VERSION ""

NS_ :

BS_:

BU_: VCM SCIM IC CCM

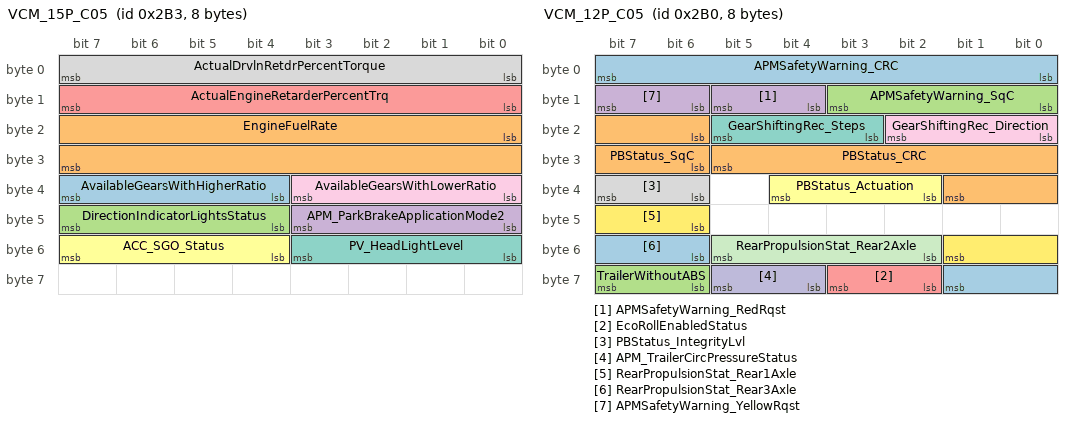
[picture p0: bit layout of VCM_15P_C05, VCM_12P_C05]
BO_ 691 VCM_15P_C05: 8 VCM
 SG_ AvailableGearsWithHigherRatio : 36|4@1+ (1,0) [0|15] "Count"  IC
 SG_ EngineFuelRate : 16|16@1+ (0.05,0) [0|3276.75] "l_per_h"  IC
 SG_ DirectionIndicatorLightsStatus : 44|4@1+ (1,0) [0|0] ""  IC
 SG_ APM_ParkBrakeApplicationMode2 : 40|4@1+ (1,0) [0|0] ""  IC
 SG_ ActualEngineRetarderPercentTrq : 8|8@1+ (1,-125) [-125|130] "Percent"  IC
 SG_ ACC_SGO_Status : 52|4@1+ (1,0) [0|0] ""  IC
 SG_ PV_HeadLightLevel : 48|4@1+ (1,-7) [-7|8] "NotApplicable"  IC
 SG_ ActualDrvlnRetdrPercentTorque : 0|8@1+ (1,-125) [-125|130] "Percent"  IC
 SG_ AvailableGearsWithLowerRatio : 32|4@1+ (1,0) [0|15] "Count"  IC

BO_ 690 VCM_14P_C05: 8 VCM
 SG_ SetHSAOperation : 49|3@1+ (1,0) [0|0] ""  IC
 SG_ PS_FogLightFront : 12|2@1+ (1,0) [0|0] ""  IC
 SG_ CACCStatus : 43|3@1+ (1,0) [0|0] ""  IC
 SG_ Cab12VSupplyStatus : 6|2@1+ (1,0) [0|0] ""  IC
 SG_ TransmissionDrivingMode : 22|3@1+ (1,0) [0|0] ""  IC
 SG_ LowAirPressureAlert : 10|2@1+ (1,0) [0|0] ""  IC
 SG_ TemporaryRSLSwitchStatus : 4|2@1+ (1,0) [0|0] ""  IC
 SG_ BatterySOCAlertRawData_rqst : 37|3@1+ (1,0) [0|0] ""  IC,CCM
 SG_ BatteryTempAlertRawData_rqst : 25|3@1+ (1,0) [0|0] ""  IC
 SG_ BrakeTemperatureWarning : 14|2@1+ (1,0) [0|0] ""  IC
 SG_ WheelSlipControllerMode : 16|3@1+ (1,0) [0|0] ""  IC
 SG_ Rainsensor_Indication : 0|2@1+ (1,0) [0|0] ""  IC
 SG_ ESCHealthStatus : 2|2@1+ (1,0) [0|0] ""  IC
 SG_ TLInflationAcceptance_stat : 31|3@1+ (1,0) [0|0] ""  IC
 SG_ AutoLoadCutOffState : 34|3@1+ (1,0) [0|0] ""  IC
 SG_ TransmissionOilTempHigh : 55|3@1+ (1,0) [0|0] ""  IC
 SG_ ECSLimpHomeNotification : 28|3@1+ (1,0) [0|0] ""  IC
 SG_ EqualizerUnbalance : 19|3@1+ (1,0) [0|0] ""  IC
 SG_ AutGearSplitPosition : 52|3@1+ (1,0) [0|0] ""  IC
 SG_ BatterySOCAlert_rqst : 46|3@1+ (1,0) [0|0] ""  IC
 SG_ DriveModeSwitchUserOverride : 58|3@1+ (1,0) [0|0] ""  IC
 SG_ BatteryTempAlert_rqst : 40|3@1+ (1,0) [0|0] ""  IC
 SG_ TrailerEBSFault : 8|2@1+ (1,0) [0|0] ""  IC

BO_ 689 VCM_13P_C05: 8 VCM
 SG_ ParkHeaterTimerReleased_stat : 54|2@1+ (1,0) [0|0] ""  CCM
 SG_ Trail2TPMLostCom : 2|2@1+ (1,0) [0|0] ""  IC
 SG_ BrakeInterlockStatus : 42|2@1+ (1,0) [0|0] ""  IC
 SG_ AutoWheelBrakesDownshiftSugges : 36|2@1+ (1,0) [0|0] ""  IC
 SG_ RearAxle2DiffLock_stat : 34|2@1+ (1,0) [0|0] ""  IC
 SG_ CentralRearDiffLock_stat : 16|2@1+ (1,0) [0|0] ""  IC
 SG_ TransmissionBrakeMode : 56|2@1+ (1,0) [0|0] ""  IC
 SG_ PS_HeadLightAdjustment : 14|2@1+ (1,0) [0|0] ""  IC
 SG_ ReducedLoadMode_stat : 62|2@1+ (1,0) [0|0] ""  IC,CCM
 SG_ FrontWheelDifflockRequest : 6|2@1+ (1,0) [0|0] ""  IC
 SG_ ABSEBSAmberWarningSignal : 44|2@1+ (1,0) [0|0] ""  IC
 SG_ DifferentialLockStateFrAxle1 : 32|2@1+ (1,0) [0|0] ""  IC
 SG_ Trail1TPMLostCom : 12|2@1+ (1,0) [0|0] ""  IC
 SG_ TrailerInflationPossible_stat : 50|2@1+ (1,0) [0|0] ""  IC
 SG_ DrivelineRetarderStat : 24|2@1+ (1,0) [0|0] ""  IC
 SG_ PS_FogLightRear : 4|2@1+ (1,0) [0|0] ""  IC
 SG_ PS_MainBeam : 22|2@1+ (1,0) [0|0] ""  IC
 SG_ DeCompActive : 26|2@1+ (1,0) [0|0] ""  IC
 SG_ ECSManStandbyStatus : 30|2@1+ (1,0) [0|0] ""  IC
 SG_ AutoPBRelease_stat : 46|2@1+ (1,0) [0|0] ""  IC
 SG_ Trail4TPMLostCom : 28|2@1+ (1,0) [0|0] ""  IC
 SG_ EBSRedWarningSignal : 40|2@1+ (1,0) [0|0] ""  IC
 SG_ DifferentialLockStateCentral : 52|2@1+ (1,0) [0|0] ""  IC
 SG_ RearAxle3DiffLock_stat : 20|2@1+ (1,0) [0|0] ""  IC
 SG_ AntiLockBrakingActive : 10|2@1+ (1,0) [0|0] ""  IC
 SG_ RearAxle1DiffLock_stat : 0|2@1+ (1,0) [0|0] ""  IC
 SG_ Trail5TPMLostCom : 48|2@1+ (1,0) [0|0] ""  IC
 SG_ PS_PositionLight : 58|2@1+ (1,0) [0|0] ""  IC
 SG_ BatteryCapacity_Ack : 8|2@1+ (1,0) [0|0] ""  IC
 SG_ Trail3TPMLostCom : 60|2@1+ (1,0) [0|0] ""  IC
 SG_ ParkBrakeWorkshopMode : 18|2@1+ (1,0) [0|0] ""  IC
 SG_ LowTempClutchInfo : 38|2@1+ (1,0) [0|0] ""  IC

BO_ 688 VCM_12P_C05: 8 VCM
 SG_ APMSafetyWarning_CRC : 0|8@1+ (1,0) [0|255] ""  IC
 SG_ PBStatus_CRC : 22|8@1+ (1,0) [0|255] ""  IC
 SG_ TrailerWithoutABS : 62|2@1+ (1,0) [0|0] ""  IC
 SG_ APMSafetyWarning_RedRqst : 12|2@1+ (1,0) [0|0] ""  IC
 SG_ EcoRollEnabledStatus : 58|2@1+ (1,0) [0|0] ""  IC
 SG_ PBStatus_Actuation : 34|3@1+ (1,0) [0|0] ""  IC
 SG_ GearShiftingRec_Steps : 19|3@1+ (1,0) [0|0] ""  IC
 SG_ PBStatus_IntegrityLvl : 38|2@1+ (1,0) [0|0] ""  IC
 SG_ GearShiftingRec_Direction : 16|3@1+ (1,0) [0|0] ""  IC
 SG_ APM_TrailerCircPressureStatus : 60|2@1+ (1,0) [0|0] ""  IC
 SG_ RearPropulsionStat_Rear2Axle : 50|4@1+ (1,0) [0|0] ""  IC
 SG_ RearPropulsionStat_Rear1Axle : 46|4@1+ (1,0) [0|0] ""  IC
 SG_ RearPropulsionStat_Rear3Axle : 54|4@1+ (1,0) [0|0] ""  IC
 SG_ PBStatus_SqC : 30|4@1+ (1,0) [0|14] "NotApplicable"  IC
 SG_ APMSafetyWarning_SqC : 8|4@1+ (1,0) [0|14] "NotApplicable"  IC
 SG_ APMSafetyWarning_YellowRqst : 14|2@1+ (1,0) [0|0] ""  IC

BO_ 394 VCM_11P_C05: 8 VCM
 SG_ LongitudinalAcceleration : 0|16@1+ (0.00048828125,-15.687) [-15.687|16.31251171875] "m_per_s_squared"  IC
 SG_ CCSetSpeed : 16|16@1+ (0.00390625,0) [0|255.99609375] "Km_per_h"  IC

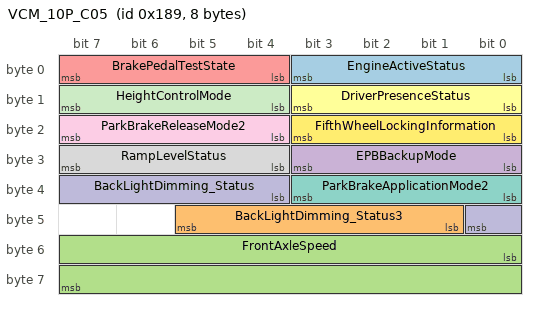
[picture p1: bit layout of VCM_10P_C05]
BO_ 393 VCM_10P_C05: 8 VCM
 SG_ EngineActiveStatus : 0|4@1+ (1,0) [0|0] ""  IC
 SG_ BackLightDimming_Status3 : 41|5@1+ (1,0) [0|0] ""  IC
 SG_ FrontAxleSpeed : 48|16@1+ (0.00390625,0) [0|255.99609375] "Km_per_h"  IC
 SG_ EPBBackupMode : 24|4@1+ (1,0) [0|0] ""  IC
 SG_ BrakePedalTestState : 4|4@1+ (1,0) [0|0] ""  IC
 SG_ DriverPresenceStatus : 8|4@1+ (1,0) [0|0] ""  IC
 SG_ ParkBrakeApplicationMode2 : 32|4@1+ (1,0) [0|0] ""  IC
 SG_ RampLevelStatus : 28|4@1+ (1,0) [0|0] ""  IC
 SG_ ParkBrakeReleaseMode2 : 20|4@1+ (1,0) [0|0] ""  IC
 SG_ BackLightDimming_Status : 36|5@1+ (1,0) [0|0] ""  IC
 SG_ HeightControlMode : 12|4@1+ (1,0) [0|0] ""  IC
 SG_ FifthWheelLockingInformation : 16|4@1+ (1,0) [0|0] ""  IC

BO_ 392 VCM_09P_C05: 8 VCM
 SG_ FirstAxleLowerPrioSelected : 48|3@1+ (1,0) [0|0] ""  IC
 SG_ ESCState : 24|3@1+ (1,0) [0|0] ""  IC
 SG_ KneelingInformation : 60|4@1+ (1,0) [0|0] ""  IC
 SG_ TrailerTest_stat : 42|3@1+ (1,0) [0|0] ""  IC
 SG_ ThreePosDifflockSwitch_stat : 3|3@1+ (1,0) [0|0] ""  IC
 SG_ HillHolderMode : 36|3@1+ (1,0) [0|0] ""  IC
 SG_ RampHeightOutsideTargetRange : 21|3@1+ (1,0) [0|0] ""  IC
 SG_ ShortStopHeater_status : 39|3@1+ (1,0) [0|0] ""  CCM
 SG_ LuggageAjar_stat : 15|3@1+ (1,0) [0|0] ""  IC
 SG_ LoadDistributionRequestedACK : 12|3@1+ (1,0) [0|0] ""  IC
 SG_ StretchBrake_Stat : 54|3@1+ (1,0) [0|0] ""  IC
 SG_ MirrorHeatingMode : 9|3@1+ (1,0) [0|0] ""  IC,CCM
 SG_ ESCStatus : 6|3@1+ (1,0) [0|0] ""  IC
 SG_ DriverRetarderRequest : 30|3@1+ (1,0) [0|0] ""  IC
 SG_ PBReleaseAcceptance_stat : 18|3@1+ (1,0) [0|0] ""  IC
 SG_ PSWindowPosition : 0|3@1+ (1,0) [0|0] ""  CCM
 SG_ RemoteParkingClimateRqst : 57|3@1+ (1,0) [0|0] ""  CCM
 SG_ AutoDefogmode_Status : 33|3@1+ (1,0) [0|0] ""  IC
 SG_ RideHeightOutsideTargetRange : 27|3@1+ (1,0) [0|0] ""  IC
 SG_ DriveLevelPosUserInteraction : 45|3@1+ (1,0) [0|0] ""  IC
 SG_ HillStartAidStatus : 51|3@1+ (1,0) [0|0] ""  IC

BO_ 391 VCM_08P_C05: 8 VCM
 SG_ AcceleratorPedalTestStatus : 38|3@1+ (1,0) [0|0] ""  IC
 SG_ AutoDefogmode_Selection : 14|3@1+ (1,0) [0|0] ""  CCM
 SG_ ESCDriverReq : 41|3@1+ (1,0) [0|0] ""  IC
 SG_ UnevenLoadWarning : 12|2@1+ (1,0) [0|0] ""  IC
 SG_ RrInterAxlDiffLockActvnFuncReq : 4|2@1+ (1,0) [0|0] ""  IC
 SG_ DoorsAjar_stat : 44|3@1+ (1,0) [0|0] ""  IC
 SG_ ABSManAutoInhibitionStat : 50|3@1+ (1,0) [0|0] ""  IC
 SG_ RrInterAxlDiffLockActvnDrvrReq : 2|2@1+ (1,0) [0|0] ""  IC
 SG_ ACMode_Selection : 17|3@1+ (1,0) [0|0] ""  CCM
 SG_ EngineOilTempHigh : 59|3@1+ (1,0) [0|0] ""  IC
 SG_ StartupProhibitStatus : 0|2@1+ (1,0) [0|0] ""  IC
 SG_ AuxBrakesDwngrdModeInd_rqst : 26|3@1+ (1,0) [0|0] ""  IC
 SG_ ElectricalLoadReduction_rqst : 32|3@1+ (1,0) [0|0] ""  CCM
 SG_ ACmode_Status : 56|3@1+ (1,0) [0|0] ""  IC
 SG_ LoadDistributionChangeACK : 20|3@1+ (1,0) [0|0] ""  IC
 SG_ FerryFunctionStatus : 29|3@1+ (1,0) [0|0] ""  IC
 SG_ ClutchOverloadStatus : 10|2@1+ (1,0) [0|0] ""  IC
 SG_ AutoBlowerLevel_Selection : 23|3@1+ (1,0) [0|0] ""  CCM
 SG_ RollerBenchModeStatus : 6|2@1+ (1,0) [0|0] ""  IC
 SG_ LoadDistributionALDChangeACK : 35|3@1+ (1,0) [0|0] ""  IC
 SG_ EngineSpeedControlStatus : 47|3@1+ (1,0) [0|0] ""  IC
 SG_ AutoBlowerLevel_Status : 53|3@1+ (1,0) [0|0] ""  IC
 SG_ DTCActive : 8|2@1+ (1,0) [0|0] ""  IC

BO_ 390 VCM_07P_C05: 8 VCM
 SG_ PS_SevereEngAndBrkOverspdWarn : 6|2@1+ (1,0) [0|0] ""  IC
 SG_ RearFog_Indication : 14|2@1+ (1,0) [0|0] ""  SCIM
 SG_ SasAdaptationInProgress : 46|2@1+ (1,0) [0|0] ""  IC
 SG_ SplitBoxDifflockActvnDrvrRqst : 50|2@1+ (1,0) [0|0] ""  IC
 SG_ EcoRollActiveStatus : 36|2@1+ (1,0) [0|0] ""  IC
 SG_ PloughLampModeStatus : 40|2@1+ (1,0) [0|0] ""  IC
 SG_ RrRrItrWhlDiffLckActvnDrvrReq : 26|2@1+ (1,0) [0|0] ""  IC
 SG_ AQSMode_Selection : 0|2@1+ (1,0) [0|0] ""  CCM
 SG_ DrvrRetarderBrakeProgram_rqst : 62|2@1+ (1,0) [0|0] ""  IC
 SG_ PS_EngOverSpeedSevereWarning : 38|2@1+ (1,0) [0|0] ""  IC
 SG_ ParkBrakeReleasePossible_stat : 32|2@1+ (1,0) [0|0] ""  IC
 SG_ StoreIdleValue : 34|2@1+ (1,0) [0|0] ""  IC
 SG_ AutRrAxleDiffLockActvnDrvrReq : 42|2@1+ (1,0) [0|0] ""  IC
 SG_ TransmLowRangeSenseSwitch : 28|2@1+ (1,0) [0|0] ""  IC
 SG_ PBStatusDisplay_cmd : 44|2@1+ (1,0) [0|0] ""  IC
 SG_ AutoRearAxleDiffLockFnc_stat : 56|2@1+ (1,0) [0|0] ""  IC
 SG_ PoorBrakePerformanceWarning : 8|2@1+ (1,0) [0|0] ""  IC
 SG_ AQSmode_Status : 22|2@1+ (1,0) [0|0] ""  IC
 SG_ CCIOM_ParkBrakeAlert : 4|2@1+ (1,0) [0|0] ""  IC
 SG_ FrontParkBrakeOverrideInd : 52|2@1+ (1,0) [0|0] ""  IC
 SG_ ProhibitControlStatus : 10|2@1+ (1,0) [0|0] ""  IC
 SG_ PositionLightRequest_status : 2|2@1+ (1,0) [0|0] ""  IC
 SG_ DoubleFrontAxleSteeringWarning : 54|2@1+ (1,0) [0|0] ""  IC
 SG_ TrailerABSStatus : 20|2@1+ (1,0) [0|0] ""  IC
 SG_ LoadCutOffIndication_cmd : 60|2@1+ (1,0) [0|0] ""  IC
 SG_ PtosStatus : 12|2@1+ (1,0) [0|0] ""  CCM
 SG_ REM_PhoneButtonInd_cmd : 58|2@1+ (1,0) [0|0] ""  IC
 SG_ TrailerBrake_Stat : 48|2@1+ (1,0) [0|0] ""  IC
 SG_ SEM2_PhoneButtonInd_cmd : 30|2@1+ (1,0) [0|0] ""  IC
 SG_ GearRangeUnengaged : 16|2@1+ (1,0) [0|0] ""  IC
 SG_ ABSOffRoadStatus : 24|2@1+ (1,0) [0|0] ""  IC
 SG_ DrvrRetarderBrakeBlending_rqst : 18|2@1+ (1,0) [0|0] ""  IC

BO_ 389 VCM_06P_C05: 8 VCM
 SG_ XPRGSystemCap_Priority : 12|3@1+ (1,0) [0|0] ""  IC
 SG_ XPRGSystemCap_AllowedRelInhibit : 15|1@1+ (1,0) [0|0] ""  IC
 SG_ PHTimerRqstAck_Minutes : 24|8@1+ (1,0) [0|255] "min"  CCM
 SG_ RearAxleDiffLockActvnDrvrReq : 56|2@1+ (1,0) [0|0] ""  IC
 SG_ FrRrItrWhlDiffLckActvnDrvrReq : 46|2@1+ (1,0) [0|0] ""  IC
 SG_ XPRGSystemCap_AllowedGradCtrlTc : 19|1@1+ (1,0) [0|0] ""  IC
 SG_ XPRGSystemCap_AllowedGradCtrlTl : 17|1@1+ (1,0) [0|0] ""  IC
 SG_ RegenInhibDueHeight : 48|2@1+ (1,0) [0|0] ""  IC
 SG_ PHTimerRqstAck_Hours : 32|8@1+ (1,0) [0|255] "h"  CCM
 SG_ PoorAirPressureInfo : 60|2@1+ (1,0) [0|0] ""  IC
 SG_ XPRGSystemCap_AllowedPBApp : 21|1@1+ (1,0) [0|0] ""  IC
 SG_ XRSLControllerMode : 52|2@1+ (1,0) [0|0] ""  IC
 SG_ XPRGSystemCap_CRC : 0|8@1+ (1,0) [0|255] ""  IC
 SG_ XPRGSystemCap_AllowedInflation : 20|1@1+ (1,0) [0|0] ""  IC
 SG_ XPRGSystemCap_SqC : 8|4@1+ (1,0) [0|14] "NotApplicable"  IC
 SG_ PHTimerRqstAck_DayOfWeekRq : 40|4@1+ (1,0) [0|0] ""  CCM
 SG_ VIN_rqst : 62|1@1+ (1,0) [0|0] ""  IC
 SG_ PHTimerRqstAck_CurrentOp : 44|2@1+ (1,0) [0|0] ""  CCM
 SG_ PS_EngineBrakeOverSpeedWarning : 58|2@1+ (1,0) [0|0] ""  IC
 SG_ XPRGSystemCap_AllowedDeflation : 22|1@1+ (1,0) [0|0] ""  IC
 SG_ XPRGSystemCap_AllowedInfInhibit : 16|1@1+ (1,0) [0|0] ""  IC
 SG_ TrcnCtrlSlipperyRoadWarning : 50|2@1+ (1,0) [0|0] ""  IC
 SG_ XPRGSystemCap_AllowedPBRel : 18|1@1+ (1,0) [0|0] ""  IC
 SG_ TransmissionAirPressureLow : 54|2@1+ (1,0) [0|0] ""  IC

BO_ 158 VCM_05P_C05: 8 VCM
 SG_ SecuredNeutralPosition : 38|2@1+ (1,0) [0|0] ""  IC
 SG_ MirrorSelectLeftWideBtn_stat : 28|2@1+ (1,0) [0|0] ""  IC
 SG_ Recirc_ButtonStatus : 6|2@1+ (1,0) [0|0] ""  IC
 SG_ AirFlowSelectionUpBtn_stat : 18|2@1+ (1,0) [0|0] ""  IC
 SG_ BunkH1AudioOnOff_ButtonStatus : 30|2@1+ (1,0) [0|0] ""  IC
 SG_ AC_ButtonStatus : 42|2@1+ (1,0) [0|0] ""  IC
 SG_ OverSteerGuidanceStatus : 10|2@1+ (1,0) [0|0] ""  IC
 SG_ MirrorSelectLeftMainBtn_stat : 44|2@1+ (1,0) [0|0] ""  IC
 SG_ LECM_CabClim_Auto_BtnStat : 36|2@1+ (1,0) [0|0] ""  IC
 SG_ ParkBrakeAlert : 56|2@1+ (1,0) [0|0] ""  IC
 SG_ LECM_Display_Navi_OK_BtnStat : 20|2@1+ (1,0) [0|0] ""  IC
 SG_ LECM_CabClim_AC_BtnStat : 46|2@1+ (1,0) [0|0] ""  IC
 SG_ LECMCabClimSetTempSelectGuiReq : 22|2@1+ (1,0) [0|0] ""  IC
 SG_ MirrorSelectRightMainBtn_stat : 50|2@1+ (1,0) [0|0] ""  IC
 SG_ DaytimeRunningLight_Indication : 24|2@1+ (1,0) [0|0] ""  SCIM
 SG_ DrivingLight_Indication : 58|2@1+ (1,0) [0|0] ""  SCIM
 SG_ FrontFog_Indication : 32|2@1+ (1,0) [0|0] ""  SCIM
 SG_ Auto_ButtonStatus : 48|2@1+ (1,0) [0|0] ""  IC
 SG_ KeyfobPreTripButtonStatus : 4|2@1+ (1,0) [0|0] ""  IC
 SG_ MirrorSelectRightWideBtn_stat : 26|2@1+ (1,0) [0|0] ""  IC
 SG_ ParkingLight_Indication : 2|2@1+ (1,0) [0|0] ""  SCIM
 SG_ DrivingLightPlus_Indication : 60|2@1+ (1,0) [0|0] ""  SCIM
 SG_ BlackPanelMode_ButtonStatus : 14|2@1+ (1,0) [0|0] ""  IC
 SG_ ParkHeaterCooler_ButtonStatus : 16|2@1+ (1,0) [0|0] ""  IC
 SG_ LECM_CabClim_FrPwr_BtnStat : 34|2@1+ (1,0) [0|0] ""  IC
 SG_ LECM_CabClim_Pwr_BtnStat : 0|2@1+ (1,0) [0|0] ""  IC
 SG_ AirFlowSelectionFrontBtn_stat : 12|2@1+ (1,0) [0|0] ""  IC
 SG_ BlackPanelMode_ButtonStatus3 : 8|2@1+ (1,0) [0|0] ""  IC
 SG_ LECM_CabClim_Sync_GuiReq : 40|2@1+ (1,0) [0|0] ""  IC
 SG_ LiftAxle1AutoLiftSelected : 54|2@1+ (1,0) [0|0] ""  IC
 SG_ LECM_Ent_OnOff_BtnStat : 52|2@1+ (1,0) [0|0] ""  IC

BA_DEF_ BO_  "GenMsgStartDelayTime" INT 0 0;
BA_DEF_ BO_  "GenMsgDelayTime" INT 0 0;
BA_DEF_ BO_  "GenMsgCycleTime" INT 0 0;
BA_DEF_ BO_  "GenMsgSendType" ENUM  "Cyclic","NotUsed","NotUsed","NotUsed","NotUsed","NotUsed","NotUsed","IfActive","NoMsgSendType","NotUsed";
BA_DEF_ SG_  "GenSigStartValue" INT 0 0;
BA_DEF_ SG_  "GenSigCycleTimeActive" INT 0 0;
BA_DEF_ SG_  "GenSigCycleTime" INT 0 0;
BA_DEF_ SG_  "GenSigSendType" ENUM  "Cyclic","OnWrite","OnWriteWithRepetition","OnChange","OnChangeWithRepetition","IfActive","IfActiveWithRepetition","NoSigSendType","NotUsed","NotUsed","NotUsed","NotUsed","NotUsed";
BA_DEF_ BO_  "VFrameFormat" ENUM  "StandardCAN","ExtendedCAN","reserved","J1939PG","reserved","reserved","reserved","reserved","reserved","reserved","reserved","reserved","reserved","reserved","StandardCAN_FD","ExtendedCAN_FD";
BA_DEF_ SG_  "SigType" ENUM  "Default","Range","RangeSigned","ASCII","Discrete","Control","ReferencePGN","DTC","StringDelimiter","StringLength","StringLengthControl";
BA_DEF_ BO_  "NmAsrMessage" ENUM  "No","Yes";
BA_DEF_ SG_  "NeedsUpdateBit" ENUM  "No","Yes";
BA_DEF_ SG_  "MmAnSignal" ENUM  "No","Yes";
BA_DEF_ SG_  "GenSigMaxLatency" INT 0 65535;
BA_DEF_ SG_  "GenSigILSupport" ENUM  "Yes","No";
BA_DEF_ BO_  "GenMsgILSupport" ENUM  "No","Yes";
BA_DEF_ SG_  "E2EProfile" STRING ;
BA_DEF_ SG_  "E2EDataLength" INT 0 65535;
BA_DEF_ SG_  "E2EDataId" INT 0 65535;
BA_DEF_ BO_  "DiagUUDTResponse" ENUM  "No","Yes";
BA_DEF_ BO_  "DiagState" ENUM  "No","Yes";
BA_DEF_ BO_  "DiagResponse" ENUM  "No","Yes";
BA_DEF_ BO_  "DiagRequest" ENUM  "No","Yes";
BA_DEF_ BO_  "DiagConnection" HEX 0 65535;
BA_DEF_ BO_  "CanTpFcFrameId" HEX 0 2147483647;
BA_DEF_ BO_  "CanTpBs" INT 0 255;
BA_DEF_REL_ BU_SG_REL_  "GenSigTimeoutTime" INT 0 65535;
BA_DEF_REL_ BU_SG_REL_  "GenSigFirstTimeoutTime" INT 0 65535;
BA_DEF_DEF_  "GenMsgStartDelayTime" 0;
BA_DEF_DEF_  "GenMsgDelayTime" 0;
BA_DEF_DEF_  "GenMsgCycleTime" 0;
BA_DEF_DEF_  "GenMsgSendType" "Cyclic";
BA_DEF_DEF_  "GenSigStartValue" 0;
BA_DEF_DEF_  "GenSigCycleTimeActive" 0;
BA_DEF_DEF_  "GenSigCycleTime" 0;
BA_DEF_DEF_  "GenSigSendType" "Cyclic";
BA_DEF_DEF_  "VFrameFormat" "ExtendedCAN";
BA_DEF_DEF_  "SigType" "Default";
BA_DEF_DEF_  "NmAsrMessage" "No";
BA_DEF_DEF_  "NeedsUpdateBit" "No";
BA_DEF_DEF_  "MmAnSignal" "No";
BA_DEF_DEF_  "GenSigMaxLatency" 0;
BA_DEF_DEF_  "GenSigILSupport" "Yes";
BA_DEF_DEF_  "GenMsgILSupport" "Yes";
BA_DEF_DEF_  "E2EProfile" "none";
BA_DEF_DEF_  "E2EDataLength" 0;
BA_DEF_DEF_  "E2EDataId" 0;
BA_DEF_DEF_  "DiagUUDTResponse" "No";
BA_DEF_DEF_  "DiagState" "No";
BA_DEF_DEF_  "DiagResponse" "No";
BA_DEF_DEF_  "DiagRequest" "No";
BA_DEF_DEF_  "DiagConnection" 0;
BA_DEF_DEF_  "CanTpFcFrameId" 2147483647;
BA_DEF_DEF_  "CanTpBs" 255;
BA_DEF_DEF_REL_ "GenSigTimeoutTime" 0;
BA_DEF_DEF_REL_ "GenSigFirstTimeoutTime" 0;
BA_ "VFrameFormat" BO_ 691 0;
BA_ "GenMsgCycleTime" BO_ 691 100;
BA_ "VFrameFormat" BO_ 690 0;
BA_ "GenMsgCycleTime" BO_ 690 100;
BA_ "VFrameFormat" BO_ 689 0;
BA_ "GenMsgCycleTime" BO_ 689 100;
BA_ "VFrameFormat" BO_ 688 0;
BA_ "GenMsgCycleTime" BO_ 688 100;
BA_ "VFrameFormat" BO_ 394 0;
BA_ "GenMsgCycleTime" BO_ 394 50;
BA_ "VFrameFormat" BO_ 393 0;
BA_ "GenMsgCycleTime" BO_ 393 50;
BA_ "VFrameFormat" BO_ 392 0;
BA_ "GenMsgCycleTime" BO_ 392 50;
BA_ "VFrameFormat" BO_ 391 0;
BA_ "GenMsgCycleTime" BO_ 391 50;
BA_ "VFrameFormat" BO_ 390 0;
BA_ "GenMsgCycleTime" BO_ 390 50;
BA_ "VFrameFormat" BO_ 389 0;
BA_ "GenMsgCycleTime" BO_ 389 50;
BA_ "VFrameFormat" BO_ 158 0;
BA_ "GenMsgCycleTime" BO_ 158 20;
BA_ "GenSigCycleTime" SG_ 691 AvailableGearsWithHigherRatio 100;
BA_ "GenSigCycleTimeActive" SG_ 691 AvailableGearsWithHigherRatio 100;
BA_ "GenSigStartValue" SG_ 691 AvailableGearsWithHigherRatio 15;
BA_ "GenSigMaxLatency" SG_ 691 AvailableGearsWithHigherRatio 100;
BA_ "GenSigCycleTime" SG_ 691 EngineFuelRate 100;
BA_ "GenSigCycleTimeActive" SG_ 691 EngineFuelRate 100;
BA_ "GenSigStartValue" SG_ 691 EngineFuelRate 65535;
BA_ "GenSigMaxLatency" SG_ 691 EngineFuelRate 100;
BA_ "GenSigCycleTime" SG_ 691 DirectionIndicatorLightsStatus 100;
BA_ "GenSigCycleTimeActive" SG_ 691 DirectionIndicatorLightsStatus 100;
BA_ "GenSigStartValue" SG_ 691 DirectionIndicatorLightsStatus 15;
BA_ "GenSigMaxLatency" SG_ 691 DirectionIndicatorLightsStatus 100;
BA_ "GenSigCycleTime" SG_ 691 APM_ParkBrakeApplicationMode2 100;
BA_ "GenSigCycleTimeActive" SG_ 691 APM_ParkBrakeApplicationMode2 100;
BA_ "GenSigStartValue" SG_ 691 APM_ParkBrakeApplicationMode2 15;
BA_ "GenSigMaxLatency" SG_ 691 APM_ParkBrakeApplicationMode2 100;
BA_ "GenSigCycleTime" SG_ 691 ActualEngineRetarderPercentTrq 100;
BA_ "GenSigCycleTimeActive" SG_ 691 ActualEngineRetarderPercentTrq 100;
BA_ "GenSigStartValue" SG_ 691 ActualEngineRetarderPercentTrq 255;
BA_ "GenSigMaxLatency" SG_ 691 ActualEngineRetarderPercentTrq 100;
BA_ "GenSigCycleTime" SG_ 691 ACC_SGO_Status 100;
BA_ "GenSigCycleTimeActive" SG_ 691 ACC_SGO_Status 100;
BA_ "GenSigStartValue" SG_ 691 ACC_SGO_Status 15;
BA_ "GenSigMaxLatency" SG_ 691 ACC_SGO_Status 100;
BA_ "GenSigCycleTime" SG_ 691 PV_HeadLightLevel 100;
BA_ "GenSigCycleTimeActive" SG_ 691 PV_HeadLightLevel 100;
BA_ "GenSigStartValue" SG_ 691 PV_HeadLightLevel 15;
BA_ "GenSigMaxLatency" SG_ 691 PV_HeadLightLevel 100;
BA_ "GenSigCycleTime" SG_ 691 ActualDrvlnRetdrPercentTorque 100;
BA_ "GenSigCycleTimeActive" SG_ 691 ActualDrvlnRetdrPercentTorque 100;
BA_ "GenSigStartValue" SG_ 691 ActualDrvlnRetdrPercentTorque 255;
BA_ "GenSigMaxLatency" SG_ 691 ActualDrvlnRetdrPercentTorque 100;
BA_ "GenSigCycleTime" SG_ 691 AvailableGearsWithLowerRatio 100;
BA_ "GenSigCycleTimeActive" SG_ 691 AvailableGearsWithLowerRatio 100;
BA_ "GenSigStartValue" SG_ 691 AvailableGearsWithLowerRatio 15;
BA_ "GenSigMaxLatency" SG_ 691 AvailableGearsWithLowerRatio 100;
BA_ "GenSigCycleTime" SG_ 690 SetHSAOperation 100;
BA_ "GenSigCycleTimeActive" SG_ 690 SetHSAOperation 100;
BA_ "GenSigStartValue" SG_ 690 SetHSAOperation 7;
BA_ "GenSigMaxLatency" SG_ 690 SetHSAOperation 100;
BA_ "GenSigCycleTime" SG_ 690 PS_FogLightFront 100;
BA_ "GenSigCycleTimeActive" SG_ 690 PS_FogLightFront 100;
BA_ "GenSigStartValue" SG_ 690 PS_FogLightFront 3;
BA_ "GenSigMaxLatency" SG_ 690 PS_FogLightFront 100;
BA_ "GenSigCycleTime" SG_ 690 CACCStatus 100;
BA_ "GenSigCycleTimeActive" SG_ 690 CACCStatus 100;
BA_ "GenSigStartValue" SG_ 690 CACCStatus 7;
BA_ "GenSigMaxLatency" SG_ 690 CACCStatus 100;
BA_ "GenSigCycleTime" SG_ 690 Cab12VSupplyStatus 100;
BA_ "GenSigCycleTimeActive" SG_ 690 Cab12VSupplyStatus 100;
BA_ "GenSigStartValue" SG_ 690 Cab12VSupplyStatus 3;
BA_ "GenSigMaxLatency" SG_ 690 Cab12VSupplyStatus 100;
BA_ "GenSigCycleTime" SG_ 690 TransmissionDrivingMode 100;
BA_ "GenSigCycleTimeActive" SG_ 690 TransmissionDrivingMode 100;
BA_ "GenSigStartValue" SG_ 690 TransmissionDrivingMode 7;
BA_ "GenSigMaxLatency" SG_ 690 TransmissionDrivingMode 100;
BA_ "GenSigCycleTime" SG_ 690 LowAirPressureAlert 100;
BA_ "GenSigCycleTimeActive" SG_ 690 LowAirPressureAlert 100;
BA_ "GenSigStartValue" SG_ 690 LowAirPressureAlert 3;
BA_ "GenSigMaxLatency" SG_ 690 LowAirPressureAlert 100;
BA_ "GenSigCycleTime" SG_ 690 TemporaryRSLSwitchStatus 100;
BA_ "GenSigCycleTimeActive" SG_ 690 TemporaryRSLSwitchStatus 100;
BA_ "GenSigStartValue" SG_ 690 TemporaryRSLSwitchStatus 3;
BA_ "GenSigMaxLatency" SG_ 690 TemporaryRSLSwitchStatus 100;
BA_ "GenSigCycleTime" SG_ 690 BatterySOCAlertRawData_rqst 100;
BA_ "GenSigCycleTimeActive" SG_ 690 BatterySOCAlertRawData_rqst 100;
BA_ "GenSigStartValue" SG_ 690 BatterySOCAlertRawData_rqst 7;
BA_ "GenSigMaxLatency" SG_ 690 BatterySOCAlertRawData_rqst 100;
BA_ "GenSigCycleTime" SG_ 690 BatteryTempAlertRawData_rqst 100;
BA_ "GenSigCycleTimeActive" SG_ 690 BatteryTempAlertRawData_rqst 100;
BA_ "GenSigStartValue" SG_ 690 BatteryTempAlertRawData_rqst 7;
BA_ "GenSigMaxLatency" SG_ 690 BatteryTempAlertRawData_rqst 100;
BA_ "GenSigCycleTime" SG_ 690 BrakeTemperatureWarning 100;
BA_ "GenSigCycleTimeActive" SG_ 690 BrakeTemperatureWarning 100;
BA_ "GenSigStartValue" SG_ 690 BrakeTemperatureWarning 3;
BA_ "GenSigMaxLatency" SG_ 690 BrakeTemperatureWarning 100;
BA_ "GenSigCycleTime" SG_ 690 WheelSlipControllerMode 100;
BA_ "GenSigCycleTimeActive" SG_ 690 WheelSlipControllerMode 100;
BA_ "GenSigStartValue" SG_ 690 WheelSlipControllerMode 7;
BA_ "GenSigMaxLatency" SG_ 690 WheelSlipControllerMode 100;
BA_ "GenSigCycleTime" SG_ 690 Rainsensor_Indication 100;
BA_ "GenSigCycleTimeActive" SG_ 690 Rainsensor_Indication 100;
BA_ "GenSigStartValue" SG_ 690 Rainsensor_Indication 3;
BA_ "GenSigMaxLatency" SG_ 690 Rainsensor_Indication 100;
BA_ "GenSigCycleTime" SG_ 690 ESCHealthStatus 100;
BA_ "GenSigCycleTimeActive" SG_ 690 ESCHealthStatus 100;
BA_ "GenSigStartValue" SG_ 690 ESCHealthStatus 3;
BA_ "GenSigMaxLatency" SG_ 690 ESCHealthStatus 100;
BA_ "GenSigCycleTime" SG_ 690 TLInflationAcceptance_stat 100;
BA_ "GenSigCycleTimeActive" SG_ 690 TLInflationAcceptance_stat 100;
BA_ "GenSigStartValue" SG_ 690 TLInflationAcceptance_stat 7;
BA_ "GenSigMaxLatency" SG_ 690 TLInflationAcceptance_stat 100;
BA_ "GenSigCycleTime" SG_ 690 AutoLoadCutOffState 100;
BA_ "GenSigCycleTimeActive" SG_ 690 AutoLoadCutOffState 100;
BA_ "GenSigStartValue" SG_ 690 AutoLoadCutOffState 7;
BA_ "GenSigMaxLatency" SG_ 690 AutoLoadCutOffState 100;
BA_ "GenSigCycleTime" SG_ 690 TransmissionOilTempHigh 100;
BA_ "GenSigCycleTimeActive" SG_ 690 TransmissionOilTempHigh 100;
BA_ "GenSigStartValue" SG_ 690 TransmissionOilTempHigh 7;
BA_ "GenSigMaxLatency" SG_ 690 TransmissionOilTempHigh 100;
BA_ "GenSigCycleTime" SG_ 690 ECSLimpHomeNotification 100;
BA_ "GenSigCycleTimeActive" SG_ 690 ECSLimpHomeNotification 100;
BA_ "GenSigStartValue" SG_ 690 ECSLimpHomeNotification 7;
BA_ "GenSigMaxLatency" SG_ 690 ECSLimpHomeNotification 100;
BA_ "GenSigCycleTime" SG_ 690 EqualizerUnbalance 100;
BA_ "GenSigCycleTimeActive" SG_ 690 EqualizerUnbalance 100;
BA_ "GenSigStartValue" SG_ 690 EqualizerUnbalance 7;
BA_ "GenSigMaxLatency" SG_ 690 EqualizerUnbalance 100;
BA_ "GenSigCycleTime" SG_ 690 AutGearSplitPosition 100;
BA_ "GenSigCycleTimeActive" SG_ 690 AutGearSplitPosition 100;
BA_ "GenSigStartValue" SG_ 690 AutGearSplitPosition 7;
BA_ "GenSigMaxLatency" SG_ 690 AutGearSplitPosition 100;
BA_ "GenSigCycleTime" SG_ 690 BatterySOCAlert_rqst 100;
BA_ "GenSigCycleTimeActive" SG_ 690 BatterySOCAlert_rqst 100;
BA_ "GenSigStartValue" SG_ 690 BatterySOCAlert_rqst 7;
BA_ "GenSigMaxLatency" SG_ 690 BatterySOCAlert_rqst 100;
BA_ "GenSigCycleTime" SG_ 690 DriveModeSwitchUserOverride 100;
BA_ "GenSigCycleTimeActive" SG_ 690 DriveModeSwitchUserOverride 100;
BA_ "GenSigStartValue" SG_ 690 DriveModeSwitchUserOverride 7;
BA_ "GenSigMaxLatency" SG_ 690 DriveModeSwitchUserOverride 100;
BA_ "GenSigCycleTime" SG_ 690 BatteryTempAlert_rqst 100;
BA_ "GenSigCycleTimeActive" SG_ 690 BatteryTempAlert_rqst 100;
BA_ "GenSigStartValue" SG_ 690 BatteryTempAlert_rqst 7;
BA_ "GenSigMaxLatency" SG_ 690 BatteryTempAlert_rqst 100;
BA_ "GenSigCycleTime" SG_ 690 TrailerEBSFault 100;
BA_ "GenSigCycleTimeActive" SG_ 690 TrailerEBSFault 100;
BA_ "GenSigStartValue" SG_ 690 TrailerEBSFault 3;
BA_ "GenSigMaxLatency" SG_ 690 TrailerEBSFault 100;
BA_ "GenSigCycleTime" SG_ 689 ParkHeaterTimerReleased_stat 100;
BA_ "GenSigCycleTimeActive" SG_ 689 ParkHeaterTimerReleased_stat 100;
BA_ "GenSigStartValue" SG_ 689 ParkHeaterTimerReleased_stat 3;
BA_ "GenSigMaxLatency" SG_ 689 ParkHeaterTimerReleased_stat 100;
BA_ "GenSigCycleTime" SG_ 689 Trail2TPMLostCom 100;
BA_ "GenSigCycleTimeActive" SG_ 689 Trail2TPMLostCom 100;
BA_ "GenSigStartValue" SG_ 689 Trail2TPMLostCom 3;
BA_ "GenSigMaxLatency" SG_ 689 Trail2TPMLostCom 100;
BA_ "GenSigCycleTime" SG_ 689 BrakeInterlockStatus 100;
BA_ "GenSigCycleTimeActive" SG_ 689 BrakeInterlockStatus 100;
BA_ "GenSigStartValue" SG_ 689 BrakeInterlockStatus 3;
BA_ "GenSigMaxLatency" SG_ 689 BrakeInterlockStatus 100;
BA_ "GenSigCycleTime" SG_ 689 AutoWheelBrakesDownshiftSugges 100;
BA_ "GenSigCycleTimeActive" SG_ 689 AutoWheelBrakesDownshiftSugges 100;
BA_ "GenSigStartValue" SG_ 689 AutoWheelBrakesDownshiftSugges 3;
BA_ "GenSigMaxLatency" SG_ 689 AutoWheelBrakesDownshiftSugges 100;
BA_ "GenSigCycleTime" SG_ 689 RearAxle2DiffLock_stat 100;
BA_ "GenSigCycleTimeActive" SG_ 689 RearAxle2DiffLock_stat 100;
BA_ "GenSigStartValue" SG_ 689 RearAxle2DiffLock_stat 3;
BA_ "GenSigMaxLatency" SG_ 689 RearAxle2DiffLock_stat 100;
BA_ "GenSigCycleTime" SG_ 689 CentralRearDiffLock_stat 100;
BA_ "GenSigCycleTimeActive" SG_ 689 CentralRearDiffLock_stat 100;
BA_ "GenSigStartValue" SG_ 689 CentralRearDiffLock_stat 3;
BA_ "GenSigMaxLatency" SG_ 689 CentralRearDiffLock_stat 100;
BA_ "GenSigCycleTime" SG_ 689 TransmissionBrakeMode 100;
BA_ "GenSigCycleTimeActive" SG_ 689 TransmissionBrakeMode 100;
BA_ "GenSigStartValue" SG_ 689 TransmissionBrakeMode 3;
BA_ "GenSigMaxLatency" SG_ 689 TransmissionBrakeMode 100;
BA_ "GenSigCycleTime" SG_ 689 PS_HeadLightAdjustment 100;
BA_ "GenSigCycleTimeActive" SG_ 689 PS_HeadLightAdjustment 100;
BA_ "GenSigStartValue" SG_ 689 PS_HeadLightAdjustment 3;
BA_ "GenSigMaxLatency" SG_ 689 PS_HeadLightAdjustment 100;
BA_ "GenSigCycleTime" SG_ 689 ReducedLoadMode_stat 100;
BA_ "GenSigCycleTimeActive" SG_ 689 ReducedLoadMode_stat 100;
BA_ "GenSigStartValue" SG_ 689 ReducedLoadMode_stat 3;
BA_ "GenSigMaxLatency" SG_ 689 ReducedLoadMode_stat 100;
BA_ "GenSigCycleTime" SG_ 689 FrontWheelDifflockRequest 100;
BA_ "GenSigCycleTimeActive" SG_ 689 FrontWheelDifflockRequest 100;
BA_ "GenSigStartValue" SG_ 689 FrontWheelDifflockRequest 3;
BA_ "GenSigMaxLatency" SG_ 689 FrontWheelDifflockRequest 100;
BA_ "GenSigCycleTime" SG_ 689 ABSEBSAmberWarningSignal 100;
BA_ "GenSigCycleTimeActive" SG_ 689 ABSEBSAmberWarningSignal 100;
BA_ "GenSigStartValue" SG_ 689 ABSEBSAmberWarningSignal 3;
BA_ "GenSigMaxLatency" SG_ 689 ABSEBSAmberWarningSignal 100;
BA_ "GenSigCycleTime" SG_ 689 DifferentialLockStateFrAxle1 100;
BA_ "GenSigCycleTimeActive" SG_ 689 DifferentialLockStateFrAxle1 100;
BA_ "GenSigStartValue" SG_ 689 DifferentialLockStateFrAxle1 3;
BA_ "GenSigMaxLatency" SG_ 689 DifferentialLockStateFrAxle1 100;
BA_ "GenSigCycleTime" SG_ 689 Trail1TPMLostCom 100;
BA_ "GenSigCycleTimeActive" SG_ 689 Trail1TPMLostCom 100;
BA_ "GenSigStartValue" SG_ 689 Trail1TPMLostCom 3;
BA_ "GenSigMaxLatency" SG_ 689 Trail1TPMLostCom 100;
BA_ "GenSigCycleTime" SG_ 689 TrailerInflationPossible_stat 100;
BA_ "GenSigCycleTimeActive" SG_ 689 TrailerInflationPossible_stat 100;
BA_ "GenSigStartValue" SG_ 689 TrailerInflationPossible_stat 3;
BA_ "GenSigMaxLatency" SG_ 689 TrailerInflationPossible_stat 100;
BA_ "GenSigCycleTime" SG_ 689 DrivelineRetarderStat 100;
BA_ "GenSigCycleTimeActive" SG_ 689 DrivelineRetarderStat 100;
BA_ "GenSigStartValue" SG_ 689 DrivelineRetarderStat 3;
BA_ "GenSigMaxLatency" SG_ 689 DrivelineRetarderStat 100;
BA_ "GenSigCycleTime" SG_ 689 PS_FogLightRear 100;
BA_ "GenSigCycleTimeActive" SG_ 689 PS_FogLightRear 100;
BA_ "GenSigStartValue" SG_ 689 PS_FogLightRear 3;
BA_ "GenSigMaxLatency" SG_ 689 PS_FogLightRear 100;
BA_ "GenSigCycleTime" SG_ 689 PS_MainBeam 100;
BA_ "GenSigCycleTimeActive" SG_ 689 PS_MainBeam 100;
BA_ "GenSigStartValue" SG_ 689 PS_MainBeam 3;
BA_ "GenSigMaxLatency" SG_ 689 PS_MainBeam 100;
BA_ "GenSigCycleTime" SG_ 689 DeCompActive 100;
BA_ "GenSigCycleTimeActive" SG_ 689 DeCompActive 100;
BA_ "GenSigStartValue" SG_ 689 DeCompActive 3;
BA_ "GenSigMaxLatency" SG_ 689 DeCompActive 100;
BA_ "GenSigCycleTime" SG_ 689 ECSManStandbyStatus 100;
BA_ "GenSigCycleTimeActive" SG_ 689 ECSManStandbyStatus 100;
BA_ "GenSigStartValue" SG_ 689 ECSManStandbyStatus 3;
BA_ "GenSigMaxLatency" SG_ 689 ECSManStandbyStatus 100;
BA_ "GenSigCycleTime" SG_ 689 AutoPBRelease_stat 100;
BA_ "GenSigCycleTimeActive" SG_ 689 AutoPBRelease_stat 100;
BA_ "GenSigStartValue" SG_ 689 AutoPBRelease_stat 3;
BA_ "GenSigMaxLatency" SG_ 689 AutoPBRelease_stat 100;
BA_ "GenSigCycleTime" SG_ 689 Trail4TPMLostCom 100;
BA_ "GenSigCycleTimeActive" SG_ 689 Trail4TPMLostCom 100;
BA_ "GenSigStartValue" SG_ 689 Trail4TPMLostCom 3;
BA_ "GenSigMaxLatency" SG_ 689 Trail4TPMLostCom 100;
BA_ "GenSigCycleTime" SG_ 689 EBSRedWarningSignal 100;
BA_ "GenSigCycleTimeActive" SG_ 689 EBSRedWarningSignal 100;
BA_ "GenSigStartValue" SG_ 689 EBSRedWarningSignal 3;
BA_ "GenSigMaxLatency" SG_ 689 EBSRedWarningSignal 100;
BA_ "GenSigCycleTime" SG_ 689 DifferentialLockStateCentral 100;
BA_ "GenSigCycleTimeActive" SG_ 689 DifferentialLockStateCentral 100;
BA_ "GenSigStartValue" SG_ 689 DifferentialLockStateCentral 3;
BA_ "GenSigMaxLatency" SG_ 689 DifferentialLockStateCentral 100;
BA_ "GenSigCycleTime" SG_ 689 RearAxle3DiffLock_stat 100;
BA_ "GenSigCycleTimeActive" SG_ 689 RearAxle3DiffLock_stat 100;
BA_ "GenSigStartValue" SG_ 689 RearAxle3DiffLock_stat 3;
BA_ "GenSigMaxLatency" SG_ 689 RearAxle3DiffLock_stat 100;
BA_ "GenSigCycleTime" SG_ 689 AntiLockBrakingActive 100;
BA_ "GenSigCycleTimeActive" SG_ 689 AntiLockBrakingActive 100;
BA_ "GenSigStartValue" SG_ 689 AntiLockBrakingActive 3;
BA_ "GenSigMaxLatency" SG_ 689 AntiLockBrakingActive 100;
BA_ "GenSigCycleTime" SG_ 689 RearAxle1DiffLock_stat 100;
BA_ "GenSigCycleTimeActive" SG_ 689 RearAxle1DiffLock_stat 100;
BA_ "GenSigStartValue" SG_ 689 RearAxle1DiffLock_stat 3;
BA_ "GenSigMaxLatency" SG_ 689 RearAxle1DiffLock_stat 100;
BA_ "GenSigCycleTime" SG_ 689 Trail5TPMLostCom 100;
BA_ "GenSigCycleTimeActive" SG_ 689 Trail5TPMLostCom 100;
BA_ "GenSigStartValue" SG_ 689 Trail5TPMLostCom 3;
BA_ "GenSigMaxLatency" SG_ 689 Trail5TPMLostCom 100;
BA_ "GenSigCycleTime" SG_ 689 PS_PositionLight 100;
BA_ "GenSigCycleTimeActive" SG_ 689 PS_PositionLight 100;
BA_ "GenSigStartValue" SG_ 689 PS_PositionLight 3;
BA_ "GenSigMaxLatency" SG_ 689 PS_PositionLight 100;
BA_ "GenSigCycleTime" SG_ 689 BatteryCapacity_Ack 100;
BA_ "GenSigCycleTimeActive" SG_ 689 BatteryCapacity_Ack 100;
BA_ "GenSigStartValue" SG_ 689 BatteryCapacity_Ack 3;
BA_ "GenSigMaxLatency" SG_ 689 BatteryCapacity_Ack 100;
BA_ "GenSigCycleTime" SG_ 689 Trail3TPMLostCom 100;
BA_ "GenSigCycleTimeActive" SG_ 689 Trail3TPMLostCom 100;
BA_ "GenSigStartValue" SG_ 689 Trail3TPMLostCom 3;
BA_ "GenSigMaxLatency" SG_ 689 Trail3TPMLostCom 100;
BA_ "GenSigCycleTime" SG_ 689 ParkBrakeWorkshopMode 100;
BA_ "GenSigCycleTimeActive" SG_ 689 ParkBrakeWorkshopMode 100;
BA_ "GenSigStartValue" SG_ 689 ParkBrakeWorkshopMode 3;
BA_ "GenSigMaxLatency" SG_ 689 ParkBrakeWorkshopMode 100;
BA_ "GenSigCycleTime" SG_ 689 LowTempClutchInfo 100;
BA_ "GenSigCycleTimeActive" SG_ 689 LowTempClutchInfo 100;
BA_ "GenSigStartValue" SG_ 689 LowTempClutchInfo 3;
BA_ "GenSigMaxLatency" SG_ 689 LowTempClutchInfo 100;
BA_ "GenSigCycleTime" SG_ 688 APMSafetyWarning_CRC 100;
BA_ "GenSigCycleTimeActive" SG_ 688 APMSafetyWarning_CRC 100;
BA_ "GenSigStartValue" SG_ 688 APMSafetyWarning_CRC 255;
BA_ "GenSigMaxLatency" SG_ 688 APMSafetyWarning_CRC 100;
BA_ "E2EDataId" SG_ 688 APMSafetyWarning_CRC 181;
BA_ "E2EDataLength" SG_ 688 APMSafetyWarning_CRC 16;
BA_ "E2EProfile" SG_ 688 APMSafetyWarning_CRC "P01";
BA_ "GenSigCycleTime" SG_ 688 PBStatus_CRC 100;
BA_ "GenSigCycleTimeActive" SG_ 688 PBStatus_CRC 100;
BA_ "GenSigStartValue" SG_ 688 PBStatus_CRC 255;
BA_ "GenSigMaxLatency" SG_ 688 PBStatus_CRC 100;
BA_ "E2EDataId" SG_ 688 PBStatus_CRC 107;
BA_ "E2EDataLength" SG_ 688 PBStatus_CRC 24;
BA_ "E2EProfile" SG_ 688 PBStatus_CRC "P01";
BA_ "GenSigCycleTime" SG_ 688 TrailerWithoutABS 100;
BA_ "GenSigCycleTimeActive" SG_ 688 TrailerWithoutABS 100;
BA_ "GenSigStartValue" SG_ 688 TrailerWithoutABS 3;
BA_ "GenSigMaxLatency" SG_ 688 TrailerWithoutABS 100;
BA_ "GenSigCycleTime" SG_ 688 APMSafetyWarning_RedRqst 100;
BA_ "GenSigCycleTimeActive" SG_ 688 APMSafetyWarning_RedRqst 100;
BA_ "GenSigStartValue" SG_ 688 APMSafetyWarning_RedRqst 3;
BA_ "GenSigMaxLatency" SG_ 688 APMSafetyWarning_RedRqst 100;
BA_ "GenSigCycleTime" SG_ 688 EcoRollEnabledStatus 100;
BA_ "GenSigCycleTimeActive" SG_ 688 EcoRollEnabledStatus 100;
BA_ "GenSigStartValue" SG_ 688 EcoRollEnabledStatus 3;
BA_ "GenSigMaxLatency" SG_ 688 EcoRollEnabledStatus 100;
BA_ "GenSigCycleTime" SG_ 688 PBStatus_Actuation 100;
BA_ "GenSigCycleTimeActive" SG_ 688 PBStatus_Actuation 100;
BA_ "GenSigStartValue" SG_ 688 PBStatus_Actuation 7;
BA_ "GenSigMaxLatency" SG_ 688 PBStatus_Actuation 100;
BA_ "GenSigCycleTime" SG_ 688 GearShiftingRec_Steps 100;
BA_ "GenSigCycleTimeActive" SG_ 688 GearShiftingRec_Steps 100;
BA_ "GenSigStartValue" SG_ 688 GearShiftingRec_Steps 7;
BA_ "GenSigMaxLatency" SG_ 688 GearShiftingRec_Steps 100;
BA_ "GenSigCycleTime" SG_ 688 PBStatus_IntegrityLvl 100;
BA_ "GenSigCycleTimeActive" SG_ 688 PBStatus_IntegrityLvl 100;
BA_ "GenSigStartValue" SG_ 688 PBStatus_IntegrityLvl 3;
BA_ "GenSigMaxLatency" SG_ 688 PBStatus_IntegrityLvl 100;
BA_ "GenSigCycleTime" SG_ 688 GearShiftingRec_Direction 100;
BA_ "GenSigCycleTimeActive" SG_ 688 GearShiftingRec_Direction 100;
BA_ "GenSigStartValue" SG_ 688 GearShiftingRec_Direction 7;
BA_ "GenSigMaxLatency" SG_ 688 GearShiftingRec_Direction 100;
BA_ "GenSigCycleTime" SG_ 688 APM_TrailerCircPressureStatus 100;
BA_ "GenSigCycleTimeActive" SG_ 688 APM_TrailerCircPressureStatus 100;
BA_ "GenSigStartValue" SG_ 688 APM_TrailerCircPressureStatus 3;
BA_ "GenSigMaxLatency" SG_ 688 APM_TrailerCircPressureStatus 100;
BA_ "GenSigCycleTime" SG_ 688 RearPropulsionStat_Rear2Axle 100;
BA_ "GenSigCycleTimeActive" SG_ 688 RearPropulsionStat_Rear2Axle 100;
BA_ "GenSigStartValue" SG_ 688 RearPropulsionStat_Rear2Axle 15;
BA_ "GenSigMaxLatency" SG_ 688 RearPropulsionStat_Rear2Axle 100;
BA_ "GenSigCycleTime" SG_ 688 RearPropulsionStat_Rear1Axle 100;
BA_ "GenSigCycleTimeActive" SG_ 688 RearPropulsionStat_Rear1Axle 100;
BA_ "GenSigStartValue" SG_ 688 RearPropulsionStat_Rear1Axle 15;
BA_ "GenSigMaxLatency" SG_ 688 RearPropulsionStat_Rear1Axle 100;
BA_ "GenSigCycleTime" SG_ 688 RearPropulsionStat_Rear3Axle 100;
BA_ "GenSigCycleTimeActive" SG_ 688 RearPropulsionStat_Rear3Axle 100;
BA_ "GenSigStartValue" SG_ 688 RearPropulsionStat_Rear3Axle 15;
BA_ "GenSigMaxLatency" SG_ 688 RearPropulsionStat_Rear3Axle 100;
BA_ "GenSigCycleTime" SG_ 688 PBStatus_SqC 100;
BA_ "GenSigCycleTimeActive" SG_ 688 PBStatus_SqC 100;
BA_ "GenSigStartValue" SG_ 688 PBStatus_SqC 14;
BA_ "GenSigMaxLatency" SG_ 688 PBStatus_SqC 100;
BA_ "GenSigCycleTime" SG_ 688 APMSafetyWarning_SqC 100;
BA_ "GenSigCycleTimeActive" SG_ 688 APMSafetyWarning_SqC 100;
BA_ "GenSigStartValue" SG_ 688 APMSafetyWarning_SqC 14;
BA_ "GenSigMaxLatency" SG_ 688 APMSafetyWarning_SqC 100;
BA_ "GenSigCycleTime" SG_ 688 APMSafetyWarning_YellowRqst 100;
BA_ "GenSigCycleTimeActive" SG_ 688 APMSafetyWarning_YellowRqst 100;
BA_ "GenSigStartValue" SG_ 688 APMSafetyWarning_YellowRqst 3;
BA_ "GenSigMaxLatency" SG_ 688 APMSafetyWarning_YellowRqst 100;
BA_ "GenSigCycleTime" SG_ 394 LongitudinalAcceleration 100;
BA_ "GenSigCycleTimeActive" SG_ 394 LongitudinalAcceleration 100;
BA_ "GenSigStartValue" SG_ 394 LongitudinalAcceleration 65535;
BA_ "GenSigMaxLatency" SG_ 394 LongitudinalAcceleration 50;
BA_ "GenSigCycleTime" SG_ 394 CCSetSpeed 100;
BA_ "GenSigCycleTimeActive" SG_ 394 CCSetSpeed 100;
BA_ "GenSigStartValue" SG_ 394 CCSetSpeed 65535;
BA_ "GenSigMaxLatency" SG_ 394 CCSetSpeed 50;
BA_ "GenSigCycleTime" SG_ 393 EngineActiveStatus 100;
BA_ "GenSigCycleTimeActive" SG_ 393 EngineActiveStatus 100;
BA_ "GenSigStartValue" SG_ 393 EngineActiveStatus 15;
BA_ "GenSigMaxLatency" SG_ 393 EngineActiveStatus 50;
BA_ "GenSigCycleTime" SG_ 393 BackLightDimming_Status3 100;
BA_ "GenSigCycleTimeActive" SG_ 393 BackLightDimming_Status3 100;
BA_ "GenSigStartValue" SG_ 393 BackLightDimming_Status3 31;
BA_ "GenSigMaxLatency" SG_ 393 BackLightDimming_Status3 50;
BA_ "GenSigCycleTime" SG_ 393 FrontAxleSpeed 100;
BA_ "GenSigCycleTimeActive" SG_ 393 FrontAxleSpeed 100;
BA_ "GenSigStartValue" SG_ 393 FrontAxleSpeed 65535;
BA_ "GenSigMaxLatency" SG_ 393 FrontAxleSpeed 50;
BA_ "GenSigCycleTime" SG_ 393 EPBBackupMode 100;
BA_ "GenSigCycleTimeActive" SG_ 393 EPBBackupMode 100;
BA_ "GenSigStartValue" SG_ 393 EPBBackupMode 15;
BA_ "GenSigMaxLatency" SG_ 393 EPBBackupMode 50;
BA_ "GenSigCycleTime" SG_ 393 BrakePedalTestState 100;
BA_ "GenSigCycleTimeActive" SG_ 393 BrakePedalTestState 100;
BA_ "GenSigStartValue" SG_ 393 BrakePedalTestState 15;
BA_ "GenSigMaxLatency" SG_ 393 BrakePedalTestState 50;
BA_ "GenSigCycleTime" SG_ 393 DriverPresenceStatus 100;
BA_ "GenSigCycleTimeActive" SG_ 393 DriverPresenceStatus 100;
BA_ "GenSigStartValue" SG_ 393 DriverPresenceStatus 15;
BA_ "GenSigMaxLatency" SG_ 393 DriverPresenceStatus 50;
BA_ "GenSigCycleTime" SG_ 393 ParkBrakeApplicationMode2 100;
BA_ "GenSigCycleTimeActive" SG_ 393 ParkBrakeApplicationMode2 100;
BA_ "GenSigStartValue" SG_ 393 ParkBrakeApplicationMode2 15;
BA_ "GenSigMaxLatency" SG_ 393 ParkBrakeApplicationMode2 50;
BA_ "GenSigCycleTime" SG_ 393 RampLevelStatus 100;
BA_ "GenSigCycleTimeActive" SG_ 393 RampLevelStatus 100;
BA_ "GenSigStartValue" SG_ 393 RampLevelStatus 15;
BA_ "GenSigMaxLatency" SG_ 393 RampLevelStatus 50;
BA_ "GenSigCycleTime" SG_ 393 ParkBrakeReleaseMode2 100;
BA_ "GenSigCycleTimeActive" SG_ 393 ParkBrakeReleaseMode2 100;
BA_ "GenSigStartValue" SG_ 393 ParkBrakeReleaseMode2 15;
BA_ "GenSigMaxLatency" SG_ 393 ParkBrakeReleaseMode2 50;
BA_ "GenSigCycleTime" SG_ 393 BackLightDimming_Status 100;
BA_ "GenSigCycleTimeActive" SG_ 393 BackLightDimming_Status 100;
BA_ "GenSigStartValue" SG_ 393 BackLightDimming_Status 31;
BA_ "GenSigMaxLatency" SG_ 393 BackLightDimming_Status 50;
BA_ "GenSigCycleTime" SG_ 393 HeightControlMode 100;
BA_ "GenSigCycleTimeActive" SG_ 393 HeightControlMode 100;
BA_ "GenSigStartValue" SG_ 393 HeightControlMode 15;
BA_ "GenSigMaxLatency" SG_ 393 HeightControlMode 50;
BA_ "GenSigCycleTime" SG_ 393 FifthWheelLockingInformation 100;
BA_ "GenSigCycleTimeActive" SG_ 393 FifthWheelLockingInformation 100;
BA_ "GenSigStartValue" SG_ 393 FifthWheelLockingInformation 15;
BA_ "GenSigMaxLatency" SG_ 393 FifthWheelLockingInformation 50;
BA_ "GenSigCycleTime" SG_ 392 FirstAxleLowerPrioSelected 100;
BA_ "GenSigCycleTimeActive" SG_ 392 FirstAxleLowerPrioSelected 100;
BA_ "GenSigStartValue" SG_ 392 FirstAxleLowerPrioSelected 7;
BA_ "GenSigMaxLatency" SG_ 392 FirstAxleLowerPrioSelected 50;
BA_ "GenSigCycleTime" SG_ 392 ESCState 100;
BA_ "GenSigCycleTimeActive" SG_ 392 ESCState 100;
BA_ "GenSigStartValue" SG_ 392 ESCState 7;
BA_ "GenSigMaxLatency" SG_ 392 ESCState 50;
BA_ "GenSigCycleTime" SG_ 392 KneelingInformation 100;
BA_ "GenSigCycleTimeActive" SG_ 392 KneelingInformation 100;
BA_ "GenSigStartValue" SG_ 392 KneelingInformation 15;
BA_ "GenSigMaxLatency" SG_ 392 KneelingInformation 50;
BA_ "GenSigCycleTime" SG_ 392 TrailerTest_stat 100;
BA_ "GenSigCycleTimeActive" SG_ 392 TrailerTest_stat 100;
BA_ "GenSigStartValue" SG_ 392 TrailerTest_stat 7;
BA_ "GenSigMaxLatency" SG_ 392 TrailerTest_stat 50;
BA_ "GenSigCycleTime" SG_ 392 ThreePosDifflockSwitch_stat 100;
BA_ "GenSigCycleTimeActive" SG_ 392 ThreePosDifflockSwitch_stat 100;
BA_ "GenSigStartValue" SG_ 392 ThreePosDifflockSwitch_stat 7;
BA_ "GenSigMaxLatency" SG_ 392 ThreePosDifflockSwitch_stat 50;
BA_ "GenSigCycleTime" SG_ 392 HillHolderMode 100;
BA_ "GenSigCycleTimeActive" SG_ 392 HillHolderMode 100;
BA_ "GenSigStartValue" SG_ 392 HillHolderMode 7;
BA_ "GenSigMaxLatency" SG_ 392 HillHolderMode 50;
BA_ "GenSigCycleTime" SG_ 392 RampHeightOutsideTargetRange 100;
BA_ "GenSigCycleTimeActive" SG_ 392 RampHeightOutsideTargetRange 100;
BA_ "GenSigStartValue" SG_ 392 RampHeightOutsideTargetRange 7;
BA_ "GenSigMaxLatency" SG_ 392 RampHeightOutsideTargetRange 50;
BA_ "GenSigCycleTime" SG_ 392 ShortStopHeater_status 100;
BA_ "GenSigCycleTimeActive" SG_ 392 ShortStopHeater_status 100;
BA_ "GenSigStartValue" SG_ 392 ShortStopHeater_status 7;
BA_ "GenSigMaxLatency" SG_ 392 ShortStopHeater_status 50;
BA_ "GenSigCycleTime" SG_ 392 LuggageAjar_stat 100;
BA_ "GenSigCycleTimeActive" SG_ 392 LuggageAjar_stat 100;
BA_ "GenSigStartValue" SG_ 392 LuggageAjar_stat 7;
BA_ "GenSigMaxLatency" SG_ 392 LuggageAjar_stat 50;
BA_ "GenSigCycleTime" SG_ 392 LoadDistributionRequestedACK 100;
BA_ "GenSigCycleTimeActive" SG_ 392 LoadDistributionRequestedACK 100;
BA_ "GenSigStartValue" SG_ 392 LoadDistributionRequestedACK 7;
BA_ "GenSigMaxLatency" SG_ 392 LoadDistributionRequestedACK 50;
BA_ "GenSigCycleTime" SG_ 392 StretchBrake_Stat 100;
BA_ "GenSigCycleTimeActive" SG_ 392 StretchBrake_Stat 100;
BA_ "GenSigStartValue" SG_ 392 StretchBrake_Stat 7;
BA_ "GenSigMaxLatency" SG_ 392 StretchBrake_Stat 50;
BA_ "GenSigCycleTime" SG_ 392 MirrorHeatingMode 100;
BA_ "GenSigCycleTimeActive" SG_ 392 MirrorHeatingMode 100;
BA_ "GenSigStartValue" SG_ 392 MirrorHeatingMode 7;
BA_ "GenSigMaxLatency" SG_ 392 MirrorHeatingMode 50;
BA_ "GenSigCycleTime" SG_ 392 ESCStatus 100;
BA_ "GenSigCycleTimeActive" SG_ 392 ESCStatus 100;
BA_ "GenSigStartValue" SG_ 392 ESCStatus 7;
BA_ "GenSigMaxLatency" SG_ 392 ESCStatus 50;
BA_ "GenSigCycleTime" SG_ 392 DriverRetarderRequest 100;
BA_ "GenSigCycleTimeActive" SG_ 392 DriverRetarderRequest 100;
BA_ "GenSigStartValue" SG_ 392 DriverRetarderRequest 7;
BA_ "GenSigMaxLatency" SG_ 392 DriverRetarderRequest 50;
BA_ "GenSigCycleTime" SG_ 392 PBReleaseAcceptance_stat 100;
BA_ "GenSigCycleTimeActive" SG_ 392 PBReleaseAcceptance_stat 100;
BA_ "GenSigStartValue" SG_ 392 PBReleaseAcceptance_stat 7;
BA_ "GenSigMaxLatency" SG_ 392 PBReleaseAcceptance_stat 50;
BA_ "GenSigCycleTime" SG_ 392 PSWindowPosition 100;
BA_ "GenSigCycleTimeActive" SG_ 392 PSWindowPosition 100;
BA_ "GenSigStartValue" SG_ 392 PSWindowPosition 7;
BA_ "GenSigMaxLatency" SG_ 392 PSWindowPosition 50;
BA_ "GenSigCycleTime" SG_ 392 RemoteParkingClimateRqst 100;
BA_ "GenSigCycleTimeActive" SG_ 392 RemoteParkingClimateRqst 100;
BA_ "GenSigStartValue" SG_ 392 RemoteParkingClimateRqst 7;
BA_ "GenSigMaxLatency" SG_ 392 RemoteParkingClimateRqst 50;
BA_ "GenSigCycleTime" SG_ 392 AutoDefogmode_Status 100;
BA_ "GenSigCycleTimeActive" SG_ 392 AutoDefogmode_Status 100;
BA_ "GenSigStartValue" SG_ 392 AutoDefogmode_Status 7;
BA_ "GenSigMaxLatency" SG_ 392 AutoDefogmode_Status 50;
BA_ "GenSigCycleTime" SG_ 392 RideHeightOutsideTargetRange 100;
BA_ "GenSigCycleTimeActive" SG_ 392 RideHeightOutsideTargetRange 100;
BA_ "GenSigStartValue" SG_ 392 RideHeightOutsideTargetRange 7;
BA_ "GenSigMaxLatency" SG_ 392 RideHeightOutsideTargetRange 50;
BA_ "GenSigCycleTime" SG_ 392 DriveLevelPosUserInteraction 100;
BA_ "GenSigCycleTimeActive" SG_ 392 DriveLevelPosUserInteraction 100;
BA_ "GenSigStartValue" SG_ 392 DriveLevelPosUserInteraction 7;
BA_ "GenSigMaxLatency" SG_ 392 DriveLevelPosUserInteraction 50;
BA_ "GenSigCycleTime" SG_ 392 HillStartAidStatus 100;
BA_ "GenSigCycleTimeActive" SG_ 392 HillStartAidStatus 100;
BA_ "GenSigStartValue" SG_ 392 HillStartAidStatus 7;
BA_ "GenSigMaxLatency" SG_ 392 HillStartAidStatus 50;
BA_ "GenSigCycleTime" SG_ 391 AcceleratorPedalTestStatus 100;
BA_ "GenSigCycleTimeActive" SG_ 391 AcceleratorPedalTestStatus 100;
BA_ "GenSigStartValue" SG_ 391 AcceleratorPedalTestStatus 7;
BA_ "GenSigMaxLatency" SG_ 391 AcceleratorPedalTestStatus 50;
BA_ "GenSigCycleTime" SG_ 391 AutoDefogmode_Selection 100;
BA_ "GenSigCycleTimeActive" SG_ 391 AutoDefogmode_Selection 100;
BA_ "GenSigStartValue" SG_ 391 AutoDefogmode_Selection 7;
BA_ "GenSigMaxLatency" SG_ 391 AutoDefogmode_Selection 50;
BA_ "GenSigCycleTime" SG_ 391 ESCDriverReq 100;
BA_ "GenSigCycleTimeActive" SG_ 391 ESCDriverReq 100;
BA_ "GenSigStartValue" SG_ 391 ESCDriverReq 7;
BA_ "GenSigMaxLatency" SG_ 391 ESCDriverReq 50;
BA_ "GenSigCycleTime" SG_ 391 UnevenLoadWarning 100;
BA_ "GenSigCycleTimeActive" SG_ 391 UnevenLoadWarning 100;
BA_ "GenSigStartValue" SG_ 391 UnevenLoadWarning 3;
BA_ "GenSigMaxLatency" SG_ 391 UnevenLoadWarning 50;
BA_ "GenSigCycleTime" SG_ 391 RrInterAxlDiffLockActvnFuncReq 100;
BA_ "GenSigCycleTimeActive" SG_ 391 RrInterAxlDiffLockActvnFuncReq 100;
BA_ "GenSigStartValue" SG_ 391 RrInterAxlDiffLockActvnFuncReq 3;
BA_ "GenSigMaxLatency" SG_ 391 RrInterAxlDiffLockActvnFuncReq 50;
BA_ "GenSigCycleTime" SG_ 391 DoorsAjar_stat 100;
BA_ "GenSigCycleTimeActive" SG_ 391 DoorsAjar_stat 100;
BA_ "GenSigStartValue" SG_ 391 DoorsAjar_stat 7;
BA_ "GenSigMaxLatency" SG_ 391 DoorsAjar_stat 50;
BA_ "GenSigCycleTime" SG_ 391 ABSManAutoInhibitionStat 100;
BA_ "GenSigCycleTimeActive" SG_ 391 ABSManAutoInhibitionStat 100;
BA_ "GenSigStartValue" SG_ 391 ABSManAutoInhibitionStat 7;
BA_ "GenSigMaxLatency" SG_ 391 ABSManAutoInhibitionStat 50;
BA_ "GenSigCycleTime" SG_ 391 RrInterAxlDiffLockActvnDrvrReq 100;
BA_ "GenSigCycleTimeActive" SG_ 391 RrInterAxlDiffLockActvnDrvrReq 100;
BA_ "GenSigStartValue" SG_ 391 RrInterAxlDiffLockActvnDrvrReq 3;
BA_ "GenSigMaxLatency" SG_ 391 RrInterAxlDiffLockActvnDrvrReq 50;
BA_ "GenSigCycleTime" SG_ 391 ACMode_Selection 100;
BA_ "GenSigCycleTimeActive" SG_ 391 ACMode_Selection 100;
BA_ "GenSigStartValue" SG_ 391 ACMode_Selection 7;
BA_ "GenSigMaxLatency" SG_ 391 ACMode_Selection 50;
BA_ "GenSigCycleTime" SG_ 391 EngineOilTempHigh 100;
BA_ "GenSigCycleTimeActive" SG_ 391 EngineOilTempHigh 100;
BA_ "GenSigStartValue" SG_ 391 EngineOilTempHigh 7;
BA_ "GenSigMaxLatency" SG_ 391 EngineOilTempHigh 50;
BA_ "GenSigCycleTime" SG_ 391 StartupProhibitStatus 100;
BA_ "GenSigCycleTimeActive" SG_ 391 StartupProhibitStatus 100;
BA_ "GenSigStartValue" SG_ 391 StartupProhibitStatus 3;
BA_ "GenSigMaxLatency" SG_ 391 StartupProhibitStatus 50;
BA_ "GenSigCycleTime" SG_ 391 AuxBrakesDwngrdModeInd_rqst 100;
BA_ "GenSigCycleTimeActive" SG_ 391 AuxBrakesDwngrdModeInd_rqst 100;
BA_ "GenSigStartValue" SG_ 391 AuxBrakesDwngrdModeInd_rqst 7;
BA_ "GenSigMaxLatency" SG_ 391 AuxBrakesDwngrdModeInd_rqst 50;
BA_ "GenSigCycleTime" SG_ 391 ElectricalLoadReduction_rqst 100;
BA_ "GenSigCycleTimeActive" SG_ 391 ElectricalLoadReduction_rqst 100;
BA_ "GenSigStartValue" SG_ 391 ElectricalLoadReduction_rqst 7;
BA_ "GenSigMaxLatency" SG_ 391 ElectricalLoadReduction_rqst 50;
BA_ "GenSigCycleTime" SG_ 391 ACmode_Status 100;
BA_ "GenSigCycleTimeActive" SG_ 391 ACmode_Status 100;
BA_ "GenSigStartValue" SG_ 391 ACmode_Status 7;
BA_ "GenSigMaxLatency" SG_ 391 ACmode_Status 50;
BA_ "GenSigCycleTime" SG_ 391 LoadDistributionChangeACK 100;
BA_ "GenSigCycleTimeActive" SG_ 391 LoadDistributionChangeACK 100;
BA_ "GenSigStartValue" SG_ 391 LoadDistributionChangeACK 7;
BA_ "GenSigMaxLatency" SG_ 391 LoadDistributionChangeACK 50;
BA_ "GenSigCycleTime" SG_ 391 FerryFunctionStatus 100;
BA_ "GenSigCycleTimeActive" SG_ 391 FerryFunctionStatus 100;
BA_ "GenSigStartValue" SG_ 391 FerryFunctionStatus 7;
BA_ "GenSigMaxLatency" SG_ 391 FerryFunctionStatus 50;
BA_ "GenSigCycleTime" SG_ 391 ClutchOverloadStatus 100;
BA_ "GenSigCycleTimeActive" SG_ 391 ClutchOverloadStatus 100;
BA_ "GenSigStartValue" SG_ 391 ClutchOverloadStatus 3;
BA_ "GenSigMaxLatency" SG_ 391 ClutchOverloadStatus 50;
BA_ "GenSigCycleTime" SG_ 391 AutoBlowerLevel_Selection 100;
BA_ "GenSigCycleTimeActive" SG_ 391 AutoBlowerLevel_Selection 100;
BA_ "GenSigStartValue" SG_ 391 AutoBlowerLevel_Selection 7;
BA_ "GenSigMaxLatency" SG_ 391 AutoBlowerLevel_Selection 50;
BA_ "GenSigCycleTime" SG_ 391 RollerBenchModeStatus 100;
BA_ "GenSigCycleTimeActive" SG_ 391 RollerBenchModeStatus 100;
BA_ "GenSigStartValue" SG_ 391 RollerBenchModeStatus 3;
BA_ "GenSigMaxLatency" SG_ 391 RollerBenchModeStatus 50;
BA_ "GenSigCycleTime" SG_ 391 LoadDistributionALDChangeACK 100;
BA_ "GenSigCycleTimeActive" SG_ 391 LoadDistributionALDChangeACK 100;
BA_ "GenSigStartValue" SG_ 391 LoadDistributionALDChangeACK 7;
BA_ "GenSigMaxLatency" SG_ 391 LoadDistributionALDChangeACK 50;
BA_ "GenSigCycleTime" SG_ 391 EngineSpeedControlStatus 100;
BA_ "GenSigCycleTimeActive" SG_ 391 EngineSpeedControlStatus 100;
BA_ "GenSigStartValue" SG_ 391 EngineSpeedControlStatus 7;
BA_ "GenSigMaxLatency" SG_ 391 EngineSpeedControlStatus 50;
BA_ "GenSigCycleTime" SG_ 391 AutoBlowerLevel_Status 100;
BA_ "GenSigCycleTimeActive" SG_ 391 AutoBlowerLevel_Status 100;
BA_ "GenSigStartValue" SG_ 391 AutoBlowerLevel_Status 7;
BA_ "GenSigMaxLatency" SG_ 391 AutoBlowerLevel_Status 50;
BA_ "GenSigCycleTime" SG_ 391 DTCActive 100;
BA_ "GenSigCycleTimeActive" SG_ 391 DTCActive 100;
BA_ "GenSigStartValue" SG_ 391 DTCActive 3;
BA_ "GenSigMaxLatency" SG_ 391 DTCActive 50;
BA_ "GenSigCycleTime" SG_ 390 PS_SevereEngAndBrkOverspdWarn 100;
BA_ "GenSigCycleTimeActive" SG_ 390 PS_SevereEngAndBrkOverspdWarn 100;
BA_ "GenSigStartValue" SG_ 390 PS_SevereEngAndBrkOverspdWarn 3;
BA_ "GenSigMaxLatency" SG_ 390 PS_SevereEngAndBrkOverspdWarn 50;
BA_ "GenSigCycleTime" SG_ 390 RearFog_Indication 100;
BA_ "GenSigCycleTimeActive" SG_ 390 RearFog_Indication 100;
BA_ "GenSigStartValue" SG_ 390 RearFog_Indication 3;
BA_ "GenSigMaxLatency" SG_ 390 RearFog_Indication 50;
BA_ "GenSigCycleTime" SG_ 390 SasAdaptationInProgress 100;
BA_ "GenSigCycleTimeActive" SG_ 390 SasAdaptationInProgress 100;
BA_ "GenSigStartValue" SG_ 390 SasAdaptationInProgress 3;
BA_ "GenSigMaxLatency" SG_ 390 SasAdaptationInProgress 50;
BA_ "GenSigCycleTime" SG_ 390 SplitBoxDifflockActvnDrvrRqst 100;
BA_ "GenSigCycleTimeActive" SG_ 390 SplitBoxDifflockActvnDrvrRqst 100;
BA_ "GenSigStartValue" SG_ 390 SplitBoxDifflockActvnDrvrRqst 3;
BA_ "GenSigMaxLatency" SG_ 390 SplitBoxDifflockActvnDrvrRqst 50;
BA_ "GenSigCycleTime" SG_ 390 EcoRollActiveStatus 100;
BA_ "GenSigCycleTimeActive" SG_ 390 EcoRollActiveStatus 100;
BA_ "GenSigStartValue" SG_ 390 EcoRollActiveStatus 3;
BA_ "GenSigMaxLatency" SG_ 390 EcoRollActiveStatus 50;
BA_ "GenSigCycleTime" SG_ 390 PloughLampModeStatus 100;
BA_ "GenSigCycleTimeActive" SG_ 390 PloughLampModeStatus 100;
BA_ "GenSigStartValue" SG_ 390 PloughLampModeStatus 3;
BA_ "GenSigMaxLatency" SG_ 390 PloughLampModeStatus 50;
BA_ "GenSigCycleTime" SG_ 390 RrRrItrWhlDiffLckActvnDrvrReq 100;
BA_ "GenSigCycleTimeActive" SG_ 390 RrRrItrWhlDiffLckActvnDrvrReq 100;
BA_ "GenSigStartValue" SG_ 390 RrRrItrWhlDiffLckActvnDrvrReq 3;
BA_ "GenSigMaxLatency" SG_ 390 RrRrItrWhlDiffLckActvnDrvrReq 50;
BA_ "GenSigCycleTime" SG_ 390 AQSMode_Selection 100;
BA_ "GenSigCycleTimeActive" SG_ 390 AQSMode_Selection 100;
BA_ "GenSigStartValue" SG_ 390 AQSMode_Selection 3;
BA_ "GenSigMaxLatency" SG_ 390 AQSMode_Selection 50;
BA_ "GenSigCycleTime" SG_ 390 DrvrRetarderBrakeProgram_rqst 100;
BA_ "GenSigCycleTimeActive" SG_ 390 DrvrRetarderBrakeProgram_rqst 100;
BA_ "GenSigStartValue" SG_ 390 DrvrRetarderBrakeProgram_rqst 3;
BA_ "GenSigMaxLatency" SG_ 390 DrvrRetarderBrakeProgram_rqst 50;
BA_ "GenSigCycleTime" SG_ 390 PS_EngOverSpeedSevereWarning 100;
BA_ "GenSigCycleTimeActive" SG_ 390 PS_EngOverSpeedSevereWarning 100;
BA_ "GenSigStartValue" SG_ 390 PS_EngOverSpeedSevereWarning 3;
BA_ "GenSigMaxLatency" SG_ 390 PS_EngOverSpeedSevereWarning 50;
BA_ "GenSigCycleTime" SG_ 390 ParkBrakeReleasePossible_stat 100;
BA_ "GenSigCycleTimeActive" SG_ 390 ParkBrakeReleasePossible_stat 100;
BA_ "GenSigStartValue" SG_ 390 ParkBrakeReleasePossible_stat 3;
BA_ "GenSigMaxLatency" SG_ 390 ParkBrakeReleasePossible_stat 50;
BA_ "GenSigCycleTime" SG_ 390 StoreIdleValue 100;
BA_ "GenSigCycleTimeActive" SG_ 390 StoreIdleValue 100;
BA_ "GenSigStartValue" SG_ 390 StoreIdleValue 3;
BA_ "GenSigMaxLatency" SG_ 390 StoreIdleValue 50;
BA_ "GenSigCycleTime" SG_ 390 AutRrAxleDiffLockActvnDrvrReq 100;
BA_ "GenSigCycleTimeActive" SG_ 390 AutRrAxleDiffLockActvnDrvrReq 100;
BA_ "GenSigStartValue" SG_ 390 AutRrAxleDiffLockActvnDrvrReq 3;
BA_ "GenSigMaxLatency" SG_ 390 AutRrAxleDiffLockActvnDrvrReq 50;
BA_ "GenSigCycleTime" SG_ 390 TransmLowRangeSenseSwitch 100;
BA_ "GenSigCycleTimeActive" SG_ 390 TransmLowRangeSenseSwitch 100;
BA_ "GenSigStartValue" SG_ 390 TransmLowRangeSenseSwitch 3;
BA_ "GenSigMaxLatency" SG_ 390 TransmLowRangeSenseSwitch 50;
BA_ "GenSigCycleTime" SG_ 390 PBStatusDisplay_cmd 100;
BA_ "GenSigCycleTimeActive" SG_ 390 PBStatusDisplay_cmd 100;
BA_ "GenSigStartValue" SG_ 390 PBStatusDisplay_cmd 3;
BA_ "GenSigMaxLatency" SG_ 390 PBStatusDisplay_cmd 50;
BA_ "GenSigCycleTime" SG_ 390 AutoRearAxleDiffLockFnc_stat 100;
BA_ "GenSigCycleTimeActive" SG_ 390 AutoRearAxleDiffLockFnc_stat 100;
BA_ "GenSigStartValue" SG_ 390 AutoRearAxleDiffLockFnc_stat 3;
BA_ "GenSigMaxLatency" SG_ 390 AutoRearAxleDiffLockFnc_stat 50;
BA_ "GenSigCycleTime" SG_ 390 PoorBrakePerformanceWarning 100;
BA_ "GenSigCycleTimeActive" SG_ 390 PoorBrakePerformanceWarning 100;
BA_ "GenSigStartValue" SG_ 390 PoorBrakePerformanceWarning 3;
BA_ "GenSigMaxLatency" SG_ 390 PoorBrakePerformanceWarning 50;
BA_ "GenSigCycleTime" SG_ 390 AQSmode_Status 100;
BA_ "GenSigCycleTimeActive" SG_ 390 AQSmode_Status 100;
BA_ "GenSigStartValue" SG_ 390 AQSmode_Status 3;
BA_ "GenSigMaxLatency" SG_ 390 AQSmode_Status 50;
BA_ "GenSigCycleTime" SG_ 390 CCIOM_ParkBrakeAlert 100;
BA_ "GenSigCycleTimeActive" SG_ 390 CCIOM_ParkBrakeAlert 100;
BA_ "GenSigStartValue" SG_ 390 CCIOM_ParkBrakeAlert 3;
BA_ "GenSigMaxLatency" SG_ 390 CCIOM_ParkBrakeAlert 50;
BA_ "GenSigCycleTime" SG_ 390 FrontParkBrakeOverrideInd 100;
BA_ "GenSigCycleTimeActive" SG_ 390 FrontParkBrakeOverrideInd 100;
BA_ "GenSigStartValue" SG_ 390 FrontParkBrakeOverrideInd 3;
BA_ "GenSigMaxLatency" SG_ 390 FrontParkBrakeOverrideInd 50;
BA_ "GenSigCycleTime" SG_ 390 ProhibitControlStatus 100;
BA_ "GenSigCycleTimeActive" SG_ 390 ProhibitControlStatus 100;
BA_ "GenSigStartValue" SG_ 390 ProhibitControlStatus 3;
BA_ "GenSigMaxLatency" SG_ 390 ProhibitControlStatus 50;
BA_ "GenSigCycleTime" SG_ 390 PositionLightRequest_status 100;
BA_ "GenSigCycleTimeActive" SG_ 390 PositionLightRequest_status 100;
BA_ "GenSigStartValue" SG_ 390 PositionLightRequest_status 3;
BA_ "GenSigMaxLatency" SG_ 390 PositionLightRequest_status 50;
BA_ "GenSigCycleTime" SG_ 390 DoubleFrontAxleSteeringWarning 100;
BA_ "GenSigCycleTimeActive" SG_ 390 DoubleFrontAxleSteeringWarning 100;
BA_ "GenSigStartValue" SG_ 390 DoubleFrontAxleSteeringWarning 3;
BA_ "GenSigMaxLatency" SG_ 390 DoubleFrontAxleSteeringWarning 50;
BA_ "GenSigCycleTime" SG_ 390 TrailerABSStatus 100;
BA_ "GenSigCycleTimeActive" SG_ 390 TrailerABSStatus 100;
BA_ "GenSigStartValue" SG_ 390 TrailerABSStatus 3;
BA_ "GenSigMaxLatency" SG_ 390 TrailerABSStatus 50;
BA_ "GenSigCycleTime" SG_ 390 LoadCutOffIndication_cmd 100;
BA_ "GenSigCycleTimeActive" SG_ 390 LoadCutOffIndication_cmd 100;
BA_ "GenSigStartValue" SG_ 390 LoadCutOffIndication_cmd 3;
BA_ "GenSigMaxLatency" SG_ 390 LoadCutOffIndication_cmd 50;
BA_ "GenSigCycleTime" SG_ 390 PtosStatus 100;
BA_ "GenSigCycleTimeActive" SG_ 390 PtosStatus 100;
BA_ "GenSigStartValue" SG_ 390 PtosStatus 3;
BA_ "GenSigMaxLatency" SG_ 390 PtosStatus 50;
BA_ "GenSigCycleTime" SG_ 390 REM_PhoneButtonInd_cmd 100;
BA_ "GenSigCycleTimeActive" SG_ 390 REM_PhoneButtonInd_cmd 100;
BA_ "GenSigStartValue" SG_ 390 REM_PhoneButtonInd_cmd 3;
BA_ "GenSigMaxLatency" SG_ 390 REM_PhoneButtonInd_cmd 50;
BA_ "GenSigCycleTime" SG_ 390 TrailerBrake_Stat 100;
BA_ "GenSigCycleTimeActive" SG_ 390 TrailerBrake_Stat 100;
BA_ "GenSigStartValue" SG_ 390 TrailerBrake_Stat 3;
BA_ "GenSigMaxLatency" SG_ 390 TrailerBrake_Stat 50;
BA_ "GenSigCycleTime" SG_ 390 SEM2_PhoneButtonInd_cmd 100;
BA_ "GenSigCycleTimeActive" SG_ 390 SEM2_PhoneButtonInd_cmd 100;
BA_ "GenSigStartValue" SG_ 390 SEM2_PhoneButtonInd_cmd 3;
BA_ "GenSigMaxLatency" SG_ 390 SEM2_PhoneButtonInd_cmd 50;
BA_ "GenSigCycleTime" SG_ 390 GearRangeUnengaged 100;
BA_ "GenSigCycleTimeActive" SG_ 390 GearRangeUnengaged 100;
BA_ "GenSigStartValue" SG_ 390 GearRangeUnengaged 3;
BA_ "GenSigMaxLatency" SG_ 390 GearRangeUnengaged 50;
BA_ "GenSigCycleTime" SG_ 390 ABSOffRoadStatus 100;
BA_ "GenSigCycleTimeActive" SG_ 390 ABSOffRoadStatus 100;
BA_ "GenSigStartValue" SG_ 390 ABSOffRoadStatus 3;
BA_ "GenSigMaxLatency" SG_ 390 ABSOffRoadStatus 50;
BA_ "GenSigCycleTime" SG_ 390 DrvrRetarderBrakeBlending_rqst 100;
BA_ "GenSigCycleTimeActive" SG_ 390 DrvrRetarderBrakeBlending_rqst 100;
BA_ "GenSigStartValue" SG_ 390 DrvrRetarderBrakeBlending_rqst 3;
BA_ "GenSigMaxLatency" SG_ 390 DrvrRetarderBrakeBlending_rqst 50;
BA_ "GenSigCycleTime" SG_ 389 XPRGSystemCap_Priority 100;
BA_ "GenSigCycleTimeActive" SG_ 389 XPRGSystemCap_Priority 100;
BA_ "GenSigStartValue" SG_ 389 XPRGSystemCap_Priority 7;
BA_ "GenSigMaxLatency" SG_ 389 XPRGSystemCap_Priority 50;
BA_ "GenSigCycleTime" SG_ 389 XPRGSystemCap_AllowedRelInhibit 100;
BA_ "GenSigCycleTimeActive" SG_ 389 XPRGSystemCap_AllowedRelInhibit 100;
BA_ "GenSigMaxLatency" SG_ 389 XPRGSystemCap_AllowedRelInhibit 50;
BA_ "GenSigCycleTime" SG_ 389 PHTimerRqstAck_Minutes 100;
BA_ "GenSigCycleTimeActive" SG_ 389 PHTimerRqstAck_Minutes 100;
BA_ "GenSigStartValue" SG_ 389 PHTimerRqstAck_Minutes 255;
BA_ "GenSigMaxLatency" SG_ 389 PHTimerRqstAck_Minutes 50;
BA_ "GenSigCycleTime" SG_ 389 RearAxleDiffLockActvnDrvrReq 100;
BA_ "GenSigCycleTimeActive" SG_ 389 RearAxleDiffLockActvnDrvrReq 100;
BA_ "GenSigStartValue" SG_ 389 RearAxleDiffLockActvnDrvrReq 3;
BA_ "GenSigMaxLatency" SG_ 389 RearAxleDiffLockActvnDrvrReq 50;
BA_ "GenSigCycleTime" SG_ 389 FrRrItrWhlDiffLckActvnDrvrReq 100;
BA_ "GenSigCycleTimeActive" SG_ 389 FrRrItrWhlDiffLckActvnDrvrReq 100;
BA_ "GenSigStartValue" SG_ 389 FrRrItrWhlDiffLckActvnDrvrReq 3;
BA_ "GenSigMaxLatency" SG_ 389 FrRrItrWhlDiffLckActvnDrvrReq 50;
BA_ "GenSigCycleTime" SG_ 389 XPRGSystemCap_AllowedGradCtrlTc 100;
BA_ "GenSigCycleTimeActive" SG_ 389 XPRGSystemCap_AllowedGradCtrlTc 100;
BA_ "GenSigMaxLatency" SG_ 389 XPRGSystemCap_AllowedGradCtrlTc 50;
BA_ "GenSigCycleTime" SG_ 389 XPRGSystemCap_AllowedGradCtrlTl 100;
BA_ "GenSigCycleTimeActive" SG_ 389 XPRGSystemCap_AllowedGradCtrlTl 100;
BA_ "GenSigMaxLatency" SG_ 389 XPRGSystemCap_AllowedGradCtrlTl 50;
BA_ "GenSigCycleTime" SG_ 389 RegenInhibDueHeight 100;
BA_ "GenSigCycleTimeActive" SG_ 389 RegenInhibDueHeight 100;
BA_ "GenSigStartValue" SG_ 389 RegenInhibDueHeight 3;
BA_ "GenSigMaxLatency" SG_ 389 RegenInhibDueHeight 50;
BA_ "GenSigCycleTime" SG_ 389 PHTimerRqstAck_Hours 100;
BA_ "GenSigCycleTimeActive" SG_ 389 PHTimerRqstAck_Hours 100;
BA_ "GenSigStartValue" SG_ 389 PHTimerRqstAck_Hours 255;
BA_ "GenSigMaxLatency" SG_ 389 PHTimerRqstAck_Hours 50;
BA_ "GenSigCycleTime" SG_ 389 PoorAirPressureInfo 100;
BA_ "GenSigCycleTimeActive" SG_ 389 PoorAirPressureInfo 100;
BA_ "GenSigStartValue" SG_ 389 PoorAirPressureInfo 3;
BA_ "GenSigMaxLatency" SG_ 389 PoorAirPressureInfo 50;
BA_ "GenSigCycleTime" SG_ 389 XPRGSystemCap_AllowedPBApp 100;
BA_ "GenSigCycleTimeActive" SG_ 389 XPRGSystemCap_AllowedPBApp 100;
BA_ "GenSigMaxLatency" SG_ 389 XPRGSystemCap_AllowedPBApp 50;
BA_ "GenSigCycleTime" SG_ 389 XRSLControllerMode 100;
BA_ "GenSigCycleTimeActive" SG_ 389 XRSLControllerMode 100;
BA_ "GenSigStartValue" SG_ 389 XRSLControllerMode 3;
BA_ "GenSigMaxLatency" SG_ 389 XRSLControllerMode 50;
BA_ "GenSigCycleTime" SG_ 389 XPRGSystemCap_CRC 100;
BA_ "GenSigCycleTimeActive" SG_ 389 XPRGSystemCap_CRC 100;
BA_ "GenSigStartValue" SG_ 389 XPRGSystemCap_CRC 255;
BA_ "GenSigMaxLatency" SG_ 389 XPRGSystemCap_CRC 50;
BA_ "E2EDataId" SG_ 389 XPRGSystemCap_CRC 144;
BA_ "E2EDataLength" SG_ 389 XPRGSystemCap_CRC 24;
BA_ "E2EProfile" SG_ 389 XPRGSystemCap_CRC "P01";
BA_ "GenSigCycleTime" SG_ 389 XPRGSystemCap_AllowedInflation 100;
BA_ "GenSigCycleTimeActive" SG_ 389 XPRGSystemCap_AllowedInflation 100;
BA_ "GenSigMaxLatency" SG_ 389 XPRGSystemCap_AllowedInflation 50;
BA_ "GenSigCycleTime" SG_ 389 XPRGSystemCap_SqC 100;
BA_ "GenSigCycleTimeActive" SG_ 389 XPRGSystemCap_SqC 100;
BA_ "GenSigStartValue" SG_ 389 XPRGSystemCap_SqC 14;
BA_ "GenSigMaxLatency" SG_ 389 XPRGSystemCap_SqC 50;
BA_ "GenSigCycleTime" SG_ 389 PHTimerRqstAck_DayOfWeekRq 100;
BA_ "GenSigCycleTimeActive" SG_ 389 PHTimerRqstAck_DayOfWeekRq 100;
BA_ "GenSigStartValue" SG_ 389 PHTimerRqstAck_DayOfWeekRq 15;
BA_ "GenSigMaxLatency" SG_ 389 PHTimerRqstAck_DayOfWeekRq 50;
BA_ "GenSigCycleTime" SG_ 389 VIN_rqst 100;
BA_ "GenSigCycleTimeActive" SG_ 389 VIN_rqst 100;
BA_ "GenSigMaxLatency" SG_ 389 VIN_rqst 50;
BA_ "GenSigCycleTime" SG_ 389 PHTimerRqstAck_CurrentOp 100;
BA_ "GenSigCycleTimeActive" SG_ 389 PHTimerRqstAck_CurrentOp 100;
BA_ "GenSigStartValue" SG_ 389 PHTimerRqstAck_CurrentOp 3;
BA_ "GenSigMaxLatency" SG_ 389 PHTimerRqstAck_CurrentOp 50;
BA_ "GenSigCycleTime" SG_ 389 PS_EngineBrakeOverSpeedWarning 100;
BA_ "GenSigCycleTimeActive" SG_ 389 PS_EngineBrakeOverSpeedWarning 100;
BA_ "GenSigStartValue" SG_ 389 PS_EngineBrakeOverSpeedWarning 3;
BA_ "GenSigMaxLatency" SG_ 389 PS_EngineBrakeOverSpeedWarning 50;
BA_ "GenSigCycleTime" SG_ 389 XPRGSystemCap_AllowedDeflation 100;
BA_ "GenSigCycleTimeActive" SG_ 389 XPRGSystemCap_AllowedDeflation 100;
BA_ "GenSigMaxLatency" SG_ 389 XPRGSystemCap_AllowedDeflation 50;
BA_ "GenSigCycleTime" SG_ 389 XPRGSystemCap_AllowedInfInhibit 100;
BA_ "GenSigCycleTimeActive" SG_ 389 XPRGSystemCap_AllowedInfInhibit 100;
BA_ "GenSigMaxLatency" SG_ 389 XPRGSystemCap_AllowedInfInhibit 50;
BA_ "GenSigCycleTime" SG_ 389 TrcnCtrlSlipperyRoadWarning 100;
BA_ "GenSigCycleTimeActive" SG_ 389 TrcnCtrlSlipperyRoadWarning 100;
BA_ "GenSigStartValue" SG_ 389 TrcnCtrlSlipperyRoadWarning 3;
BA_ "GenSigMaxLatency" SG_ 389 TrcnCtrlSlipperyRoadWarning 50;
BA_ "GenSigCycleTime" SG_ 389 XPRGSystemCap_AllowedPBRel 100;
BA_ "GenSigCycleTimeActive" SG_ 389 XPRGSystemCap_AllowedPBRel 100;
BA_ "GenSigMaxLatency" SG_ 389 XPRGSystemCap_AllowedPBRel 50;
BA_ "GenSigCycleTime" SG_ 389 TransmissionAirPressureLow 100;
BA_ "GenSigCycleTimeActive" SG_ 389 TransmissionAirPressureLow 100;
BA_ "GenSigStartValue" SG_ 389 TransmissionAirPressureLow 3;
BA_ "GenSigMaxLatency" SG_ 389 TransmissionAirPressureLow 50;
BA_ "GenSigCycleTime" SG_ 158 SecuredNeutralPosition 100;
BA_ "GenSigCycleTimeActive" SG_ 158 SecuredNeutralPosition 100;
BA_ "GenSigStartValue" SG_ 158 SecuredNeutralPosition 3;
BA_ "GenSigMaxLatency" SG_ 158 SecuredNeutralPosition 20;
BA_ "GenSigCycleTime" SG_ 158 MirrorSelectLeftWideBtn_stat 100;
BA_ "GenSigCycleTimeActive" SG_ 158 MirrorSelectLeftWideBtn_stat 100;
BA_ "GenSigStartValue" SG_ 158 MirrorSelectLeftWideBtn_stat 3;
BA_ "GenSigMaxLatency" SG_ 158 MirrorSelectLeftWideBtn_stat 20;
BA_ "GenSigCycleTime" SG_ 158 Recirc_ButtonStatus 100;
BA_ "GenSigCycleTimeActive" SG_ 158 Recirc_ButtonStatus 100;
BA_ "GenSigStartValue" SG_ 158 Recirc_ButtonStatus 3;
BA_ "GenSigMaxLatency" SG_ 158 Recirc_ButtonStatus 20;
BA_ "GenSigCycleTime" SG_ 158 AirFlowSelectionUpBtn_stat 100;
BA_ "GenSigCycleTimeActive" SG_ 158 AirFlowSelectionUpBtn_stat 100;
BA_ "GenSigStartValue" SG_ 158 AirFlowSelectionUpBtn_stat 3;
BA_ "GenSigMaxLatency" SG_ 158 AirFlowSelectionUpBtn_stat 20;
BA_ "GenSigCycleTime" SG_ 158 BunkH1AudioOnOff_ButtonStatus 100;
BA_ "GenSigCycleTimeActive" SG_ 158 BunkH1AudioOnOff_ButtonStatus 100;
BA_ "GenSigStartValue" SG_ 158 BunkH1AudioOnOff_ButtonStatus 3;
BA_ "GenSigMaxLatency" SG_ 158 BunkH1AudioOnOff_ButtonStatus 20;
BA_ "GenSigCycleTime" SG_ 158 AC_ButtonStatus 100;
BA_ "GenSigCycleTimeActive" SG_ 158 AC_ButtonStatus 100;
BA_ "GenSigStartValue" SG_ 158 AC_ButtonStatus 3;
BA_ "GenSigMaxLatency" SG_ 158 AC_ButtonStatus 20;
BA_ "GenSigCycleTime" SG_ 158 OverSteerGuidanceStatus 100;
BA_ "GenSigCycleTimeActive" SG_ 158 OverSteerGuidanceStatus 100;
BA_ "GenSigStartValue" SG_ 158 OverSteerGuidanceStatus 3;
BA_ "GenSigMaxLatency" SG_ 158 OverSteerGuidanceStatus 20;
BA_ "GenSigCycleTime" SG_ 158 MirrorSelectLeftMainBtn_stat 100;
BA_ "GenSigCycleTimeActive" SG_ 158 MirrorSelectLeftMainBtn_stat 100;
BA_ "GenSigStartValue" SG_ 158 MirrorSelectLeftMainBtn_stat 3;
BA_ "GenSigMaxLatency" SG_ 158 MirrorSelectLeftMainBtn_stat 20;
BA_ "GenSigCycleTime" SG_ 158 LECM_CabClim_Auto_BtnStat 100;
BA_ "GenSigCycleTimeActive" SG_ 158 LECM_CabClim_Auto_BtnStat 100;
BA_ "GenSigStartValue" SG_ 158 LECM_CabClim_Auto_BtnStat 3;
BA_ "GenSigMaxLatency" SG_ 158 LECM_CabClim_Auto_BtnStat 20;
BA_ "GenSigCycleTime" SG_ 158 ParkBrakeAlert 100;
BA_ "GenSigCycleTimeActive" SG_ 158 ParkBrakeAlert 100;
BA_ "GenSigStartValue" SG_ 158 ParkBrakeAlert 3;
BA_ "GenSigMaxLatency" SG_ 158 ParkBrakeAlert 20;
BA_ "GenSigCycleTime" SG_ 158 LECM_Display_Navi_OK_BtnStat 100;
BA_ "GenSigCycleTimeActive" SG_ 158 LECM_Display_Navi_OK_BtnStat 100;
BA_ "GenSigStartValue" SG_ 158 LECM_Display_Navi_OK_BtnStat 3;
BA_ "GenSigMaxLatency" SG_ 158 LECM_Display_Navi_OK_BtnStat 20;
BA_ "GenSigCycleTime" SG_ 158 LECM_CabClim_AC_BtnStat 100;
BA_ "GenSigCycleTimeActive" SG_ 158 LECM_CabClim_AC_BtnStat 100;
BA_ "GenSigStartValue" SG_ 158 LECM_CabClim_AC_BtnStat 3;
BA_ "GenSigMaxLatency" SG_ 158 LECM_CabClim_AC_BtnStat 20;
BA_ "GenSigCycleTime" SG_ 158 LECMCabClimSetTempSelectGuiReq 100;
BA_ "GenSigCycleTimeActive" SG_ 158 LECMCabClimSetTempSelectGuiReq 100;
BA_ "GenSigStartValue" SG_ 158 LECMCabClimSetTempSelectGuiReq 3;
BA_ "GenSigMaxLatency" SG_ 158 LECMCabClimSetTempSelectGuiReq 20;
BA_ "GenSigCycleTime" SG_ 158 MirrorSelectRightMainBtn_stat 100;
BA_ "GenSigCycleTimeActive" SG_ 158 MirrorSelectRightMainBtn_stat 100;
BA_ "GenSigStartValue" SG_ 158 MirrorSelectRightMainBtn_stat 3;
BA_ "GenSigMaxLatency" SG_ 158 MirrorSelectRightMainBtn_stat 20;
BA_ "GenSigCycleTime" SG_ 158 DaytimeRunningLight_Indication 100;
BA_ "GenSigCycleTimeActive" SG_ 158 DaytimeRunningLight_Indication 100;
BA_ "GenSigStartValue" SG_ 158 DaytimeRunningLight_Indication 3;
BA_ "GenSigMaxLatency" SG_ 158 DaytimeRunningLight_Indication 20;
BA_ "GenSigCycleTime" SG_ 158 DrivingLight_Indication 100;
BA_ "GenSigCycleTimeActive" SG_ 158 DrivingLight_Indication 100;
BA_ "GenSigStartValue" SG_ 158 DrivingLight_Indication 3;
BA_ "GenSigMaxLatency" SG_ 158 DrivingLight_Indication 20;
BA_ "GenSigCycleTime" SG_ 158 FrontFog_Indication 100;
BA_ "GenSigCycleTimeActive" SG_ 158 FrontFog_Indication 100;
BA_ "GenSigStartValue" SG_ 158 FrontFog_Indication 3;
BA_ "GenSigMaxLatency" SG_ 158 FrontFog_Indication 20;
BA_ "GenSigCycleTime" SG_ 158 Auto_ButtonStatus 100;
BA_ "GenSigCycleTimeActive" SG_ 158 Auto_ButtonStatus 100;
BA_ "GenSigStartValue" SG_ 158 Auto_ButtonStatus 3;
BA_ "GenSigMaxLatency" SG_ 158 Auto_ButtonStatus 20;
BA_ "GenSigCycleTime" SG_ 158 KeyfobPreTripButtonStatus 100;
BA_ "GenSigCycleTimeActive" SG_ 158 KeyfobPreTripButtonStatus 100;
BA_ "GenSigStartValue" SG_ 158 KeyfobPreTripButtonStatus 3;
BA_ "GenSigMaxLatency" SG_ 158 KeyfobPreTripButtonStatus 20;
BA_ "GenSigCycleTime" SG_ 158 MirrorSelectRightWideBtn_stat 100;
BA_ "GenSigCycleTimeActive" SG_ 158 MirrorSelectRightWideBtn_stat 100;
BA_ "GenSigStartValue" SG_ 158 MirrorSelectRightWideBtn_stat 3;
BA_ "GenSigMaxLatency" SG_ 158 MirrorSelectRightWideBtn_stat 20;
BA_ "GenSigCycleTime" SG_ 158 ParkingLight_Indication 100;
BA_ "GenSigCycleTimeActive" SG_ 158 ParkingLight_Indication 100;
BA_ "GenSigStartValue" SG_ 158 ParkingLight_Indication 3;
BA_ "GenSigMaxLatency" SG_ 158 ParkingLight_Indication 20;
BA_ "GenSigCycleTime" SG_ 158 DrivingLightPlus_Indication 100;
BA_ "GenSigCycleTimeActive" SG_ 158 DrivingLightPlus_Indication 100;
BA_ "GenSigStartValue" SG_ 158 DrivingLightPlus_Indication 3;
BA_ "GenSigMaxLatency" SG_ 158 DrivingLightPlus_Indication 20;
BA_ "GenSigCycleTime" SG_ 158 BlackPanelMode_ButtonStatus 100;
BA_ "GenSigCycleTimeActive" SG_ 158 BlackPanelMode_ButtonStatus 100;
BA_ "GenSigStartValue" SG_ 158 BlackPanelMode_ButtonStatus 3;
BA_ "GenSigMaxLatency" SG_ 158 BlackPanelMode_ButtonStatus 20;
BA_ "GenSigCycleTime" SG_ 158 ParkHeaterCooler_ButtonStatus 100;
BA_ "GenSigCycleTimeActive" SG_ 158 ParkHeaterCooler_ButtonStatus 100;
BA_ "GenSigStartValue" SG_ 158 ParkHeaterCooler_ButtonStatus 3;
BA_ "GenSigMaxLatency" SG_ 158 ParkHeaterCooler_ButtonStatus 20;
BA_ "GenSigCycleTime" SG_ 158 LECM_CabClim_FrPwr_BtnStat 100;
BA_ "GenSigCycleTimeActive" SG_ 158 LECM_CabClim_FrPwr_BtnStat 100;
BA_ "GenSigStartValue" SG_ 158 LECM_CabClim_FrPwr_BtnStat 3;
BA_ "GenSigMaxLatency" SG_ 158 LECM_CabClim_FrPwr_BtnStat 20;
BA_ "GenSigCycleTime" SG_ 158 LECM_CabClim_Pwr_BtnStat 100;
BA_ "GenSigCycleTimeActive" SG_ 158 LECM_CabClim_Pwr_BtnStat 100;
BA_ "GenSigStartValue" SG_ 158 LECM_CabClim_Pwr_BtnStat 3;
BA_ "GenSigMaxLatency" SG_ 158 LECM_CabClim_Pwr_BtnStat 20;
BA_ "GenSigCycleTime" SG_ 158 AirFlowSelectionFrontBtn_stat 100;
BA_ "GenSigCycleTimeActive" SG_ 158 AirFlowSelectionFrontBtn_stat 100;
BA_ "GenSigStartValue" SG_ 158 AirFlowSelectionFrontBtn_stat 3;
BA_ "GenSigMaxLatency" SG_ 158 AirFlowSelectionFrontBtn_stat 20;
BA_ "GenSigCycleTime" SG_ 158 BlackPanelMode_ButtonStatus3 100;
BA_ "GenSigCycleTimeActive" SG_ 158 BlackPanelMode_ButtonStatus3 100;
BA_ "GenSigStartValue" SG_ 158 BlackPanelMode_ButtonStatus3 3;
BA_ "GenSigMaxLatency" SG_ 158 BlackPanelMode_ButtonStatus3 20;
BA_ "GenSigCycleTime" SG_ 158 LECM_CabClim_Sync_GuiReq 100;
BA_ "GenSigCycleTimeActive" SG_ 158 LECM_CabClim_Sync_GuiReq 100;
BA_ "GenSigStartValue" SG_ 158 LECM_CabClim_Sync_GuiReq 3;
BA_ "GenSigMaxLatency" SG_ 158 LECM_CabClim_Sync_GuiReq 20;
BA_ "GenSigCycleTime" SG_ 158 LiftAxle1AutoLiftSelected 100;
BA_ "GenSigCycleTimeActive" SG_ 158 LiftAxle1AutoLiftSelected 100;
BA_ "GenSigStartValue" SG_ 158 LiftAxle1AutoLiftSelected 3;
BA_ "GenSigMaxLatency" SG_ 158 LiftAxle1AutoLiftSelected 20;
BA_ "GenSigCycleTime" SG_ 158 LECM_Ent_OnOff_BtnStat 100;
BA_ "GenSigCycleTimeActive" SG_ 158 LECM_Ent_OnOff_BtnStat 100;
BA_ "GenSigStartValue" SG_ 158 LECM_Ent_OnOff_BtnStat 3;
BA_ "GenSigMaxLatency" SG_ 158 LECM_Ent_OnOff_BtnStat 20;
BA_REL_ "GenSigFirstTimeoutTime" BU_SG_REL_ IC SG_ 691 AvailableGearsWithHigherRatio 3000;
BA_REL_ "GenSigTimeoutTime" BU_SG_REL_ IC SG_ 691 AvailableGearsWithHigherRatio 600;
BA_REL_ "GenSigFirstTimeoutTime" BU_SG_REL_ IC SG_ 691 EngineFuelRate 3000;
BA_REL_ "GenSigTimeoutTime" BU_SG_REL_ IC SG_ 691 EngineFuelRate 600;
BA_REL_ "GenSigFirstTimeoutTime" BU_SG_REL_ IC SG_ 691 DirectionIndicatorLightsStatus 3000;
BA_REL_ "GenSigTimeoutTime" BU_SG_REL_ IC SG_ 691 DirectionIndicatorLightsStatus 600;
BA_REL_ "GenSigFirstTimeoutTime" BU_SG_REL_ IC SG_ 691 APM_ParkBrakeApplicationMode2 3000;
BA_REL_ "GenSigTimeoutTime" BU_SG_REL_ IC SG_ 691 APM_ParkBrakeApplicationMode2 600;
BA_REL_ "GenSigFirstTimeoutTime" BU_SG_REL_ IC SG_ 691 ActualEngineRetarderPercentTrq 3000;
BA_REL_ "GenSigTimeoutTime" BU_SG_REL_ IC SG_ 691 ActualEngineRetarderPercentTrq 600;
BA_REL_ "GenSigFirstTimeoutTime" BU_SG_REL_ IC SG_ 691 ACC_SGO_Status 3000;
BA_REL_ "GenSigTimeoutTime" BU_SG_REL_ IC SG_ 691 ACC_SGO_Status 600;
BA_REL_ "GenSigFirstTimeoutTime" BU_SG_REL_ IC SG_ 691 PV_HeadLightLevel 3000;
BA_REL_ "GenSigTimeoutTime" BU_SG_REL_ IC SG_ 691 PV_HeadLightLevel 600;
BA_REL_ "GenSigFirstTimeoutTime" BU_SG_REL_ IC SG_ 691 ActualDrvlnRetdrPercentTorque 3000;
BA_REL_ "GenSigTimeoutTime" BU_SG_REL_ IC SG_ 691 ActualDrvlnRetdrPercentTorque 600;
BA_REL_ "GenSigFirstTimeoutTime" BU_SG_REL_ IC SG_ 691 AvailableGearsWithLowerRatio 3000;
BA_REL_ "GenSigTimeoutTime" BU_SG_REL_ IC SG_ 691 AvailableGearsWithLowerRatio 600;
BA_REL_ "GenSigFirstTimeoutTime" BU_SG_REL_ IC SG_ 690 SetHSAOperation 3000;
BA_REL_ "GenSigTimeoutTime" BU_SG_REL_ IC SG_ 690 SetHSAOperation 600;
BA_REL_ "GenSigFirstTimeoutTime" BU_SG_REL_ IC SG_ 690 PS_FogLightFront 3000;
BA_REL_ "GenSigTimeoutTime" BU_SG_REL_ IC SG_ 690 PS_FogLightFront 600;
BA_REL_ "GenSigFirstTimeoutTime" BU_SG_REL_ IC SG_ 690 CACCStatus 3000;
BA_REL_ "GenSigTimeoutTime" BU_SG_REL_ IC SG_ 690 CACCStatus 600;
BA_REL_ "GenSigFirstTimeoutTime" BU_SG_REL_ IC SG_ 690 Cab12VSupplyStatus 3000;
BA_REL_ "GenSigTimeoutTime" BU_SG_REL_ IC SG_ 690 Cab12VSupplyStatus 600;
BA_REL_ "GenSigFirstTimeoutTime" BU_SG_REL_ IC SG_ 690 TransmissionDrivingMode 3000;
BA_REL_ "GenSigTimeoutTime" BU_SG_REL_ IC SG_ 690 TransmissionDrivingMode 600;
BA_REL_ "GenSigFirstTimeoutTime" BU_SG_REL_ IC SG_ 690 LowAirPressureAlert 3000;
BA_REL_ "GenSigTimeoutTime" BU_SG_REL_ IC SG_ 690 LowAirPressureAlert 600;
BA_REL_ "GenSigFirstTimeoutTime" BU_SG_REL_ IC SG_ 690 TemporaryRSLSwitchStatus 3000;
BA_REL_ "GenSigTimeoutTime" BU_SG_REL_ IC SG_ 690 TemporaryRSLSwitchStatus 600;
BA_REL_ "GenSigFirstTimeoutTime" BU_SG_REL_ IC SG_ 690 BatterySOCAlertRawData_rqst 3000;
BA_REL_ "GenSigTimeoutTime" BU_SG_REL_ IC SG_ 690 BatterySOCAlertRawData_rqst 600;
BA_REL_ "GenSigFirstTimeoutTime" BU_SG_REL_ CCM SG_ 690 BatterySOCAlertRawData_rqst 3000;
BA_REL_ "GenSigTimeoutTime" BU_SG_REL_ CCM SG_ 690 BatterySOCAlertRawData_rqst 600;
BA_REL_ "GenSigFirstTimeoutTime" BU_SG_REL_ IC SG_ 690 BatteryTempAlertRawData_rqst 3000;
BA_REL_ "GenSigTimeoutTime" BU_SG_REL_ IC SG_ 690 BatteryTempAlertRawData_rqst 600;
BA_REL_ "GenSigFirstTimeoutTime" BU_SG_REL_ IC SG_ 690 BrakeTemperatureWarning 3000;
BA_REL_ "GenSigTimeoutTime" BU_SG_REL_ IC SG_ 690 BrakeTemperatureWarning 600;
BA_REL_ "GenSigFirstTimeoutTime" BU_SG_REL_ IC SG_ 690 WheelSlipControllerMode 3000;
BA_REL_ "GenSigTimeoutTime" BU_SG_REL_ IC SG_ 690 WheelSlipControllerMode 600;
BA_REL_ "GenSigFirstTimeoutTime" BU_SG_REL_ IC SG_ 690 Rainsensor_Indication 3000;
BA_REL_ "GenSigTimeoutTime" BU_SG_REL_ IC SG_ 690 Rainsensor_Indication 600;
BA_REL_ "GenSigFirstTimeoutTime" BU_SG_REL_ IC SG_ 690 ESCHealthStatus 3000;
BA_REL_ "GenSigTimeoutTime" BU_SG_REL_ IC SG_ 690 ESCHealthStatus 600;
BA_REL_ "GenSigFirstTimeoutTime" BU_SG_REL_ IC SG_ 690 TLInflationAcceptance_stat 3000;
BA_REL_ "GenSigTimeoutTime" BU_SG_REL_ IC SG_ 690 TLInflationAcceptance_stat 600;
BA_REL_ "GenSigFirstTimeoutTime" BU_SG_REL_ IC SG_ 690 AutoLoadCutOffState 3000;
BA_REL_ "GenSigTimeoutTime" BU_SG_REL_ IC SG_ 690 AutoLoadCutOffState 600;
BA_REL_ "GenSigFirstTimeoutTime" BU_SG_REL_ IC SG_ 690 TransmissionOilTempHigh 3000;
BA_REL_ "GenSigTimeoutTime" BU_SG_REL_ IC SG_ 690 TransmissionOilTempHigh 600;
BA_REL_ "GenSigFirstTimeoutTime" BU_SG_REL_ IC SG_ 690 ECSLimpHomeNotification 3000;
BA_REL_ "GenSigTimeoutTime" BU_SG_REL_ IC SG_ 690 ECSLimpHomeNotification 600;
BA_REL_ "GenSigFirstTimeoutTime" BU_SG_REL_ IC SG_ 690 EqualizerUnbalance 3000;
BA_REL_ "GenSigTimeoutTime" BU_SG_REL_ IC SG_ 690 EqualizerUnbalance 600;
BA_REL_ "GenSigFirstTimeoutTime" BU_SG_REL_ IC SG_ 690 AutGearSplitPosition 3000;
BA_REL_ "GenSigTimeoutTime" BU_SG_REL_ IC SG_ 690 AutGearSplitPosition 600;
BA_REL_ "GenSigFirstTimeoutTime" BU_SG_REL_ IC SG_ 690 BatterySOCAlert_rqst 3000;
BA_REL_ "GenSigTimeoutTime" BU_SG_REL_ IC SG_ 690 BatterySOCAlert_rqst 600;
BA_REL_ "GenSigFirstTimeoutTime" BU_SG_REL_ IC SG_ 690 DriveModeSwitchUserOverride 3000;
BA_REL_ "GenSigTimeoutTime" BU_SG_REL_ IC SG_ 690 DriveModeSwitchUserOverride 600;
BA_REL_ "GenSigFirstTimeoutTime" BU_SG_REL_ IC SG_ 690 BatteryTempAlert_rqst 3000;
BA_REL_ "GenSigTimeoutTime" BU_SG_REL_ IC SG_ 690 BatteryTempAlert_rqst 600;
BA_REL_ "GenSigFirstTimeoutTime" BU_SG_REL_ IC SG_ 690 TrailerEBSFault 3000;
BA_REL_ "GenSigTimeoutTime" BU_SG_REL_ IC SG_ 690 TrailerEBSFault 600;
BA_REL_ "GenSigFirstTimeoutTime" BU_SG_REL_ CCM SG_ 689 ParkHeaterTimerReleased_stat 3000;
BA_REL_ "GenSigTimeoutTime" BU_SG_REL_ CCM SG_ 689 ParkHeaterTimerReleased_stat 600;
BA_REL_ "GenSigFirstTimeoutTime" BU_SG_REL_ IC SG_ 689 Trail2TPMLostCom 3000;
BA_REL_ "GenSigTimeoutTime" BU_SG_REL_ IC SG_ 689 Trail2TPMLostCom 600;
BA_REL_ "GenSigFirstTimeoutTime" BU_SG_REL_ IC SG_ 689 BrakeInterlockStatus 3000;
BA_REL_ "GenSigTimeoutTime" BU_SG_REL_ IC SG_ 689 BrakeInterlockStatus 600;
BA_REL_ "GenSigFirstTimeoutTime" BU_SG_REL_ IC SG_ 689 AutoWheelBrakesDownshiftSugges 3000;
BA_REL_ "GenSigTimeoutTime" BU_SG_REL_ IC SG_ 689 AutoWheelBrakesDownshiftSugges 600;
BA_REL_ "GenSigFirstTimeoutTime" BU_SG_REL_ IC SG_ 689 RearAxle2DiffLock_stat 3000;
BA_REL_ "GenSigTimeoutTime" BU_SG_REL_ IC SG_ 689 RearAxle2DiffLock_stat 600;
BA_REL_ "GenSigFirstTimeoutTime" BU_SG_REL_ IC SG_ 689 CentralRearDiffLock_stat 3000;
BA_REL_ "GenSigTimeoutTime" BU_SG_REL_ IC SG_ 689 CentralRearDiffLock_stat 600;
BA_REL_ "GenSigFirstTimeoutTime" BU_SG_REL_ IC SG_ 689 TransmissionBrakeMode 3000;
BA_REL_ "GenSigTimeoutTime" BU_SG_REL_ IC SG_ 689 TransmissionBrakeMode 600;
BA_REL_ "GenSigFirstTimeoutTime" BU_SG_REL_ IC SG_ 689 PS_HeadLightAdjustment 3000;
BA_REL_ "GenSigTimeoutTime" BU_SG_REL_ IC SG_ 689 PS_HeadLightAdjustment 600;
BA_REL_ "GenSigFirstTimeoutTime" BU_SG_REL_ IC SG_ 689 ReducedLoadMode_stat 3000;
BA_REL_ "GenSigTimeoutTime" BU_SG_REL_ IC SG_ 689 ReducedLoadMode_stat 600;
BA_REL_ "GenSigFirstTimeoutTime" BU_SG_REL_ CCM SG_ 689 ReducedLoadMode_stat 3000;
BA_REL_ "GenSigTimeoutTime" BU_SG_REL_ CCM SG_ 689 ReducedLoadMode_stat 600;
BA_REL_ "GenSigFirstTimeoutTime" BU_SG_REL_ IC SG_ 689 FrontWheelDifflockRequest 3000;
BA_REL_ "GenSigTimeoutTime" BU_SG_REL_ IC SG_ 689 FrontWheelDifflockRequest 600;
BA_REL_ "GenSigFirstTimeoutTime" BU_SG_REL_ IC SG_ 689 ABSEBSAmberWarningSignal 3000;
BA_REL_ "GenSigTimeoutTime" BU_SG_REL_ IC SG_ 689 ABSEBSAmberWarningSignal 600;
BA_REL_ "GenSigFirstTimeoutTime" BU_SG_REL_ IC SG_ 689 DifferentialLockStateFrAxle1 3000;
BA_REL_ "GenSigTimeoutTime" BU_SG_REL_ IC SG_ 689 DifferentialLockStateFrAxle1 600;
BA_REL_ "GenSigFirstTimeoutTime" BU_SG_REL_ IC SG_ 689 Trail1TPMLostCom 3000;
BA_REL_ "GenSigTimeoutTime" BU_SG_REL_ IC SG_ 689 Trail1TPMLostCom 600;
BA_REL_ "GenSigFirstTimeoutTime" BU_SG_REL_ IC SG_ 689 TrailerInflationPossible_stat 3000;
BA_REL_ "GenSigTimeoutTime" BU_SG_REL_ IC SG_ 689 TrailerInflationPossible_stat 600;
BA_REL_ "GenSigFirstTimeoutTime" BU_SG_REL_ IC SG_ 689 DrivelineRetarderStat 3000;
BA_REL_ "GenSigTimeoutTime" BU_SG_REL_ IC SG_ 689 DrivelineRetarderStat 600;
BA_REL_ "GenSigFirstTimeoutTime" BU_SG_REL_ IC SG_ 689 PS_FogLightRear 3000;
BA_REL_ "GenSigTimeoutTime" BU_SG_REL_ IC SG_ 689 PS_FogLightRear 600;
BA_REL_ "GenSigFirstTimeoutTime" BU_SG_REL_ IC SG_ 689 PS_MainBeam 3000;
BA_REL_ "GenSigTimeoutTime" BU_SG_REL_ IC SG_ 689 PS_MainBeam 600;
BA_REL_ "GenSigFirstTimeoutTime" BU_SG_REL_ IC SG_ 689 DeCompActive 3000;
BA_REL_ "GenSigTimeoutTime" BU_SG_REL_ IC SG_ 689 DeCompActive 600;
BA_REL_ "GenSigFirstTimeoutTime" BU_SG_REL_ IC SG_ 689 ECSManStandbyStatus 3000;
BA_REL_ "GenSigTimeoutTime" BU_SG_REL_ IC SG_ 689 ECSManStandbyStatus 600;
BA_REL_ "GenSigFirstTimeoutTime" BU_SG_REL_ IC SG_ 689 AutoPBRelease_stat 3000;
BA_REL_ "GenSigTimeoutTime" BU_SG_REL_ IC SG_ 689 AutoPBRelease_stat 600;
BA_REL_ "GenSigFirstTimeoutTime" BU_SG_REL_ IC SG_ 689 Trail4TPMLostCom 3000;
BA_REL_ "GenSigTimeoutTime" BU_SG_REL_ IC SG_ 689 Trail4TPMLostCom 600;
BA_REL_ "GenSigFirstTimeoutTime" BU_SG_REL_ IC SG_ 689 EBSRedWarningSignal 3000;
BA_REL_ "GenSigTimeoutTime" BU_SG_REL_ IC SG_ 689 EBSRedWarningSignal 600;
BA_REL_ "GenSigFirstTimeoutTime" BU_SG_REL_ IC SG_ 689 DifferentialLockStateCentral 3000;
BA_REL_ "GenSigTimeoutTime" BU_SG_REL_ IC SG_ 689 DifferentialLockStateCentral 600;
BA_REL_ "GenSigFirstTimeoutTime" BU_SG_REL_ IC SG_ 689 RearAxle3DiffLock_stat 3000;
BA_REL_ "GenSigTimeoutTime" BU_SG_REL_ IC SG_ 689 RearAxle3DiffLock_stat 600;
BA_REL_ "GenSigFirstTimeoutTime" BU_SG_REL_ IC SG_ 689 AntiLockBrakingActive 3000;
BA_REL_ "GenSigTimeoutTime" BU_SG_REL_ IC SG_ 689 AntiLockBrakingActive 600;
BA_REL_ "GenSigFirstTimeoutTime" BU_SG_REL_ IC SG_ 689 RearAxle1DiffLock_stat 3000;
BA_REL_ "GenSigTimeoutTime" BU_SG_REL_ IC SG_ 689 RearAxle1DiffLock_stat 600;
BA_REL_ "GenSigFirstTimeoutTime" BU_SG_REL_ IC SG_ 689 Trail5TPMLostCom 3000;
BA_REL_ "GenSigTimeoutTime" BU_SG_REL_ IC SG_ 689 Trail5TPMLostCom 600;
BA_REL_ "GenSigFirstTimeoutTime" BU_SG_REL_ IC SG_ 689 PS_PositionLight 3000;
BA_REL_ "GenSigTimeoutTime" BU_SG_REL_ IC SG_ 689 PS_PositionLight 600;
BA_REL_ "GenSigFirstTimeoutTime" BU_SG_REL_ IC SG_ 689 BatteryCapacity_Ack 3000;
BA_REL_ "GenSigTimeoutTime" BU_SG_REL_ IC SG_ 689 BatteryCapacity_Ack 600;
BA_REL_ "GenSigFirstTimeoutTime" BU_SG_REL_ IC SG_ 689 Trail3TPMLostCom 3000;
BA_REL_ "GenSigTimeoutTime" BU_SG_REL_ IC SG_ 689 Trail3TPMLostCom 600;
BA_REL_ "GenSigFirstTimeoutTime" BU_SG_REL_ IC SG_ 689 ParkBrakeWorkshopMode 3000;
BA_REL_ "GenSigTimeoutTime" BU_SG_REL_ IC SG_ 689 ParkBrakeWorkshopMode 600;
BA_REL_ "GenSigFirstTimeoutTime" BU_SG_REL_ IC SG_ 689 LowTempClutchInfo 3000;
BA_REL_ "GenSigTimeoutTime" BU_SG_REL_ IC SG_ 689 LowTempClutchInfo 600;
BA_REL_ "GenSigFirstTimeoutTime" BU_SG_REL_ IC SG_ 688 APMSafetyWarning_CRC 3000;
BA_REL_ "GenSigTimeoutTime" BU_SG_REL_ IC SG_ 688 APMSafetyWarning_CRC 600;
BA_REL_ "GenSigFirstTimeoutTime" BU_SG_REL_ IC SG_ 688 PBStatus_CRC 3000;
BA_REL_ "GenSigTimeoutTime" BU_SG_REL_ IC SG_ 688 PBStatus_CRC 600;
BA_REL_ "GenSigFirstTimeoutTime" BU_SG_REL_ IC SG_ 688 TrailerWithoutABS 3000;
BA_REL_ "GenSigTimeoutTime" BU_SG_REL_ IC SG_ 688 TrailerWithoutABS 600;
BA_REL_ "GenSigFirstTimeoutTime" BU_SG_REL_ IC SG_ 688 APMSafetyWarning_RedRqst 3000;
BA_REL_ "GenSigTimeoutTime" BU_SG_REL_ IC SG_ 688 APMSafetyWarning_RedRqst 600;
BA_REL_ "GenSigFirstTimeoutTime" BU_SG_REL_ IC SG_ 688 EcoRollEnabledStatus 3000;
BA_REL_ "GenSigTimeoutTime" BU_SG_REL_ IC SG_ 688 EcoRollEnabledStatus 600;
BA_REL_ "GenSigFirstTimeoutTime" BU_SG_REL_ IC SG_ 688 PBStatus_Actuation 3000;
BA_REL_ "GenSigTimeoutTime" BU_SG_REL_ IC SG_ 688 PBStatus_Actuation 600;
BA_REL_ "GenSigFirstTimeoutTime" BU_SG_REL_ IC SG_ 688 GearShiftingRec_Steps 3000;
BA_REL_ "GenSigTimeoutTime" BU_SG_REL_ IC SG_ 688 GearShiftingRec_Steps 600;
BA_REL_ "GenSigFirstTimeoutTime" BU_SG_REL_ IC SG_ 688 PBStatus_IntegrityLvl 3000;
BA_REL_ "GenSigTimeoutTime" BU_SG_REL_ IC SG_ 688 PBStatus_IntegrityLvl 600;
BA_REL_ "GenSigFirstTimeoutTime" BU_SG_REL_ IC SG_ 688 GearShiftingRec_Direction 3000;
BA_REL_ "GenSigTimeoutTime" BU_SG_REL_ IC SG_ 688 GearShiftingRec_Direction 600;
BA_REL_ "GenSigFirstTimeoutTime" BU_SG_REL_ IC SG_ 688 APM_TrailerCircPressureStatus 3000;
BA_REL_ "GenSigTimeoutTime" BU_SG_REL_ IC SG_ 688 APM_TrailerCircPressureStatus 600;
BA_REL_ "GenSigFirstTimeoutTime" BU_SG_REL_ IC SG_ 688 RearPropulsionStat_Rear2Axle 3000;
BA_REL_ "GenSigTimeoutTime" BU_SG_REL_ IC SG_ 688 RearPropulsionStat_Rear2Axle 600;
BA_REL_ "GenSigFirstTimeoutTime" BU_SG_REL_ IC SG_ 688 RearPropulsionStat_Rear1Axle 3000;
BA_REL_ "GenSigTimeoutTime" BU_SG_REL_ IC SG_ 688 RearPropulsionStat_Rear1Axle 600;
BA_REL_ "GenSigFirstTimeoutTime" BU_SG_REL_ IC SG_ 688 RearPropulsionStat_Rear3Axle 3000;
BA_REL_ "GenSigTimeoutTime" BU_SG_REL_ IC SG_ 688 RearPropulsionStat_Rear3Axle 600;
BA_REL_ "GenSigFirstTimeoutTime" BU_SG_REL_ IC SG_ 688 PBStatus_SqC 3000;
BA_REL_ "GenSigTimeoutTime" BU_SG_REL_ IC SG_ 688 PBStatus_SqC 600;
BA_REL_ "GenSigFirstTimeoutTime" BU_SG_REL_ IC SG_ 688 APMSafetyWarning_SqC 3000;
BA_REL_ "GenSigTimeoutTime" BU_SG_REL_ IC SG_ 688 APMSafetyWarning_SqC 600;
BA_REL_ "GenSigFirstTimeoutTime" BU_SG_REL_ IC SG_ 688 APMSafetyWarning_YellowRqst 3000;
BA_REL_ "GenSigTimeoutTime" BU_SG_REL_ IC SG_ 688 APMSafetyWarning_YellowRqst 600;
BA_REL_ "GenSigFirstTimeoutTime" BU_SG_REL_ IC SG_ 394 LongitudinalAcceleration 3000;
BA_REL_ "GenSigTimeoutTime" BU_SG_REL_ IC SG_ 394 LongitudinalAcceleration 300;
BA_REL_ "GenSigFirstTimeoutTime" BU_SG_REL_ IC SG_ 394 CCSetSpeed 3000;
BA_REL_ "GenSigTimeoutTime" BU_SG_REL_ IC SG_ 394 CCSetSpeed 300;
BA_REL_ "GenSigFirstTimeoutTime" BU_SG_REL_ IC SG_ 393 EngineActiveStatus 3000;
BA_REL_ "GenSigTimeoutTime" BU_SG_REL_ IC SG_ 393 EngineActiveStatus 300;
BA_REL_ "GenSigFirstTimeoutTime" BU_SG_REL_ IC SG_ 393 BackLightDimming_Status3 3000;
BA_REL_ "GenSigTimeoutTime" BU_SG_REL_ IC SG_ 393 BackLightDimming_Status3 300;
BA_REL_ "GenSigFirstTimeoutTime" BU_SG_REL_ IC SG_ 393 FrontAxleSpeed 3000;
BA_REL_ "GenSigTimeoutTime" BU_SG_REL_ IC SG_ 393 FrontAxleSpeed 300;
BA_REL_ "GenSigFirstTimeoutTime" BU_SG_REL_ IC SG_ 393 EPBBackupMode 3000;
BA_REL_ "GenSigTimeoutTime" BU_SG_REL_ IC SG_ 393 EPBBackupMode 300;
BA_REL_ "GenSigFirstTimeoutTime" BU_SG_REL_ IC SG_ 393 BrakePedalTestState 3000;
BA_REL_ "GenSigTimeoutTime" BU_SG_REL_ IC SG_ 393 BrakePedalTestState 300;
BA_REL_ "GenSigFirstTimeoutTime" BU_SG_REL_ IC SG_ 393 DriverPresenceStatus 3000;
BA_REL_ "GenSigTimeoutTime" BU_SG_REL_ IC SG_ 393 DriverPresenceStatus 300;
BA_REL_ "GenSigFirstTimeoutTime" BU_SG_REL_ IC SG_ 393 ParkBrakeApplicationMode2 3000;
BA_REL_ "GenSigTimeoutTime" BU_SG_REL_ IC SG_ 393 ParkBrakeApplicationMode2 300;
BA_REL_ "GenSigFirstTimeoutTime" BU_SG_REL_ IC SG_ 393 RampLevelStatus 3000;
BA_REL_ "GenSigTimeoutTime" BU_SG_REL_ IC SG_ 393 RampLevelStatus 300;
BA_REL_ "GenSigFirstTimeoutTime" BU_SG_REL_ IC SG_ 393 ParkBrakeReleaseMode2 3000;
BA_REL_ "GenSigTimeoutTime" BU_SG_REL_ IC SG_ 393 ParkBrakeReleaseMode2 300;
BA_REL_ "GenSigFirstTimeoutTime" BU_SG_REL_ IC SG_ 393 BackLightDimming_Status 3000;
BA_REL_ "GenSigTimeoutTime" BU_SG_REL_ IC SG_ 393 BackLightDimming_Status 300;
BA_REL_ "GenSigFirstTimeoutTime" BU_SG_REL_ IC SG_ 393 HeightControlMode 3000;
BA_REL_ "GenSigTimeoutTime" BU_SG_REL_ IC SG_ 393 HeightControlMode 300;
BA_REL_ "GenSigFirstTimeoutTime" BU_SG_REL_ IC SG_ 393 FifthWheelLockingInformation 3000;
BA_REL_ "GenSigTimeoutTime" BU_SG_REL_ IC SG_ 393 FifthWheelLockingInformation 300;
BA_REL_ "GenSigFirstTimeoutTime" BU_SG_REL_ IC SG_ 392 FirstAxleLowerPrioSelected 3000;
BA_REL_ "GenSigTimeoutTime" BU_SG_REL_ IC SG_ 392 FirstAxleLowerPrioSelected 300;
BA_REL_ "GenSigFirstTimeoutTime" BU_SG_REL_ IC SG_ 392 ESCState 3000;
BA_REL_ "GenSigTimeoutTime" BU_SG_REL_ IC SG_ 392 ESCState 300;
BA_REL_ "GenSigFirstTimeoutTime" BU_SG_REL_ IC SG_ 392 KneelingInformation 3000;
BA_REL_ "GenSigTimeoutTime" BU_SG_REL_ IC SG_ 392 KneelingInformation 300;
BA_REL_ "GenSigFirstTimeoutTime" BU_SG_REL_ IC SG_ 392 TrailerTest_stat 3000;
BA_REL_ "GenSigTimeoutTime" BU_SG_REL_ IC SG_ 392 TrailerTest_stat 300;
BA_REL_ "GenSigFirstTimeoutTime" BU_SG_REL_ IC SG_ 392 ThreePosDifflockSwitch_stat 3000;
BA_REL_ "GenSigTimeoutTime" BU_SG_REL_ IC SG_ 392 ThreePosDifflockSwitch_stat 300;
BA_REL_ "GenSigFirstTimeoutTime" BU_SG_REL_ IC SG_ 392 HillHolderMode 3000;
BA_REL_ "GenSigTimeoutTime" BU_SG_REL_ IC SG_ 392 HillHolderMode 300;
BA_REL_ "GenSigFirstTimeoutTime" BU_SG_REL_ IC SG_ 392 RampHeightOutsideTargetRange 3000;
BA_REL_ "GenSigTimeoutTime" BU_SG_REL_ IC SG_ 392 RampHeightOutsideTargetRange 300;
BA_REL_ "GenSigFirstTimeoutTime" BU_SG_REL_ CCM SG_ 392 ShortStopHeater_status 3000;
BA_REL_ "GenSigTimeoutTime" BU_SG_REL_ CCM SG_ 392 ShortStopHeater_status 300;
BA_REL_ "GenSigFirstTimeoutTime" BU_SG_REL_ IC SG_ 392 LuggageAjar_stat 3000;
BA_REL_ "GenSigTimeoutTime" BU_SG_REL_ IC SG_ 392 LuggageAjar_stat 300;
BA_REL_ "GenSigFirstTimeoutTime" BU_SG_REL_ IC SG_ 392 LoadDistributionRequestedACK 3000;
BA_REL_ "GenSigTimeoutTime" BU_SG_REL_ IC SG_ 392 LoadDistributionRequestedACK 300;
BA_REL_ "GenSigFirstTimeoutTime" BU_SG_REL_ IC SG_ 392 StretchBrake_Stat 3000;
BA_REL_ "GenSigTimeoutTime" BU_SG_REL_ IC SG_ 392 StretchBrake_Stat 300;
BA_REL_ "GenSigFirstTimeoutTime" BU_SG_REL_ IC SG_ 392 MirrorHeatingMode 3000;
BA_REL_ "GenSigTimeoutTime" BU_SG_REL_ IC SG_ 392 MirrorHeatingMode 300;
BA_REL_ "GenSigFirstTimeoutTime" BU_SG_REL_ CCM SG_ 392 MirrorHeatingMode 3000;
BA_REL_ "GenSigTimeoutTime" BU_SG_REL_ CCM SG_ 392 MirrorHeatingMode 300;
BA_REL_ "GenSigFirstTimeoutTime" BU_SG_REL_ IC SG_ 392 ESCStatus 3000;
BA_REL_ "GenSigTimeoutTime" BU_SG_REL_ IC SG_ 392 ESCStatus 300;
BA_REL_ "GenSigFirstTimeoutTime" BU_SG_REL_ IC SG_ 392 DriverRetarderRequest 3000;
BA_REL_ "GenSigTimeoutTime" BU_SG_REL_ IC SG_ 392 DriverRetarderRequest 300;
BA_REL_ "GenSigFirstTimeoutTime" BU_SG_REL_ IC SG_ 392 PBReleaseAcceptance_stat 3000;
BA_REL_ "GenSigTimeoutTime" BU_SG_REL_ IC SG_ 392 PBReleaseAcceptance_stat 300;
BA_REL_ "GenSigFirstTimeoutTime" BU_SG_REL_ CCM SG_ 392 PSWindowPosition 3000;
BA_REL_ "GenSigTimeoutTime" BU_SG_REL_ CCM SG_ 392 PSWindowPosition 300;
BA_REL_ "GenSigFirstTimeoutTime" BU_SG_REL_ CCM SG_ 392 RemoteParkingClimateRqst 3000;
BA_REL_ "GenSigTimeoutTime" BU_SG_REL_ CCM SG_ 392 RemoteParkingClimateRqst 300;
BA_REL_ "GenSigFirstTimeoutTime" BU_SG_REL_ IC SG_ 392 AutoDefogmode_Status 3000;
BA_REL_ "GenSigTimeoutTime" BU_SG_REL_ IC SG_ 392 AutoDefogmode_Status 300;
BA_REL_ "GenSigFirstTimeoutTime" BU_SG_REL_ IC SG_ 392 RideHeightOutsideTargetRange 3000;
BA_REL_ "GenSigTimeoutTime" BU_SG_REL_ IC SG_ 392 RideHeightOutsideTargetRange 300;
BA_REL_ "GenSigFirstTimeoutTime" BU_SG_REL_ IC SG_ 392 DriveLevelPosUserInteraction 3000;
BA_REL_ "GenSigTimeoutTime" BU_SG_REL_ IC SG_ 392 DriveLevelPosUserInteraction 300;
BA_REL_ "GenSigFirstTimeoutTime" BU_SG_REL_ IC SG_ 392 HillStartAidStatus 3000;
BA_REL_ "GenSigTimeoutTime" BU_SG_REL_ IC SG_ 392 HillStartAidStatus 300;
BA_REL_ "GenSigFirstTimeoutTime" BU_SG_REL_ IC SG_ 391 AcceleratorPedalTestStatus 3000;
BA_REL_ "GenSigTimeoutTime" BU_SG_REL_ IC SG_ 391 AcceleratorPedalTestStatus 300;
BA_REL_ "GenSigFirstTimeoutTime" BU_SG_REL_ CCM SG_ 391 AutoDefogmode_Selection 3000;
BA_REL_ "GenSigTimeoutTime" BU_SG_REL_ CCM SG_ 391 AutoDefogmode_Selection 300;
BA_REL_ "GenSigFirstTimeoutTime" BU_SG_REL_ IC SG_ 391 ESCDriverReq 3000;
BA_REL_ "GenSigTimeoutTime" BU_SG_REL_ IC SG_ 391 ESCDriverReq 300;
BA_REL_ "GenSigFirstTimeoutTime" BU_SG_REL_ IC SG_ 391 UnevenLoadWarning 3000;
BA_REL_ "GenSigTimeoutTime" BU_SG_REL_ IC SG_ 391 UnevenLoadWarning 300;
BA_REL_ "GenSigFirstTimeoutTime" BU_SG_REL_ IC SG_ 391 RrInterAxlDiffLockActvnFuncReq 3000;
BA_REL_ "GenSigTimeoutTime" BU_SG_REL_ IC SG_ 391 RrInterAxlDiffLockActvnFuncReq 300;
BA_REL_ "GenSigFirstTimeoutTime" BU_SG_REL_ IC SG_ 391 DoorsAjar_stat 3000;
BA_REL_ "GenSigTimeoutTime" BU_SG_REL_ IC SG_ 391 DoorsAjar_stat 300;
BA_REL_ "GenSigFirstTimeoutTime" BU_SG_REL_ IC SG_ 391 ABSManAutoInhibitionStat 3000;
BA_REL_ "GenSigTimeoutTime" BU_SG_REL_ IC SG_ 391 ABSManAutoInhibitionStat 300;
BA_REL_ "GenSigFirstTimeoutTime" BU_SG_REL_ IC SG_ 391 RrInterAxlDiffLockActvnDrvrReq 3000;
BA_REL_ "GenSigTimeoutTime" BU_SG_REL_ IC SG_ 391 RrInterAxlDiffLockActvnDrvrReq 300;
BA_REL_ "GenSigFirstTimeoutTime" BU_SG_REL_ CCM SG_ 391 ACMode_Selection 3000;
BA_REL_ "GenSigTimeoutTime" BU_SG_REL_ CCM SG_ 391 ACMode_Selection 300;
BA_REL_ "GenSigFirstTimeoutTime" BU_SG_REL_ IC SG_ 391 EngineOilTempHigh 3000;
BA_REL_ "GenSigTimeoutTime" BU_SG_REL_ IC SG_ 391 EngineOilTempHigh 300;
BA_REL_ "GenSigFirstTimeoutTime" BU_SG_REL_ IC SG_ 391 StartupProhibitStatus 3000;
BA_REL_ "GenSigTimeoutTime" BU_SG_REL_ IC SG_ 391 StartupProhibitStatus 300;
BA_REL_ "GenSigFirstTimeoutTime" BU_SG_REL_ IC SG_ 391 AuxBrakesDwngrdModeInd_rqst 3000;
BA_REL_ "GenSigTimeoutTime" BU_SG_REL_ IC SG_ 391 AuxBrakesDwngrdModeInd_rqst 300;
BA_REL_ "GenSigFirstTimeoutTime" BU_SG_REL_ CCM SG_ 391 ElectricalLoadReduction_rqst 3000;
BA_REL_ "GenSigTimeoutTime" BU_SG_REL_ CCM SG_ 391 ElectricalLoadReduction_rqst 300;
BA_REL_ "GenSigFirstTimeoutTime" BU_SG_REL_ IC SG_ 391 ACmode_Status 3000;
BA_REL_ "GenSigTimeoutTime" BU_SG_REL_ IC SG_ 391 ACmode_Status 300;
BA_REL_ "GenSigFirstTimeoutTime" BU_SG_REL_ IC SG_ 391 LoadDistributionChangeACK 3000;
BA_REL_ "GenSigTimeoutTime" BU_SG_REL_ IC SG_ 391 LoadDistributionChangeACK 300;
BA_REL_ "GenSigFirstTimeoutTime" BU_SG_REL_ IC SG_ 391 FerryFunctionStatus 3000;
BA_REL_ "GenSigTimeoutTime" BU_SG_REL_ IC SG_ 391 FerryFunctionStatus 300;
BA_REL_ "GenSigFirstTimeoutTime" BU_SG_REL_ IC SG_ 391 ClutchOverloadStatus 3000;
BA_REL_ "GenSigTimeoutTime" BU_SG_REL_ IC SG_ 391 ClutchOverloadStatus 300;
BA_REL_ "GenSigFirstTimeoutTime" BU_SG_REL_ CCM SG_ 391 AutoBlowerLevel_Selection 3000;
BA_REL_ "GenSigTimeoutTime" BU_SG_REL_ CCM SG_ 391 AutoBlowerLevel_Selection 300;
BA_REL_ "GenSigFirstTimeoutTime" BU_SG_REL_ IC SG_ 391 RollerBenchModeStatus 3000;
BA_REL_ "GenSigTimeoutTime" BU_SG_REL_ IC SG_ 391 RollerBenchModeStatus 300;
BA_REL_ "GenSigFirstTimeoutTime" BU_SG_REL_ IC SG_ 391 LoadDistributionALDChangeACK 3000;
BA_REL_ "GenSigTimeoutTime" BU_SG_REL_ IC SG_ 391 LoadDistributionALDChangeACK 300;
BA_REL_ "GenSigFirstTimeoutTime" BU_SG_REL_ IC SG_ 391 EngineSpeedControlStatus 3000;
BA_REL_ "GenSigTimeoutTime" BU_SG_REL_ IC SG_ 391 EngineSpeedControlStatus 300;
BA_REL_ "GenSigFirstTimeoutTime" BU_SG_REL_ IC SG_ 391 AutoBlowerLevel_Status 3000;
BA_REL_ "GenSigTimeoutTime" BU_SG_REL_ IC SG_ 391 AutoBlowerLevel_Status 300;
BA_REL_ "GenSigFirstTimeoutTime" BU_SG_REL_ IC SG_ 391 DTCActive 3000;
BA_REL_ "GenSigTimeoutTime" BU_SG_REL_ IC SG_ 391 DTCActive 300;
BA_REL_ "GenSigFirstTimeoutTime" BU_SG_REL_ IC SG_ 390 PS_SevereEngAndBrkOverspdWarn 3000;
BA_REL_ "GenSigTimeoutTime" BU_SG_REL_ IC SG_ 390 PS_SevereEngAndBrkOverspdWarn 300;
BA_REL_ "GenSigFirstTimeoutTime" BU_SG_REL_ SCIM SG_ 390 RearFog_Indication 3000;
BA_REL_ "GenSigTimeoutTime" BU_SG_REL_ SCIM SG_ 390 RearFog_Indication 300;
BA_REL_ "GenSigFirstTimeoutTime" BU_SG_REL_ IC SG_ 390 SasAdaptationInProgress 3000;
BA_REL_ "GenSigTimeoutTime" BU_SG_REL_ IC SG_ 390 SasAdaptationInProgress 300;
BA_REL_ "GenSigFirstTimeoutTime" BU_SG_REL_ IC SG_ 390 SplitBoxDifflockActvnDrvrRqst 3000;
BA_REL_ "GenSigTimeoutTime" BU_SG_REL_ IC SG_ 390 SplitBoxDifflockActvnDrvrRqst 300;
BA_REL_ "GenSigFirstTimeoutTime" BU_SG_REL_ IC SG_ 390 EcoRollActiveStatus 3000;
BA_REL_ "GenSigTimeoutTime" BU_SG_REL_ IC SG_ 390 EcoRollActiveStatus 300;
BA_REL_ "GenSigFirstTimeoutTime" BU_SG_REL_ IC SG_ 390 PloughLampModeStatus 3000;
BA_REL_ "GenSigTimeoutTime" BU_SG_REL_ IC SG_ 390 PloughLampModeStatus 300;
BA_REL_ "GenSigFirstTimeoutTime" BU_SG_REL_ IC SG_ 390 RrRrItrWhlDiffLckActvnDrvrReq 3000;
BA_REL_ "GenSigTimeoutTime" BU_SG_REL_ IC SG_ 390 RrRrItrWhlDiffLckActvnDrvrReq 300;
BA_REL_ "GenSigFirstTimeoutTime" BU_SG_REL_ CCM SG_ 390 AQSMode_Selection 3000;
BA_REL_ "GenSigTimeoutTime" BU_SG_REL_ CCM SG_ 390 AQSMode_Selection 300;
BA_REL_ "GenSigFirstTimeoutTime" BU_SG_REL_ IC SG_ 390 DrvrRetarderBrakeProgram_rqst 3000;
BA_REL_ "GenSigTimeoutTime" BU_SG_REL_ IC SG_ 390 DrvrRetarderBrakeProgram_rqst 300;
BA_REL_ "GenSigFirstTimeoutTime" BU_SG_REL_ IC SG_ 390 PS_EngOverSpeedSevereWarning 3000;
BA_REL_ "GenSigTimeoutTime" BU_SG_REL_ IC SG_ 390 PS_EngOverSpeedSevereWarning 300;
BA_REL_ "GenSigFirstTimeoutTime" BU_SG_REL_ IC SG_ 390 ParkBrakeReleasePossible_stat 3000;
BA_REL_ "GenSigTimeoutTime" BU_SG_REL_ IC SG_ 390 ParkBrakeReleasePossible_stat 300;
BA_REL_ "GenSigFirstTimeoutTime" BU_SG_REL_ IC SG_ 390 StoreIdleValue 3000;
BA_REL_ "GenSigTimeoutTime" BU_SG_REL_ IC SG_ 390 StoreIdleValue 300;
BA_REL_ "GenSigFirstTimeoutTime" BU_SG_REL_ IC SG_ 390 AutRrAxleDiffLockActvnDrvrReq 3000;
BA_REL_ "GenSigTimeoutTime" BU_SG_REL_ IC SG_ 390 AutRrAxleDiffLockActvnDrvrReq 300;
BA_REL_ "GenSigFirstTimeoutTime" BU_SG_REL_ IC SG_ 390 TransmLowRangeSenseSwitch 3000;
BA_REL_ "GenSigTimeoutTime" BU_SG_REL_ IC SG_ 390 TransmLowRangeSenseSwitch 300;
BA_REL_ "GenSigFirstTimeoutTime" BU_SG_REL_ IC SG_ 390 PBStatusDisplay_cmd 3000;
BA_REL_ "GenSigTimeoutTime" BU_SG_REL_ IC SG_ 390 PBStatusDisplay_cmd 300;
BA_REL_ "GenSigFirstTimeoutTime" BU_SG_REL_ IC SG_ 390 AutoRearAxleDiffLockFnc_stat 3000;
BA_REL_ "GenSigTimeoutTime" BU_SG_REL_ IC SG_ 390 AutoRearAxleDiffLockFnc_stat 300;
BA_REL_ "GenSigFirstTimeoutTime" BU_SG_REL_ IC SG_ 390 PoorBrakePerformanceWarning 3000;
BA_REL_ "GenSigTimeoutTime" BU_SG_REL_ IC SG_ 390 PoorBrakePerformanceWarning 300;
BA_REL_ "GenSigFirstTimeoutTime" BU_SG_REL_ IC SG_ 390 AQSmode_Status 3000;
BA_REL_ "GenSigTimeoutTime" BU_SG_REL_ IC SG_ 390 AQSmode_Status 300;
BA_REL_ "GenSigFirstTimeoutTime" BU_SG_REL_ IC SG_ 390 CCIOM_ParkBrakeAlert 3000;
BA_REL_ "GenSigTimeoutTime" BU_SG_REL_ IC SG_ 390 CCIOM_ParkBrakeAlert 300;
BA_REL_ "GenSigFirstTimeoutTime" BU_SG_REL_ IC SG_ 390 FrontParkBrakeOverrideInd 3000;
BA_REL_ "GenSigTimeoutTime" BU_SG_REL_ IC SG_ 390 FrontParkBrakeOverrideInd 300;
BA_REL_ "GenSigFirstTimeoutTime" BU_SG_REL_ IC SG_ 390 ProhibitControlStatus 3000;
BA_REL_ "GenSigTimeoutTime" BU_SG_REL_ IC SG_ 390 ProhibitControlStatus 300;
BA_REL_ "GenSigFirstTimeoutTime" BU_SG_REL_ IC SG_ 390 PositionLightRequest_status 3000;
BA_REL_ "GenSigTimeoutTime" BU_SG_REL_ IC SG_ 390 PositionLightRequest_status 300;
BA_REL_ "GenSigFirstTimeoutTime" BU_SG_REL_ IC SG_ 390 DoubleFrontAxleSteeringWarning 3000;
BA_REL_ "GenSigTimeoutTime" BU_SG_REL_ IC SG_ 390 DoubleFrontAxleSteeringWarning 300;
BA_REL_ "GenSigFirstTimeoutTime" BU_SG_REL_ IC SG_ 390 TrailerABSStatus 3000;
BA_REL_ "GenSigTimeoutTime" BU_SG_REL_ IC SG_ 390 TrailerABSStatus 300;
BA_REL_ "GenSigFirstTimeoutTime" BU_SG_REL_ IC SG_ 390 LoadCutOffIndication_cmd 3000;
BA_REL_ "GenSigTimeoutTime" BU_SG_REL_ IC SG_ 390 LoadCutOffIndication_cmd 300;
BA_REL_ "GenSigFirstTimeoutTime" BU_SG_REL_ CCM SG_ 390 PtosStatus 3000;
BA_REL_ "GenSigTimeoutTime" BU_SG_REL_ CCM SG_ 390 PtosStatus 300;
BA_REL_ "GenSigFirstTimeoutTime" BU_SG_REL_ IC SG_ 390 REM_PhoneButtonInd_cmd 3000;
BA_REL_ "GenSigTimeoutTime" BU_SG_REL_ IC SG_ 390 REM_PhoneButtonInd_cmd 300;
BA_REL_ "GenSigFirstTimeoutTime" BU_SG_REL_ IC SG_ 390 TrailerBrake_Stat 3000;
BA_REL_ "GenSigTimeoutTime" BU_SG_REL_ IC SG_ 390 TrailerBrake_Stat 300;
BA_REL_ "GenSigFirstTimeoutTime" BU_SG_REL_ IC SG_ 390 SEM2_PhoneButtonInd_cmd 3000;
BA_REL_ "GenSigTimeoutTime" BU_SG_REL_ IC SG_ 390 SEM2_PhoneButtonInd_cmd 300;
BA_REL_ "GenSigFirstTimeoutTime" BU_SG_REL_ IC SG_ 390 GearRangeUnengaged 3000;
BA_REL_ "GenSigTimeoutTime" BU_SG_REL_ IC SG_ 390 GearRangeUnengaged 300;
BA_REL_ "GenSigFirstTimeoutTime" BU_SG_REL_ IC SG_ 390 ABSOffRoadStatus 3000;
BA_REL_ "GenSigTimeoutTime" BU_SG_REL_ IC SG_ 390 ABSOffRoadStatus 300;
BA_REL_ "GenSigFirstTimeoutTime" BU_SG_REL_ IC SG_ 390 DrvrRetarderBrakeBlending_rqst 3000;
BA_REL_ "GenSigTimeoutTime" BU_SG_REL_ IC SG_ 390 DrvrRetarderBrakeBlending_rqst 300;
BA_REL_ "GenSigFirstTimeoutTime" BU_SG_REL_ IC SG_ 389 XPRGSystemCap_Priority 3000;
BA_REL_ "GenSigTimeoutTime" BU_SG_REL_ IC SG_ 389 XPRGSystemCap_Priority 300;
BA_REL_ "GenSigFirstTimeoutTime" BU_SG_REL_ IC SG_ 389 XPRGSystemCap_AllowedRelInhibit 3000;
BA_REL_ "GenSigTimeoutTime" BU_SG_REL_ IC SG_ 389 XPRGSystemCap_AllowedRelInhibit 300;
BA_REL_ "GenSigFirstTimeoutTime" BU_SG_REL_ CCM SG_ 389 PHTimerRqstAck_Minutes 3000;
BA_REL_ "GenSigTimeoutTime" BU_SG_REL_ CCM SG_ 389 PHTimerRqstAck_Minutes 300;
BA_REL_ "GenSigFirstTimeoutTime" BU_SG_REL_ IC SG_ 389 RearAxleDiffLockActvnDrvrReq 3000;
BA_REL_ "GenSigTimeoutTime" BU_SG_REL_ IC SG_ 389 RearAxleDiffLockActvnDrvrReq 300;
BA_REL_ "GenSigFirstTimeoutTime" BU_SG_REL_ IC SG_ 389 FrRrItrWhlDiffLckActvnDrvrReq 3000;
BA_REL_ "GenSigTimeoutTime" BU_SG_REL_ IC SG_ 389 FrRrItrWhlDiffLckActvnDrvrReq 300;
BA_REL_ "GenSigFirstTimeoutTime" BU_SG_REL_ IC SG_ 389 XPRGSystemCap_AllowedGradCtrlTc 3000;
BA_REL_ "GenSigTimeoutTime" BU_SG_REL_ IC SG_ 389 XPRGSystemCap_AllowedGradCtrlTc 300;
BA_REL_ "GenSigFirstTimeoutTime" BU_SG_REL_ IC SG_ 389 XPRGSystemCap_AllowedGradCtrlTl 3000;
BA_REL_ "GenSigTimeoutTime" BU_SG_REL_ IC SG_ 389 XPRGSystemCap_AllowedGradCtrlTl 300;
BA_REL_ "GenSigFirstTimeoutTime" BU_SG_REL_ IC SG_ 389 RegenInhibDueHeight 3000;
BA_REL_ "GenSigTimeoutTime" BU_SG_REL_ IC SG_ 389 RegenInhibDueHeight 300;
BA_REL_ "GenSigFirstTimeoutTime" BU_SG_REL_ CCM SG_ 389 PHTimerRqstAck_Hours 3000;
BA_REL_ "GenSigTimeoutTime" BU_SG_REL_ CCM SG_ 389 PHTimerRqstAck_Hours 300;
BA_REL_ "GenSigFirstTimeoutTime" BU_SG_REL_ IC SG_ 389 PoorAirPressureInfo 3000;
BA_REL_ "GenSigTimeoutTime" BU_SG_REL_ IC SG_ 389 PoorAirPressureInfo 300;
BA_REL_ "GenSigFirstTimeoutTime" BU_SG_REL_ IC SG_ 389 XPRGSystemCap_AllowedPBApp 3000;
BA_REL_ "GenSigTimeoutTime" BU_SG_REL_ IC SG_ 389 XPRGSystemCap_AllowedPBApp 300;
BA_REL_ "GenSigFirstTimeoutTime" BU_SG_REL_ IC SG_ 389 XRSLControllerMode 3000;
BA_REL_ "GenSigTimeoutTime" BU_SG_REL_ IC SG_ 389 XRSLControllerMode 300;
BA_REL_ "GenSigFirstTimeoutTime" BU_SG_REL_ IC SG_ 389 XPRGSystemCap_CRC 3000;
BA_REL_ "GenSigTimeoutTime" BU_SG_REL_ IC SG_ 389 XPRGSystemCap_CRC 300;
BA_REL_ "GenSigFirstTimeoutTime" BU_SG_REL_ IC SG_ 389 XPRGSystemCap_AllowedInflation 3000;
BA_REL_ "GenSigTimeoutTime" BU_SG_REL_ IC SG_ 389 XPRGSystemCap_AllowedInflation 300;
BA_REL_ "GenSigFirstTimeoutTime" BU_SG_REL_ IC SG_ 389 XPRGSystemCap_SqC 3000;
BA_REL_ "GenSigTimeoutTime" BU_SG_REL_ IC SG_ 389 XPRGSystemCap_SqC 300;
BA_REL_ "GenSigFirstTimeoutTime" BU_SG_REL_ CCM SG_ 389 PHTimerRqstAck_DayOfWeekRq 3000;
BA_REL_ "GenSigTimeoutTime" BU_SG_REL_ CCM SG_ 389 PHTimerRqstAck_DayOfWeekRq 300;
BA_REL_ "GenSigFirstTimeoutTime" BU_SG_REL_ IC SG_ 389 VIN_rqst 3000;
BA_REL_ "GenSigTimeoutTime" BU_SG_REL_ IC SG_ 389 VIN_rqst 300;
BA_REL_ "GenSigFirstTimeoutTime" BU_SG_REL_ CCM SG_ 389 PHTimerRqstAck_CurrentOp 3000;
BA_REL_ "GenSigTimeoutTime" BU_SG_REL_ CCM SG_ 389 PHTimerRqstAck_CurrentOp 300;
BA_REL_ "GenSigFirstTimeoutTime" BU_SG_REL_ IC SG_ 389 PS_EngineBrakeOverSpeedWarning 3000;
BA_REL_ "GenSigTimeoutTime" BU_SG_REL_ IC SG_ 389 PS_EngineBrakeOverSpeedWarning 300;
BA_REL_ "GenSigFirstTimeoutTime" BU_SG_REL_ IC SG_ 389 XPRGSystemCap_AllowedDeflation 3000;
BA_REL_ "GenSigTimeoutTime" BU_SG_REL_ IC SG_ 389 XPRGSystemCap_AllowedDeflation 300;
BA_REL_ "GenSigFirstTimeoutTime" BU_SG_REL_ IC SG_ 389 XPRGSystemCap_AllowedInfInhibit 3000;
BA_REL_ "GenSigTimeoutTime" BU_SG_REL_ IC SG_ 389 XPRGSystemCap_AllowedInfInhibit 300;
BA_REL_ "GenSigFirstTimeoutTime" BU_SG_REL_ IC SG_ 389 TrcnCtrlSlipperyRoadWarning 3000;
BA_REL_ "GenSigTimeoutTime" BU_SG_REL_ IC SG_ 389 TrcnCtrlSlipperyRoadWarning 300;
BA_REL_ "GenSigFirstTimeoutTime" BU_SG_REL_ IC SG_ 389 XPRGSystemCap_AllowedPBRel 3000;
BA_REL_ "GenSigTimeoutTime" BU_SG_REL_ IC SG_ 389 XPRGSystemCap_AllowedPBRel 300;
BA_REL_ "GenSigFirstTimeoutTime" BU_SG_REL_ IC SG_ 389 TransmissionAirPressureLow 3000;
BA_REL_ "GenSigTimeoutTime" BU_SG_REL_ IC SG_ 389 TransmissionAirPressureLow 300;
BA_REL_ "GenSigFirstTimeoutTime" BU_SG_REL_ IC SG_ 158 SecuredNeutralPosition 3000;
BA_REL_ "GenSigTimeoutTime" BU_SG_REL_ IC SG_ 158 SecuredNeutralPosition 120;
BA_REL_ "GenSigFirstTimeoutTime" BU_SG_REL_ IC SG_ 158 MirrorSelectLeftWideBtn_stat 3000;
BA_REL_ "GenSigTimeoutTime" BU_SG_REL_ IC SG_ 158 MirrorSelectLeftWideBtn_stat 120;
BA_REL_ "GenSigFirstTimeoutTime" BU_SG_REL_ IC SG_ 158 Recirc_ButtonStatus 3000;
BA_REL_ "GenSigTimeoutTime" BU_SG_REL_ IC SG_ 158 Recirc_ButtonStatus 120;
BA_REL_ "GenSigFirstTimeoutTime" BU_SG_REL_ IC SG_ 158 AirFlowSelectionUpBtn_stat 3000;
BA_REL_ "GenSigTimeoutTime" BU_SG_REL_ IC SG_ 158 AirFlowSelectionUpBtn_stat 120;
BA_REL_ "GenSigFirstTimeoutTime" BU_SG_REL_ IC SG_ 158 BunkH1AudioOnOff_ButtonStatus 3000;
BA_REL_ "GenSigTimeoutTime" BU_SG_REL_ IC SG_ 158 BunkH1AudioOnOff_ButtonStatus 120;
BA_REL_ "GenSigFirstTimeoutTime" BU_SG_REL_ IC SG_ 158 AC_ButtonStatus 3000;
BA_REL_ "GenSigTimeoutTime" BU_SG_REL_ IC SG_ 158 AC_ButtonStatus 120;
BA_REL_ "GenSigFirstTimeoutTime" BU_SG_REL_ IC SG_ 158 OverSteerGuidanceStatus 3000;
BA_REL_ "GenSigTimeoutTime" BU_SG_REL_ IC SG_ 158 OverSteerGuidanceStatus 120;
BA_REL_ "GenSigFirstTimeoutTime" BU_SG_REL_ IC SG_ 158 MirrorSelectLeftMainBtn_stat 3000;
BA_REL_ "GenSigTimeoutTime" BU_SG_REL_ IC SG_ 158 MirrorSelectLeftMainBtn_stat 120;
BA_REL_ "GenSigFirstTimeoutTime" BU_SG_REL_ IC SG_ 158 LECM_CabClim_Auto_BtnStat 3000;
BA_REL_ "GenSigTimeoutTime" BU_SG_REL_ IC SG_ 158 LECM_CabClim_Auto_BtnStat 120;
BA_REL_ "GenSigFirstTimeoutTime" BU_SG_REL_ IC SG_ 158 ParkBrakeAlert 3000;
BA_REL_ "GenSigTimeoutTime" BU_SG_REL_ IC SG_ 158 ParkBrakeAlert 120;
BA_REL_ "GenSigFirstTimeoutTime" BU_SG_REL_ IC SG_ 158 LECM_Display_Navi_OK_BtnStat 3000;
BA_REL_ "GenSigTimeoutTime" BU_SG_REL_ IC SG_ 158 LECM_Display_Navi_OK_BtnStat 120;
BA_REL_ "GenSigFirstTimeoutTime" BU_SG_REL_ IC SG_ 158 LECM_CabClim_AC_BtnStat 3000;
BA_REL_ "GenSigTimeoutTime" BU_SG_REL_ IC SG_ 158 LECM_CabClim_AC_BtnStat 120;
BA_REL_ "GenSigFirstTimeoutTime" BU_SG_REL_ IC SG_ 158 LECMCabClimSetTempSelectGuiReq 3000;
BA_REL_ "GenSigTimeoutTime" BU_SG_REL_ IC SG_ 158 LECMCabClimSetTempSelectGuiReq 120;
BA_REL_ "GenSigFirstTimeoutTime" BU_SG_REL_ IC SG_ 158 MirrorSelectRightMainBtn_stat 3000;
BA_REL_ "GenSigTimeoutTime" BU_SG_REL_ IC SG_ 158 MirrorSelectRightMainBtn_stat 120;
BA_REL_ "GenSigFirstTimeoutTime" BU_SG_REL_ SCIM SG_ 158 DaytimeRunningLight_Indication 3000;
BA_REL_ "GenSigTimeoutTime" BU_SG_REL_ SCIM SG_ 158 DaytimeRunningLight_Indication 120;
BA_REL_ "GenSigFirstTimeoutTime" BU_SG_REL_ SCIM SG_ 158 DrivingLight_Indication 3000;
BA_REL_ "GenSigTimeoutTime" BU_SG_REL_ SCIM SG_ 158 DrivingLight_Indication 120;
BA_REL_ "GenSigFirstTimeoutTime" BU_SG_REL_ SCIM SG_ 158 FrontFog_Indication 3000;
BA_REL_ "GenSigTimeoutTime" BU_SG_REL_ SCIM SG_ 158 FrontFog_Indication 120;
BA_REL_ "GenSigFirstTimeoutTime" BU_SG_REL_ IC SG_ 158 Auto_ButtonStatus 3000;
BA_REL_ "GenSigTimeoutTime" BU_SG_REL_ IC SG_ 158 Auto_ButtonStatus 120;
BA_REL_ "GenSigFirstTimeoutTime" BU_SG_REL_ IC SG_ 158 KeyfobPreTripButtonStatus 3000;
BA_REL_ "GenSigTimeoutTime" BU_SG_REL_ IC SG_ 158 KeyfobPreTripButtonStatus 120;
BA_REL_ "GenSigFirstTimeoutTime" BU_SG_REL_ IC SG_ 158 MirrorSelectRightWideBtn_stat 3000;
BA_REL_ "GenSigTimeoutTime" BU_SG_REL_ IC SG_ 158 MirrorSelectRightWideBtn_stat 120;
BA_REL_ "GenSigFirstTimeoutTime" BU_SG_REL_ SCIM SG_ 158 ParkingLight_Indication 3000;
BA_REL_ "GenSigTimeoutTime" BU_SG_REL_ SCIM SG_ 158 ParkingLight_Indication 120;
BA_REL_ "GenSigFirstTimeoutTime" BU_SG_REL_ SCIM SG_ 158 DrivingLightPlus_Indication 3000;
BA_REL_ "GenSigTimeoutTime" BU_SG_REL_ SCIM SG_ 158 DrivingLightPlus_Indication 120;
BA_REL_ "GenSigFirstTimeoutTime" BU_SG_REL_ IC SG_ 158 BlackPanelMode_ButtonStatus 3000;
BA_REL_ "GenSigTimeoutTime" BU_SG_REL_ IC SG_ 158 BlackPanelMode_ButtonStatus 120;
BA_REL_ "GenSigFirstTimeoutTime" BU_SG_REL_ IC SG_ 158 ParkHeaterCooler_ButtonStatus 3000;
BA_REL_ "GenSigTimeoutTime" BU_SG_REL_ IC SG_ 158 ParkHeaterCooler_ButtonStatus 120;
BA_REL_ "GenSigFirstTimeoutTime" BU_SG_REL_ IC SG_ 158 LECM_CabClim_FrPwr_BtnStat 3000;
BA_REL_ "GenSigTimeoutTime" BU_SG_REL_ IC SG_ 158 LECM_CabClim_FrPwr_BtnStat 120;
BA_REL_ "GenSigFirstTimeoutTime" BU_SG_REL_ IC SG_ 158 LECM_CabClim_Pwr_BtnStat 3000;
BA_REL_ "GenSigTimeoutTime" BU_SG_REL_ IC SG_ 158 LECM_CabClim_Pwr_BtnStat 120;
BA_REL_ "GenSigFirstTimeoutTime" BU_SG_REL_ IC SG_ 158 AirFlowSelectionFrontBtn_stat 3000;
BA_REL_ "GenSigTimeoutTime" BU_SG_REL_ IC SG_ 158 AirFlowSelectionFrontBtn_stat 120;
BA_REL_ "GenSigFirstTimeoutTime" BU_SG_REL_ IC SG_ 158 BlackPanelMode_ButtonStatus3 3000;
BA_REL_ "GenSigTimeoutTime" BU_SG_REL_ IC SG_ 158 BlackPanelMode_ButtonStatus3 120;
BA_REL_ "GenSigFirstTimeoutTime" BU_SG_REL_ IC SG_ 158 LECM_CabClim_Sync_GuiReq 3000;
BA_REL_ "GenSigTimeoutTime" BU_SG_REL_ IC SG_ 158 LECM_CabClim_Sync_GuiReq 120;
BA_REL_ "GenSigFirstTimeoutTime" BU_SG_REL_ IC SG_ 158 LiftAxle1AutoLiftSelected 3000;
BA_REL_ "GenSigTimeoutTime" BU_SG_REL_ IC SG_ 158 LiftAxle1AutoLiftSelected 120;
BA_REL_ "GenSigFirstTimeoutTime" BU_SG_REL_ IC SG_ 158 LECM_Ent_OnOff_BtnStat 3000;
BA_REL_ "GenSigTimeoutTime" BU_SG_REL_ IC SG_ 158 LECM_Ent_OnOff_BtnStat 120;
VAL_ 691 DirectionIndicatorLightsStatus 15 "DirectionIndicatorLightsStatus_NotAvailable" 14 "DirectionIndicatorLightsStatus_Error" 13 "DirectionIndicatorLightsStatus_Spare7" 12 "DirectionIndicatorLightsStatus_Spare6" 11 "DirectionIndicatorLightsStatus_Spare5" 10 "DirectionIndicatorLightsStatus_Spare4" 9 "DirectionIndicatorLightsStatus_Spare3" 8 "DirectionIndicatorLightsStatus_Spare2" 7 "DirectionIndicatorLightsStatus_Spare1" 6 "DirectionIndicatorLightsStatus_ActiveOtherIndication" 5 "DirectionIndicatorLightsStatus_ActiveHazard" 4 "DirectionIndicatorLightsStatus_ActiveRightAndHazard" 3 "DirectionIndicatorLightsStatus_ActiveLeftAndHazard" 2 "DirectionIndicatorLightsStatus_ActiveRight" 1 "DirectionIndicatorLightsStatus_ActiveLeft" 0 "DirectionIndicatorLightsStatus_NotActive" ;
VAL_ 691 APM_ParkBrakeApplicationMode2 15 "ParkBrakeApplicationMode2_NotAvailable" 14 "ParkBrakeApplicationMode2_Error" 13 "ParkBrakeApplicationMode2_Reserved5" 12 "ParkBrakeApplicationMode2_Reserved4" 11 "ParkBrakeApplicationMode2_Reserved3" 10 "ParkBrakeApplicationMode2_Reserved2" 9 "ParkBrakeApplicationMode2_RedundantExternalDemand" 8 "ParkBrakeApplicationMode2_AutomaticcallyDoorOpen" 7 "ParkBrakeApplicationMode2_ParkBrakeBlending" 6 "ParkBrakeApplicationMode2_AutomaticallyHillHolder" 5 "ParkBrakeApplicationMode2_AutomaticInBackup" 4 "ParkBrakeApplicationMode2_MainExternalDemand" 3 "ParkBrakeApplicationMode2_AutomaticallyKeyOff" 2 "ParkBrakeApplicationMode2_ManuallyAtStandstill" 1 "ParkBrakeApplicationMode2_ManuallyInDriving" 0 "ParkBrakeApplicationMode2_Idle" ;
VAL_ 691 ACC_SGO_Status 15 "ACC_SGO_Status_NotAvailable" 14 "ACC_SGO_Status_Error" 13 "ACC_SGO_Status_Spare7" 12 "ACC_SGO_Status_Spare6" 11 "ACC_SGO_Status_Spare5" 10 "ACC_SGO_Status_Spare4" 9 "ACC_SGO_Status_Spare3" 8 "ACC_SGO_Status_Spare2" 7 "ACC_SGO_Status_Spare1" 6 "ACC_SGO_Status_ACC_SGO_Active_TakeOffRequest" 5 "ACC_SGO_Status_ACC_SGO_Active_Hold" 4 "ACC_SGO_Status_ACC_SGO_Active_Stationary" 3 "ACC_SGO_Status_ACC_SGO_Stopping" 2 "ACC_SGO_Status_ACC_SGO_Active_Driving" 1 "ACC_SGO_Status_ACC_SGO_Inactive" 0 "ACC_SGO_Status_ACC_SGO_OFF" ;
VAL_ 690 SetHSAOperation 7 "SetHSAOperation_NotAvailable" 6 "SetHSAOperation_Error" 5 "SetHSAOperation_Spare2" 4 "SetHSAOperation_Spare1" 3 "SetHSAOperation_Forbid_HSA_WithCaution" 2 "SetHSAOperation_Forbid_HSA_Activation" 1 "SetHSAOperation_Allow_HSA_WithCaution" 0 "SetHSAOperation_Allow_HSA_Activation" ;
VAL_ 690 PS_FogLightFront 3 "InactiveActiveSpare_NotAvailable" 2 "InactiveActiveSpare_Spare" 1 "InactiveActiveSpare_Active" 0 "InactiveActiveSpare_Inactive" ;
VAL_ 690 CACCStatus 7 "CACCStatus_NotAvailable" 6 "CACCStatus_Error" 5 "CACCStatus_Spare3" 4 "CACCStatus_Spare2" 3 "CACCStatus_Spare1" 2 "CACCStatus_Active" 1 "CACCStatus_Available" 0 "CACCStatus_Unavailable" ;
VAL_ 690 Cab12VSupplyStatus 3 "Cab12VSupplyStatus_NotAvailable" 2 "Cab12VSupplyStatus_Error" 1 "Cab12VSupplyStatus_CabSupplyError" 0 "Cab12VSupplyStatus_OK" ;
VAL_ 690 TransmissionDrivingMode 7 "TransmissionDrivingMode_NotAvailable" 6 "TransmissionDrivingMode_KickDown" 5 "TransmissionDrivingMode_Dynamometer" 4 "TransmissionDrivingMode_HeavyDuty" 3 "TransmissionDrivingMode_OffRoad" 2 "TransmissionDrivingMode_Performance" 1 "TransmissionDrivingMode_Balanced_Standard" 0 "TransmissionDrivingMode_EconomyExtra_Range" ;
VAL_ 690 LowAirPressureAlert 3 "LowAirPressureAlert_NotAvailable" 2 "LowAirPressureAlert_Error" 1 "LowAirPressureAlert_LowPressure" 0 "LowAirPressureAlert_NormalPressure" ;
VAL_ 690 TemporaryRSLSwitchStatus 3 "A2PosSwitchStatus_NotAvailable" 2 "A2PosSwitchStatus_Error" 1 "A2PosSwitchStatus_On" 0 "A2PosSwitchStatus_Off" ;
VAL_ 690 BatterySOCAlertRawData_rqst 7 "BatterySOCAlert_rqst_NotAvailable" 6 "BatterySOCAlert_rqst_ErrorIndicator" 5 "BatterySOCAlert_rqst_SpareValue_02" 4 "BatterySOCAlert_rqst_SpareValue_01" 3 "BatterySOCAlert_rqst_SpareValue" 2 "BatterySOCAlert_rqst_CriticalAlert" 1 "BatterySOCAlert_rqst_PreAlert" 0 "BatterySOCAlert_rqst_NoAlertRequested" ;
VAL_ 690 BatteryTempAlertRawData_rqst 7 "BatteryTempAlert_rqst_NotAvailable" 6 "BatteryTempAlert_rqst_Error" 5 "BatteryTempAlert_rqst_Spare3" 4 "BatteryTempAlert_rqst_Spare2" 3 "BatteryTempAlert_rqst_Spare1" 2 "BatteryTempAlert_rqst_CriticalAlertLowTemp" 1 "BatteryTempAlert_rqst_PreAlertLowTemp" 0 "BatteryTempAlert_rqst_NoAlertRequested" ;
VAL_ 690 BrakeTemperatureWarning 3 "Warning_NotAvailable" 2 "Warning_Error" 1 "Warning_Warning" 0 "Warning_NoWarning" ;
VAL_ 690 WheelSlipControllerMode 7 "WheelSlipCntrlMode_NotAvailable" 6 "WheelSlipCntrlMode_Error" 5 "WheelSlipCntrlMode_Spare2" 4 "WheelSlipCntrlMode_Spare1" 3 "WheelSlipCntrlMode_Disabled" 2 "WheelSlipCntrlMode_EnabledActiveBrakingSlipCntrl" 1 "WheelSlipCntrlMode_EnabledActiveTractionSlipCntrl" 0 "WheelSlipCntrlMode_EnabledPassive" ;
VAL_ 690 Rainsensor_Indication 3 "DeviceIndication_SpareValue" 2 "DeviceIndication_Blink" 1 "DeviceIndication_On" 0 "DeviceIndication_Off" ;
VAL_ 690 ESCHealthStatus 3 "OffOnSpare_NotAvailable" 2 "OffOnSpare_Spare" 1 "OffOnSpare_On" 0 "OffOnSpare_Off" ;
VAL_ 690 TLInflationAcceptance_stat 7 "TLInflationAccept_stat_NotAvailable" 6 "TLInflationAccept_stat_Error" 5 "TLInflationAccept_stat_Spare4" 4 "TLInflationAccept_stat_Spare3" 3 "TLInflationAccept_stat_Spare2" 2 "TLInflationAccept_stat_TrailerInflationAccepted" 1 "TLInflationAccept_stat_BrakePedalRequested" 0 "TLInflationAccept_stat_NoRequestDetectedOrRequestAborted" ;
VAL_ 690 AutoLoadCutOffState 7 "AutoLoadCutOffState_NotAvailable" 6 "AutoLoadCutOffState_Error" 5 "AutoLoadCutOffState_Spare4" 4 "AutoLoadCutOffState_Spare3" 3 "AutoLoadCutOffState_Spare2" 2 "AutoLoadCutOffState_Spare1" 1 "AutoLoadCutOffState_RequestON" 0 "AutoLoadCutOffState_NoRequest" ;
VAL_ 690 TransmissionOilTempHigh 7 "TransmissionOilTempHigh_NotAvailable" 6 "TransmissionOilTempHigh_ErrorIndicator" 5 "TransmissionOilTempHigh_SpareValue_02" 4 "TransmissionOilTempHigh_SpareValue_01" 3 "TransmissionOilTempHigh_SpareValue" 2 "TransmissionOilTempHigh_ActiveVeryHighTemp" 1 "TransmissionOilTempHigh_ActiveHighTemp" 0 "TransmissionOilTempHigh_Inactive" ;
VAL_ 690 ECSLimpHomeNotification 7 "ECSLimpHomeNotification_NotAvailable" 6 "ECSLimpHomeNotification_Error" 5 "ECSLimpHomeNotification_LimpHomeMode5" 4 "ECSLimpHomeNotification_LimpHomeMode4" 3 "ECSLimpHomeNotification_LimpHomeMode3" 2 "ECSLimpHomeNotification_LimpHomeMode2" 1 "ECSLimpHomeNotification_LimpHomeMode1" 0 "ECSLimpHomeNotification_NoLimpHomeMode" ;
VAL_ 690 EqualizerUnbalance 7 "NoWarning3bit_NotAvailable" 6 "NoWarning3bit_Error" 5 "NoWarning3bit_Spare4" 4 "NoWarning3bit_Spare3" 3 "NoWarning3bit_Spare2" 2 "NoWarning3bit_Spare1" 1 "NoWarning3bit_Warning" 0 "NoWarning3bit_NoWarning" ;
VAL_ 690 AutGearSplitPosition 7 "GearSplitPosition_NotAvailable" 6 "GearSplitPosition_Error" 5 "GearSplitPosition_Spare2" 4 "GearSplitPosition_Spare1" 3 "GearSplitPosition_Crawler" 2 "GearSplitPosition_NoSplit" 1 "GearSplitPosition_HighSplit" 0 "GearSplitPosition_LowSplit" ;
VAL_ 690 BatterySOCAlert_rqst 7 "BatterySOCAlert_rqst_NotAvailable" 6 "BatterySOCAlert_rqst_ErrorIndicator" 5 "BatterySOCAlert_rqst_SpareValue_02" 4 "BatterySOCAlert_rqst_SpareValue_01" 3 "BatterySOCAlert_rqst_SpareValue" 2 "BatterySOCAlert_rqst_CriticalAlert" 1 "BatterySOCAlert_rqst_PreAlert" 0 "BatterySOCAlert_rqst_NoAlertRequested" ;
VAL_ 690 DriveModeSwitchUserOverride 7 "DriveModeSwitchUserOverride_NotAvailable" 6 "DriveModeSwitchUserOverride_Error" 5 "DriveModeSwitchUserOverride_Spare" 4 "DriveModeSwitchUserOverride_OverrideStandard" 3 "DriveModeSwitchUserOverride_RequestRange" 2 "DriveModeSwitchUserOverride_OverridePerformance" 1 "DriveModeSwitchUserOverride_AutoSwitch" 0 "DriveModeSwitchUserOverride_None" ;
VAL_ 690 BatteryTempAlert_rqst 7 "BatteryTempAlert_rqst_NotAvailable" 6 "BatteryTempAlert_rqst_Error" 5 "BatteryTempAlert_rqst_Spare3" 4 "BatteryTempAlert_rqst_Spare2" 3 "BatteryTempAlert_rqst_Spare1" 2 "BatteryTempAlert_rqst_CriticalAlertLowTemp" 1 "BatteryTempAlert_rqst_PreAlertLowTemp" 0 "BatteryTempAlert_rqst_NoAlertRequested" ;
VAL_ 690 TrailerEBSFault 3 "OkNok_NotAvailable" 2 "OkNok_Error" 1 "OkNok_NotOK" 0 "OkNok_OK" ;
VAL_ 689 ParkHeaterTimerReleased_stat 3 "DisableEnable_NotAvailable" 2 "DisableEnable_Error" 1 "DisableEnable_Enable" 0 "DisableEnable_Disable" ;
VAL_ 689 Trail2TPMLostCom 3 "NoYes_NotAvailable" 2 "NoYes_Error" 1 "NoYes_Yes" 0 "NoYes_No" ;
VAL_ 689 BrakeInterlockStatus 3 "OffOn_NotAvailable" 2 "OffOn_Error" 1 "OffOn_On" 0 "OffOn_Off" ;
VAL_ 689 AutoWheelBrakesDownshiftSugges 3 "DownshiftSuggest_NotAvailable" 2 "DownshiftSuggest_Error" 1 "DownshiftSuggest_SuggestDownshift" 0 "DownshiftSuggest_NoSuggestion" ;
VAL_ 689 RearAxle2DiffLock_stat 3 "OffOn_NotAvailable" 2 "OffOn_Error" 1 "OffOn_On" 0 "OffOn_Off" ;
VAL_ 689 CentralRearDiffLock_stat 3 "DisengageEngage_NotAvailable" 2 "DisengageEngage_Error" 1 "DisengageEngage_Engage" 0 "DisengageEngage_Disengage" ;
VAL_ 689 TransmissionBrakeMode 3 "InactiveActive_NotAvailable" 2 "InactiveActive_Error" 1 "InactiveActive_Active" 0 "InactiveActive_Inactive" ;
VAL_ 689 PS_HeadLightAdjustment 3 "InactiveActiveSpare_NotAvailable" 2 "InactiveActiveSpare_Spare" 1 "InactiveActiveSpare_Active" 0 "InactiveActiveSpare_Inactive" ;
VAL_ 689 ReducedLoadMode_stat 3 "ReducedLoadMode_stat_NotAvailable" 2 "ReducedLoadMode_stat_Error" 1 "ReducedLoadMode_stat_ReducedLoadMode" 0 "ReducedLoadMode_stat_NormalMode" ;
VAL_ 689 FrontWheelDifflockRequest 3 "DisengageEngage_NotAvailable" 2 "DisengageEngage_Error" 1 "DisengageEngage_Engage" 0 "DisengageEngage_Disengage" ;
VAL_ 689 ABSEBSAmberWarningSignal 3 "OffOn_NotAvailable" 2 "OffOn_Error" 1 "OffOn_On" 0 "OffOn_Off" ;
VAL_ 689 DifferentialLockStateFrAxle1 3 "DisengageEngage_NotAvailable" 2 "DisengageEngage_Error" 1 "DisengageEngage_Engage" 0 "DisengageEngage_Disengage" ;
VAL_ 689 Trail1TPMLostCom 3 "NoYes_NotAvailable" 2 "NoYes_Error" 1 "NoYes_Yes" 0 "NoYes_No" ;
VAL_ 689 TrailerInflationPossible_stat 3 "TrailerInflationPossible_stat_NotAvailable" 2 "TrailerInflationPossible_stat_Error" 1 "TrailerInflationPossible_stat_PossiblePressureOK" 0 "TrailerInflationPossible_stat_NotPossibleLowerPressure" ;
VAL_ 689 DrivelineRetarderStat 3 "DrivelineRetarderStat_NotAvailable" 2 "DrivelineRetarderStat_Error" 1 "DrivelineRetarderStat_RetarderCapacityDerated" 0 "DrivelineRetarderStat_RetarderCapacityNotDerated" ;
VAL_ 689 PS_FogLightRear 3 "InactiveActiveSpare_NotAvailable" 2 "InactiveActiveSpare_Spare" 1 "InactiveActiveSpare_Active" 0 "InactiveActiveSpare_Inactive" ;
VAL_ 689 PS_MainBeam 3 "PSOffOn_NotAvailable" 2 "PSOffOn_Spare" 1 "PSOffOn_On" 0 "PSOffOn_Off" ;
VAL_ 689 DeCompActive 3 "NotActiveActive_NotAvailable" 2 "NotActiveActive_Error" 1 "NotActiveActive_Active" 0 "NotActiveActive_NotActive" ;
VAL_ 689 ECSManStandbyStatus 3 "InactiveActive_NotAvailable" 2 "InactiveActive_Error" 1 "InactiveActive_Active" 0 "InactiveActive_Inactive" ;
VAL_ 689 AutoPBRelease_stat 3 "AutoPBRelease_stat_NotAvailable" 2 "AutoPBRelease_stat_Error" 1 "AutoPBRelease_stat_FunctionInhibited" 0 "AutoPBRelease_stat_FunctionAvailable" ;
VAL_ 689 Trail4TPMLostCom 3 "NoYes_NotAvailable" 2 "NoYes_Error" 1 "NoYes_Yes" 0 "NoYes_No" ;
VAL_ 689 EBSRedWarningSignal 3 "OffOn_NotAvailable" 2 "OffOn_Error" 1 "OffOn_On" 0 "OffOn_Off" ;
VAL_ 689 DifferentialLockStateCentral 3 "DisengageEngage_NotAvailable" 2 "DisengageEngage_Error" 1 "DisengageEngage_Engage" 0 "DisengageEngage_Disengage" ;
VAL_ 689 RearAxle3DiffLock_stat 3 "OffOn_NotAvailable" 2 "OffOn_Error" 1 "OffOn_On" 0 "OffOn_Off" ;
VAL_ 689 AntiLockBrakingActive 3 "AntiLockBrakingActive_NotAvailable" 2 "AntiLockBrakingActive_Reserved" 1 "AntiLockBrakingActive_ABSActive" 0 "AntiLockBrakingActive_ABSPassiveButInstalled" ;
VAL_ 689 RearAxle1DiffLock_stat 3 "OffOn_NotAvailable" 2 "OffOn_Error" 1 "OffOn_On" 0 "OffOn_Off" ;
VAL_ 689 Trail5TPMLostCom 3 "NoYes_NotAvailable" 2 "NoYes_Error" 1 "NoYes_Yes" 0 "NoYes_No" ;
VAL_ 689 PS_PositionLight 3 "OffOnSpare_NotAvailable" 2 "OffOnSpare_Spare" 1 "OffOnSpare_On" 0 "OffOnSpare_Off" ;
VAL_ 689 BatteryCapacity_Ack 3 "NokOk_NotAvailable" 2 "NokOk_Error" 1 "NokOk_OK" 0 "NokOk_NOK" ;
VAL_ 689 Trail3TPMLostCom 3 "NoYes_NotAvailable" 2 "NoYes_Error" 1 "NoYes_Yes" 0 "NoYes_No" ;
VAL_ 689 ParkBrakeWorkshopMode 3 "ParkBrakeWorkshopMode_NotAvailable" 2 "ParkBrakeWorkshopMode_Error" 1 "ParkBrakeWorkshopMode_WorkshopMode" 0 "ParkBrakeWorkshopMode_NormalMode" ;
VAL_ 689 LowTempClutchInfo 3 "Warning_NotAvailable" 2 "Warning_Error" 1 "Warning_Warning" 0 "Warning_NoWarning" ;
VAL_ 688 TrailerWithoutABS 3 "TrailerWithoutABS_NotAvailableOrNotInstalled" 2 "TrailerWithoutABS_ErrorIndicator" 1 "TrailerWithoutABS_YesTrailerWithoutABS" 0 "TrailerWithoutABS_NoNoTrailerPresentOraTrailerWithABS" ;
VAL_ 688 APMSafetyWarning_RedRqst 3 "NotRequested_NotAvailable" 2 "NotRequested_Error" 1 "NotRequested_Requested" 0 "NotRequested_NotRequested" ;
VAL_ 688 EcoRollEnabledStatus 3 "DisableEnable_NotAvailable" 2 "DisableEnable_Error" 1 "DisableEnable_Enable" 0 "DisableEnable_Disable" ;
VAL_ 688 PBStatus_Actuation 7 "PBActuationStatus_NotAvailable" 6 "PBActuationStatus_Error" 5 "PBActuationStatus_Spare3" 4 "PBActuationStatus_Spare2" 3 "PBActuationStatus_Spare1" 2 "PBActuationStatus_Parked" 1 "PBActuationStatus_Intermediate" 0 "PBActuationStatus_Released" ;
VAL_ 688 GearShiftingRec_Steps 7 "GearShiftingSteps_NotAvailable" 6 "GearShiftingSteps_Error" 5 "GearShiftingSteps_6step" 4 "GearShiftingSteps_5step" 3 "GearShiftingSteps_4step" 2 "GearShiftingSteps_3step" 1 "GearShiftingSteps_2step" 0 "GearShiftingSteps_1step" ;
VAL_ 688 PBStatus_IntegrityLvl 3 "PBIntegrityLvl_HighIntegrity" 2 "PBIntegrityLvl_Spare" 1 "PBIntegrityLvl_LowIntegrity" 0 "PBIntegrityLvl_Downgraded" ;
VAL_ 688 GearShiftingRec_Direction 7 "GearShiftingDirection_NotAvailable" 6 "GearShiftingDirection_Error" 5 "GearShiftingDirection_Spare3" 4 "GearShiftingDirection_Spare2" 3 "GearShiftingDirection_Spare1" 2 "GearShiftingDirection_Down" 1 "GearShiftingDirection_Up" 0 "GearShiftingDirection_NoShiftRecommendation" ;
VAL_ 688 APM_TrailerCircPressureStatus 3 "TrailerCircuitPressureStatus_NotAvailable" 2 "TrailerCircuitPressureStatus_Error" 1 "TrailerCircuitPressureStatus_EnabledLowPressureAlert" 0 "TrailerCircuitPressureStatus_DisabledLowPressureAlert" ;
VAL_ 688 RearPropulsionStat_Rear2Axle 15 "AxlePropulsionStatus_NotAvailable" 14 "AxlePropulsionStatus_Error" 13 "AxlePropulsionStatus_Spare6" 12 "AxlePropulsionStatus_Spare5" 11 "AxlePropulsionStatus_Spare4" 10 "AxlePropulsionStatus_Spare3" 9 "AxlePropulsionStatus_Spare2" 8 "AxlePropulsionStatus_Spare1" 7 "AxlePropulsionStatus_LoweredInterAxleStatusUnknown" 6 "AxlePropulsionStatus_LiftedInterAxleStatusUnknown" 5 "AxlePropulsionStatus_PositionUnknownDriven" 4 "AxlePropulsionStatus_PositionUnknownNonDriven" 3 "AxlePropulsionStatus_LoweredDifferentialLocked" 2 "AxlePropulsionStatus_LoweredDriven" 1 "AxlePropulsionStatus_LoweredNonDriven" 0 "AxlePropulsionStatus_LiftedNonDriven" ;
VAL_ 688 RearPropulsionStat_Rear1Axle 15 "AxlePropulsionStatus_NotAvailable" 14 "AxlePropulsionStatus_Error" 13 "AxlePropulsionStatus_Spare6" 12 "AxlePropulsionStatus_Spare5" 11 "AxlePropulsionStatus_Spare4" 10 "AxlePropulsionStatus_Spare3" 9 "AxlePropulsionStatus_Spare2" 8 "AxlePropulsionStatus_Spare1" 7 "AxlePropulsionStatus_LoweredInterAxleStatusUnknown" 6 "AxlePropulsionStatus_LiftedInterAxleStatusUnknown" 5 "AxlePropulsionStatus_PositionUnknownDriven" 4 "AxlePropulsionStatus_PositionUnknownNonDriven" 3 "AxlePropulsionStatus_LoweredDifferentialLocked" 2 "AxlePropulsionStatus_LoweredDriven" 1 "AxlePropulsionStatus_LoweredNonDriven" 0 "AxlePropulsionStatus_LiftedNonDriven" ;
VAL_ 688 RearPropulsionStat_Rear3Axle 15 "AxlePropulsionStatus_NotAvailable" 14 "AxlePropulsionStatus_Error" 13 "AxlePropulsionStatus_Spare6" 12 "AxlePropulsionStatus_Spare5" 11 "AxlePropulsionStatus_Spare4" 10 "AxlePropulsionStatus_Spare3" 9 "AxlePropulsionStatus_Spare2" 8 "AxlePropulsionStatus_Spare1" 7 "AxlePropulsionStatus_LoweredInterAxleStatusUnknown" 6 "AxlePropulsionStatus_LiftedInterAxleStatusUnknown" 5 "AxlePropulsionStatus_PositionUnknownDriven" 4 "AxlePropulsionStatus_PositionUnknownNonDriven" 3 "AxlePropulsionStatus_LoweredDifferentialLocked" 2 "AxlePropulsionStatus_LoweredDriven" 1 "AxlePropulsionStatus_LoweredNonDriven" 0 "AxlePropulsionStatus_LiftedNonDriven" ;
VAL_ 688 APMSafetyWarning_YellowRqst 3 "NoRequestRequest_NotAvailable" 2 "NoRequestRequest_Error" 1 "NoRequestRequest_Request" 0 "NoRequestRequest_NoRequest" ;
VAL_ 393 EngineActiveStatus 15 "EngineActiveStatus_NotAvailable" 14 "EngineActiveStatus_Error" 13 "EngineActiveStatus_Spare_10" 12 "EngineActiveStatus_Spare_09" 11 "EngineActiveStatus_Spare_08" 10 "EngineActiveStatus_Spare_07" 9 "EngineActiveStatus_Spare_06" 8 "EngineActiveStatus_Spare_05" 7 "EngineActiveStatus_Spare_04" 6 "EngineActiveStatus_Spare_03" 5 "EngineActiveStatus_Spare_02" 4 "EngineActiveStatus_Spare_01" 3 "EngineActiveStatus_EngineStandby" 2 "EngineActiveStatus_ElectricPropulsionSystemRunning" 1 "EngineActiveStatus_InternalCombustionEngineRunning" 0 "EngineActiveStatus_DrivelineNotActive" ;
VAL_ 393 BackLightDimming_Status3 31 "Thumbwheel_stat_NotAvaliable" 30 "Thumbwheel_stat_Error" 29 "Thumbwheel_stat_Spare_12" 28 "Thumbwheel_stat_Spare_11" 27 "Thumbwheel_stat_Spare_10" 26 "Thumbwheel_stat_Spare_09" 25 "Thumbwheel_stat_Spare_08" 24 "Thumbwheel_stat_Spare_07" 23 "Thumbwheel_stat_Spare_06" 22 "Thumbwheel_stat_Spare_05" 21 "Thumbwheel_stat_Spare_04" 20 "Thumbwheel_stat_Spare_03" 19 "Thumbwheel_stat_Spare_02" 18 "Thumbwheel_stat_Spare_01" 17 "Thumbwheel_stat_Spare" 16 "Thumbwheel_stat_ThumbWheelPos16" 15 "Thumbwheel_stat_ThumbWheelPos15" 14 "Thumbwheel_stat_ThumbWheelPos14" 13 "Thumbwheel_stat_ThumbWheelPos13" 12 "Thumbwheel_stat_ThumbWheelPos12" 11 "Thumbwheel_stat_ThumbWheelPos11" 10 "Thumbwheel_stat_ThumbWheelPos10" 9 "Thumbwheel_stat_ThumbWheelPos9" 8 "Thumbwheel_stat_ThumbWheelPos8" 7 "Thumbwheel_stat_ThumbWheelPos7" 6 "Thumbwheel_stat_ThumbWheelPos6" 5 "Thumbwheel_stat_ThumbWheelPos5" 4 "Thumbwheel_stat_ThumbWheelPos4" 3 "Thumbwheel_stat_ThumbWheelPos3" 2 "Thumbwheel_stat_ThumbWheelPos2" 1 "Thumbwheel_stat_ThumbWheelPos1" 0 "Thumbwheel_stat_ThumbWheelPos0" ;
VAL_ 393 EPBBackupMode 15 "EPBBackupMode_NotAvailable" 14 "EPBBackupMode_Error" 13 "EPBBackupMode_Level13" 12 "EPBBackupMode_Level12" 11 "EPBBackupMode_Level11" 10 "EPBBackupMode_Level10" 9 "EPBBackupMode_Level9" 8 "EPBBackupMode_Level8" 7 "EPBBackupMode_Level7" 6 "EPBBackupMode_Level6" 5 "EPBBackupMode_Level5" 4 "EPBBackupMode_Level4" 3 "EPBBackupMode_Level3" 2 "EPBBackupMode_Level2" 1 "EPBBackupMode_Level1" 0 "EPBBackupMode_Level0_NoBackUp" ;
VAL_ 393 BrakePedalTestState 15 "BrakePedalTestState_NotAvailable" 14 "BrakePedalTestState_Error" 13 "BrakePedalTestState_Spare_06" 12 "BrakePedalTestState_Spare_05" 11 "BrakePedalTestState_Spare_04" 10 "BrakePedalTestState_Spare_03" 9 "BrakePedalTestState_Spare_02" 8 "BrakePedalTestState_Spare_01" 7 "BrakePedalTestState_Spare" 6 "BrakePedalTestState_TestInterrIncorrOpByDrAtLeastOneActFault" 5 "BrakePedalTestState_TestWasCorrectlyOpByDrAtLeastOneActFault" 4 "BrakePedalTestState_TestWasCorrectlyOperatedByDrFaultDeleted" 3 "BrakePedalTestState_BrakePedalReleaseIsNeeded" 2 "BrakePedalTestState_FullBrakePedalActuationIsNeeded" 1 "BrakePedalTestState_TestIsNeededKeepBrakePedalReleased" 0 "BrakePedalTestState_BrakePedalTestIsNotNeeded" ;
VAL_ 393 DriverPresenceStatus 15 "DriverPresenceStatus_NotAvailable" 14 "DriverPresenceStatus_Error" 13 "DriverPresenceStatus_Spare8" 12 "DriverPresenceStatus_Spare7" 11 "DriverPresenceStatus_Spare6" 10 "DriverPresenceStatus_Spare5" 9 "DriverPresenceStatus_Spare4" 8 "DriverPresenceStatus_Spare3" 7 "DriverPresenceStatus_Spare2" 6 "DriverPresenceStatus_Spare1" 5 "DriverPresenceStatus_NoDriver" 4 "DriverPresenceStatus_DriverAtDriverSeat" 3 "DriverPresenceStatus_DriverOutOfCab" 2 "DriverPresenceStatus_DriverIntentToLeaveTheCab" 1 "DriverPresenceStatus_DriverInCab" 0 "DriverPresenceStatus_NotKnown" ;
VAL_ 393 ParkBrakeApplicationMode2 15 "ParkBrakeApplicationMode2_NotAvailable" 14 "ParkBrakeApplicationMode2_Error" 13 "ParkBrakeApplicationMode2_Reserved5" 12 "ParkBrakeApplicationMode2_Reserved4" 11 "ParkBrakeApplicationMode2_Reserved3" 10 "ParkBrakeApplicationMode2_Reserved2" 9 "ParkBrakeApplicationMode2_RedundantExternalDemand" 8 "ParkBrakeApplicationMode2_AutomaticcallyDoorOpen" 7 "ParkBrakeApplicationMode2_ParkBrakeBlending" 6 "ParkBrakeApplicationMode2_AutomaticallyHillHolder" 5 "ParkBrakeApplicationMode2_AutomaticInBackup" 4 "ParkBrakeApplicationMode2_MainExternalDemand" 3 "ParkBrakeApplicationMode2_AutomaticallyKeyOff" 2 "ParkBrakeApplicationMode2_ManuallyAtStandstill" 1 "ParkBrakeApplicationMode2_ManuallyInDriving" 0 "ParkBrakeApplicationMode2_Idle" ;
VAL_ 393 RampLevelStatus 15 "RampLevelStatus_NotAvaiable" 14 "RampLevelStatus_ErrorIndicator" 13 "RampLevelStatus_NotDefined_05" 12 "RampLevelStatus_NotDefined_04" 11 "RampLevelStatus_NotDefined_03" 10 "RampLevelStatus_NotDefined_02" 9 "RampLevelStatus_NotDefined_01" 8 "RampLevelStatus_NotDefined" 7 "RampLevelStatus_RampLevelM7" 6 "RampLevelStatus_RampLevelM6" 5 "RampLevelStatus_RampLevelM5" 4 "RampLevelStatus_RampLevelM4" 3 "RampLevelStatus_RampLevelM3" 2 "RampLevelStatus_RampLevelM2" 1 "RampLevelStatus_RampLevelM1" 0 "RampLevelStatus_Inactive" ;
VAL_ 393 ParkBrakeReleaseMode2 15 "ParkBrakeReleaseMode2_NotAvailable" 14 "ParkBrakeReleaseMode2_Error" 13 "ParkBrakeReleaseMode2_Reserved7" 12 "ParkBrakeReleaseMode2_Reserved6" 11 "ParkBrakeReleaseMode2_Reserved5" 10 "ParkBrakeReleaseMode2_Reserved4" 9 "ParkBrakeReleaseMode2_Reserved3" 8 "ParkBrakeReleaseMode2_Reserved2" 7 "ParkBrakeReleaseMode2_RedundantExternalDemand" 6 "ParkBrakeReleaseMode2_AutomaticallyinHillHolder" 5 "ParkBrakeReleaseMode2_AutomaticInBackup" 4 "ParkBrakeReleaseMode2_MainExternalDemand" 3 "ParkBrakeReleaseMode2_AutomaticallyAccelPedal" 2 "ParkBrakeReleaseMode2_ManuallyAtStandstill" 1 "ParkBrakeReleaseMode2_ManuallyInDriving" 0 "ParkBrakeReleaseMode2_Idle" ;
VAL_ 393 BackLightDimming_Status 31 "Thumbwheel_stat_NotAvaliable" 30 "Thumbwheel_stat_Error" 29 "Thumbwheel_stat_Spare_12" 28 "Thumbwheel_stat_Spare_11" 27 "Thumbwheel_stat_Spare_10" 26 "Thumbwheel_stat_Spare_09" 25 "Thumbwheel_stat_Spare_08" 24 "Thumbwheel_stat_Spare_07" 23 "Thumbwheel_stat_Spare_06" 22 "Thumbwheel_stat_Spare_05" 21 "Thumbwheel_stat_Spare_04" 20 "Thumbwheel_stat_Spare_03" 19 "Thumbwheel_stat_Spare_02" 18 "Thumbwheel_stat_Spare_01" 17 "Thumbwheel_stat_Spare" 16 "Thumbwheel_stat_ThumbWheelPos16" 15 "Thumbwheel_stat_ThumbWheelPos15" 14 "Thumbwheel_stat_ThumbWheelPos14" 13 "Thumbwheel_stat_ThumbWheelPos13" 12 "Thumbwheel_stat_ThumbWheelPos12" 11 "Thumbwheel_stat_ThumbWheelPos11" 10 "Thumbwheel_stat_ThumbWheelPos10" 9 "Thumbwheel_stat_ThumbWheelPos9" 8 "Thumbwheel_stat_ThumbWheelPos8" 7 "Thumbwheel_stat_ThumbWheelPos7" 6 "Thumbwheel_stat_ThumbWheelPos6" 5 "Thumbwheel_stat_ThumbWheelPos5" 4 "Thumbwheel_stat_ThumbWheelPos4" 3 "Thumbwheel_stat_ThumbWheelPos3" 2 "Thumbwheel_stat_ThumbWheelPos2" 1 "Thumbwheel_stat_ThumbWheelPos1" 0 "Thumbwheel_stat_ThumbWheelPos0" ;
VAL_ 393 HeightControlMode 15 "HeightControlMode_NotAvailable" 14 "HeightControlMode_ErrorIndicator" 13 "HeightControlMode_DumpFunction" 12 "HeightControlMode_FactorySupportMode" 11 "HeightControlMode_Calibration" 10 "HeightControlMode_Prohibit" 9 "HeightControlMode_FunctionTest" 8 "HeightControlMode_Stop" 7 "HeightControlMode_LimpHome" 6 "HeightControlMode_FerryFunction" 5 "HeightControlMode_KneelingHeight" 4 "HeightControlMode_DriveHeight" 3 "HeightControlMode_DockingRampHeight" 2 "HeightControlMode_HeightAdjustment" 1 "HeightControlMode_StartUpHeight" 0 "HeightControlMode_TakeNoAction" ;
VAL_ 393 FifthWheelLockingInformation 15 "FifthWheelLockingInformation_NotAvailable" 14 "FifthWheelLockingInformation_Error" 13 "FifthWheelLockingInformation_Spare_07" 12 "FifthWheelLockingInformation_Spare_06" 11 "FifthWheelLockingInformation_Spare_05" 10 "FifthWheelLockingInformation_Spare_04" 9 "FifthWheelLockingInformation_Spare_03" 8 "FifthWheelLockingInformation_Spare_02" 7 "FifthWheelLockingInformation_Spare_01" 6 "FifthWheelLockingInformation_Spare" 5 "FifthWheelLockingInformation_5thWheelSystemError" 4 "FifthWheelLockingInformation_TrailerNotCorrectlyCoupled" 3 "FifthWheelLockingInformation_HandleLockedTrailerRightConnected" 2 "FifthWheelLockingInformation_KingPinEndPosTrailerPlateInContact" 1 "FifthWheelLockingInformation_TrailerPlateInContactW_semitrailer" 0 "FifthWheelLockingInformation_TractorAlone" ;
VAL_ 392 FirstAxleLowerPrioSelected 7 "FirstAxleLowerPrio_NotAvailable" 6 "FirstAxleLowerPrio_Error" 5 "FirstAxleLowerPrio_Reserved_03" 4 "FirstAxleLowerPrio_Reserved_02" 3 "FirstAxleLowerPrio_Reserved_01" 2 "FirstAxleLowerPrio_Reserved" 1 "FirstAxleLowerPrio_LowerPusher" 0 "FirstAxleLowerPrio_LowerTag" ;
VAL_ 392 ESCState 7 "ESCState_NotAvailable" 6 "ESCState_Error" 5 "ESCState_Spare03" 4 "ESCState_Spare02" 3 "ESCState_Spare01" 2 "ESCState_Reduced" 1 "ESCState_On" 0 "ESCState_Off" ;
VAL_ 392 KneelingInformation 15 "KneelingInformation_NotAvailable" 14 "KneelingInformation_ErrorIndicator" 13 "KneelingInformation_NotDefined_08" 12 "KneelingInformation_NotDefined_07" 11 "KneelingInformation_NotDefined_06" 10 "KneelingInformation_NotDefined_05" 9 "KneelingInformation_NotDefined_04" 8 "KneelingInformation_NotDefined_03" 7 "KneelingInformation_NotDefined_02" 6 "KneelingInformation_NotDefined_01" 5 "KneelingInformation_NotDefined" 4 "KneelingInformation_KneelingAborted" 3 "KneelingInformation_LiftingActiveVehicleIsLiftedDueToRcvrReq" 2 "KneelingInformation_KneelLevelReachedVehicleIsAtFixeKneelLvl" 1 "KneelingInformation_LoweringActiveTheVehIsLoweredDueToKneelReq" 0 "KneelingInformation_NotActiveTheKneelingFunctionIsNotActive" ;
VAL_ 392 TrailerTest_stat 7 "TrailerTest_stat_NotAvailable" 6 "TrailerTest_stat_Error" 5 "TrailerTest_stat_InProgress_TrailerNotConnected" 4 "TrailerTest_stat_NotPossibleLowVoltgeOrLowPressure" 3 "TrailerTest_stat_TrailerTestIncentive" 2 "TrailerTest_stat_NotPossibleServiceBrakeApplied" 1 "TrailerTest_stat_InProgress" 0 "TrailerTest_stat_IdleNoTrailerTest" ;
VAL_ 392 ThreePosDifflockSwitch_stat 7 "A3PosSwitchStatus_NotAvailable" 6 "A3PosSwitchStatus_Error" 5 "A3PosSwitchStatus_Spare_02" 4 "A3PosSwitchStatus_Spare_01" 3 "A3PosSwitchStatus_Spare" 2 "A3PosSwitchStatus_Upper" 1 "A3PosSwitchStatus_Lower" 0 "A3PosSwitchStatus_Middle" ;
VAL_ 392 HillHolderMode 7 "HillHolderMode_NotAvailable" 6 "HillHolderMode_Reserved" 5 "HillHolderMode_Spare2" 4 "HillHolderMode_Spare1" 3 "HillHolderMode_OnHold_PressureApplied" 2 "HillHolderMode_Active_WillChangeToInactiveSoon" 1 "HillHolderMode_Active" 0 "HillHolderMode_Inactive" ;
VAL_ 392 RampHeightOutsideTargetRange 7 "HeightOutsideTargetRange_NotAvailable" 6 "HeightOutsideTargetRange_Error" 5 "HeightOutsideTargetRange_NotDefined_02" 4 "HeightOutsideTargetRange_NotDefined_01" 3 "HeightOutsideTargetRange_NotDefined" 2 "HeightOutsideTargetRange_ToHigh" 1 "HeightOutsideTargetRange_ToLow" 0 "HeightOutsideTargetRange_Inactive" ;
VAL_ 392 ShortStopHeater_status 7 "ShortStopHeaterStatus_NotAvailable" 6 "ShortStopHeaterStatus_Error" 5 "ShortStopHeaterStatus_Spare3" 4 "ShortStopHeaterStatus_Spare2" 3 "ShortStopHeaterStatus_Spare1" 2 "ShortStopHeaterStatus_ActivatedAndPumpNotEngaged" 1 "ShortStopHeaterStatus_ActivatedAndPumpEngaged" 0 "ShortStopHeaterStatus_NotActivated" ;
VAL_ 392 LuggageAjar_stat 7 "DoorAjar_stat_NotAvailable" 6 "DoorAjar_stat_Error" 2 "DoorAjar_stat_DoorOpen" 1 "DoorAjar_stat_DoorClosed" 0 "DoorAjar_stat_Idle" ;
VAL_ 392 LoadDistributionRequestedACK 7 "LoadDistributionRequestedACK_NotAvailable" 6 "LoadDistributionRequestedACK_Error" 5 "LoadDistributionRequestedACK_SystemDeniedVersatile" 4 "LoadDistributionRequestedACK_Reserved2" 3 "LoadDistributionRequestedACK_DeniedDueToDisengagedDifflock" 2 "LoadDistributionRequestedACK_LoadShiftDeniedFALIMOverload" 1 "LoadDistributionRequestedACK_ChangeAcknowledged" 0 "LoadDistributionRequestedACK_NoAction" ;
VAL_ 392 StretchBrake_Stat 7 "StretchBrake_Stat_NotAvailable" 6 "StretchBrake_Stat_Error" 5 "StretchBrake_Stat_Spare_02" 4 "StretchBrake_Stat_Spare_01" 3 "StretchBrake_Stat_Spare" 2 "StretchBrake_Stat_Active" 1 "StretchBrake_Stat_Enabled" 0 "StretchBrake_Stat_Disabled" ;
VAL_ 392 MirrorHeatingMode 7 "MirrorHeat_NotAvailable" 6 "MirrorHeat_ErrorIndicator" 5 "MirrorHeat_SpareValue_02" 4 "MirrorHeat_SpareValue_01" 3 "MirrorHeat_SpareValue" 2 "MirrorHeat_ONExtendedMode" 1 "MirrorHeat_ONNormalMode" 0 "MirrorHeat_OFF" ;
VAL_ 392 ESCStatus 7 "ESCStatus_NotAvailable" 6 "ESCStatus_Error" 5 "ESCStatus_PartlyMalfunctioning" 4 "ESCStatus_FullyMalfunctioning" 3 "ESCStatus_ESCOn" 2 "ESCStatus_Spare3" 1 "ESCStatus_ESCReduced" 0 "ESCStatus_ESCOff" ;
VAL_ 392 DriverRetarderRequest 7 "DriverRetarderRequest_NotAvailable" 6 "DriverRetarderRequest_Error" 5 "DriverRetarderRequest_Level5" 4 "DriverRetarderRequest_Level4" 3 "DriverRetarderRequest_Level3" 2 "DriverRetarderRequest_Level2" 1 "DriverRetarderRequest_Level1" 0 "DriverRetarderRequest_NoRequest" ;
VAL_ 392 PBReleaseAcceptance_stat 7 "PBReleaseAcceptance_stat_NotAvailable" 6 "PBReleaseAcceptance_stat_Error" 5 "PBReleaseAcceptance_stat_Spare_03" 4 "PBReleaseAcceptance_stat_AccelPedalOrHCURequested" 3 "PBReleaseAcceptance_stat_ReleaseRequestAccepted" 2 "PBReleaseAcceptance_stat_BrakeOrAccelPedalRequested" 1 "PBReleaseAcceptance_stat_BrakePedalRequested" 0 "PBReleaseAcceptance_stat_NoRequestDetectedOrRequestAborted" ;
VAL_ 392 PSWindowPosition 7 "WindowPosition_NotAvailable" 6 "WindowPosition_Error" 5 "WindowPosition_Spare" 4 "WindowPosition_UnknownPosition" 3 "WindowPosition_Open_70_100Percent" 2 "WindowPosition_Open_30_70Percent" 1 "WindowPosition_Open_0_30Percent" 0 "WindowPosition_Closed" ;
VAL_ 392 RemoteParkingClimateRqst 7 "RemoteParkingClimateRqst_NotAvailable" 6 "RemoteParkingClimateRqst_Error" 5 "RemoteParkingClimateRqst_Spare_03" 4 "RemoteParkingClimateRqst_Spare_02" 3 "RemoteParkingClimateRqst_Spare_01" 2 "RemoteParkingClimateRqst_DisableRequest" 1 "RemoteParkingClimateRqst_EnableRequest" 0 "RemoteParkingClimateRqst_NoAction" ;
VAL_ 392 AutoDefogmode_Status 7 "AutoDefogmode_NotAvailable" 6 "AutoDefogmode_Error" 5 "AutoDefogmode_Spare_01" 4 "AutoDefogmode_Spare" 3 "AutoDefogmode_Moderate" 2 "AutoDefogmode_Normal" 1 "AutoDefogmode_Sensitive" 0 "AutoDefogmode_OFF" ;
VAL_ 392 RideHeightOutsideTargetRange 7 "HeightOutsideTargetRange_NotAvailable" 6 "HeightOutsideTargetRange_Error" 5 "HeightOutsideTargetRange_NotDefined_02" 4 "HeightOutsideTargetRange_NotDefined_01" 3 "HeightOutsideTargetRange_NotDefined" 2 "HeightOutsideTargetRange_ToHigh" 1 "HeightOutsideTargetRange_ToLow" 0 "HeightOutsideTargetRange_Inactive" ;
VAL_ 392 DriveLevelPosUserInteraction 7 "DriveLevelPosUserInteraction_NotAvailable" 6 "DriveLevelPosUserInteraction_Error" 5 "DriveLevelPosUserInteraction_Spare3" 4 "DriveLevelPosUserInteraction_Spare2" 3 "DriveLevelPosUserInteraction_Spare1" 2 "DriveLevelPosUserInteraction_WarningDriveLevelPosNotSelected" 1 "DriveLevelPosUserInteraction_DriveLevelPositionNotSelected" 0 "DriveLevelPosUserInteraction_DriveLevelPositionSelected" ;
VAL_ 392 HillStartAidStatus 7 "HillStartAidStatus_NotAvailable" 6 "HillStartAidStatus_Error" 5 "HillStartAidStatus_NotDefined2" 4 "HillStartAidStatus_ActiveWithWarningHigh" 3 "HillStartAidStatus_ActiveWithWarningLow" 2 "HillStartAidStatus_ActiveButWillChangeToInactiveInAShortTime" 1 "HillStartAidStatus_Active" 0 "HillStartAidStatus_Inactive" ;
VAL_ 391 AcceleratorPedalTestStatus 7 "AcceleratorPedalTestStatus_NotAvailable" 6 "AcceleratorPedalTestStatus_Error" 5 "AcceleratorPedalTestStatus_TestFailed" 4 "AcceleratorPedalTestStatus_TestFinished" 3 "AcceleratorPedalTestStatus_Step3" 2 "AcceleratorPedalTestStatus_Step2" 1 "AcceleratorPedalTestStatus_Step1" 0 "AcceleratorPedalTestStatus_Inactive" ;
VAL_ 391 AutoDefogmode_Selection 7 "AutoDefogmode_NotAvailable" 6 "AutoDefogmode_Error" 5 "AutoDefogmode_Spare_01" 4 "AutoDefogmode_Spare" 3 "AutoDefogmode_Moderate" 2 "AutoDefogmode_Normal" 1 "AutoDefogmode_Sensitive" 0 "AutoDefogmode_OFF" ;
VAL_ 391 ESCDriverReq 7 "ESCDriverReq_NotAvailable" 6 "ESCDriverReq_Error" 5 "ESCDriverReq_Spare02" 4 "ESCDriverReq_Spare01" 3 "ESCDriverReq_ESCOn" 2 "ESCDriverReq_ESCReduced" 1 "ESCDriverReq_ESCOff" 0 "ESCDriverReq_NoRequest" ;
VAL_ 391 UnevenLoadWarning 3 "Warning_NotAvailable" 2 "Warning_Error" 1 "Warning_Warning" 0 "Warning_NoWarning" ;
VAL_ 391 RrInterAxlDiffLockActvnFuncReq 3 "DisengagedEngaged_NotAvailable" 2 "DisengagedEngaged_Error" 1 "DisengagedEngaged_Engaged" 0 "DisengagedEngaged_Disengaged" ;
VAL_ 391 DoorsAjar_stat 7 "DoorsAjar_stat_NotAvailable" 6 "DoorsAjar_stat_Error" 5 "DoorsAjar_stat_Spare" 4 "DoorsAjar_stat_BothDoorsAreOpen" 3 "DoorsAjar_stat_PassengerDoorIsOpen" 2 "DoorsAjar_stat_DriverDoorIsOpen" 1 "DoorsAjar_stat_BothDoorsAreClosed" 0 "DoorsAjar_stat_Idle" ;
VAL_ 391 ABSManAutoInhibitionStat 7 "ABSManAutoInhibitionStat_NotAvailable" 6 "ABSManAutoInhibitionStat_Error" 5 "ABSManAutoInhibitionStat_Spare02" 4 "ABSManAutoInhibitionStat_Spare01" 3 "ABSManAutoInhibitionStat_Spare" 2 "ABSManAutoInhibitionStat_ABSAutomaticInhibition" 1 "ABSManAutoInhibitionStat_ABSManualInhibition" 0 "ABSManAutoInhibitionStat_ABSNoInhibition" ;
VAL_ 391 RrInterAxlDiffLockActvnDrvrReq 3 "DisengageEngage_NotAvailable" 2 "DisengageEngage_Error" 1 "DisengageEngage_Engage" 0 "DisengageEngage_Disengage" ;
VAL_ 391 ACMode_Selection 7 "ACMode_NotAvailable" 6 "ACMode_Error" 5 "ACMode_Spare_01" 4 "ACMode_Spare" 3 "ACMode_ExtraDryCabAir" 2 "ACMode_HumidCabAir" 1 "ACMode_Standard" 0 "ACMode_Economy" ;
VAL_ 391 EngineOilTempHigh 7 "TempHigh3bit_NotAvailable" 6 "TempHigh3bit_Error" 5 "TempHigh3bit_HighLevel5" 4 "TempHigh3bit_HighLevel4" 3 "TempHigh3bit_HighLevel3" 2 "TempHigh3bit_HighLevel2" 1 "TempHigh3bit_HighLevel1" 0 "TempHigh3bit_OK" ;
VAL_ 391 StartupProhibitStatus 3 "InactiveActive_NotAvailable" 2 "InactiveActive_Error" 1 "InactiveActive_Active" 0 "InactiveActive_Inactive" ;
VAL_ 391 AuxBrakesDwngrdModeInd_rqst 7 "AuxBrakesDwngrdModeInd_rqst_NotAvailable" 6 "AuxBrakesDwngrdModeInd_rqst_Error" 5 "AuxBrakesDwngrdModeInd_rqst_Spare_3" 4 "AuxBrakesDwngrdModeInd_rqst_Spare_2" 3 "AuxBrakesDwngrdModeInd_rqst_Spare_1" 2 "AuxBrakesDwngrdModeInd_rqst_AuxiliaryBrakesShutdown" 1 "AuxBrakesDwngrdModeInd_rqst_ABSDowngradedMode" 0 "AuxBrakesDwngrdModeInd_rqst_NoRequest" ;
VAL_ 391 ElectricalLoadReduction_rqst 7 "ElectricalLoadReduction_rqst_NotAvailable" 6 "ElectricalLoadReduction_rqst_Error" 5 "ElectricalLoadReduction_rqst_SpareValue_02" 4 "ElectricalLoadReduction_rqst_SpareValue_01" 3 "ElectricalLoadReduction_rqst_SpareValue" 2 "ElectricalLoadReduction_rqst_Level2Request" 1 "ElectricalLoadReduction_rqst_Level1Request" 0 "ElectricalLoadReduction_rqst_NoRequest" ;
VAL_ 391 ACmode_Status 7 "ACMode_NotAvailable" 6 "ACMode_Error" 5 "ACMode_Spare_01" 4 "ACMode_Spare" 3 "ACMode_ExtraDryCabAir" 2 "ACMode_HumidCabAir" 1 "ACMode_Standard" 0 "ACMode_Economy" ;
VAL_ 391 LoadDistributionChangeACK 7 "LoadDistributionChangeACK_NotAvailable" 6 "LoadDistributionChangeACK_Error" 5 "LoadDistributionChangeACK_SystemDeniedVersatile" 4 "LoadDistributionChangeACK_Reserved_2" 3 "LoadDistributionChangeACK_DeniedDueToDisengagedDifflock" 2 "LoadDistributionChangeACK_LoadShiftDeniedFALIMOverload" 1 "LoadDistributionChangeACK_ChangeAcknowledged" 0 "LoadDistributionChangeACK_NoAction" ;
VAL_ 391 FerryFunctionStatus 7 "FerryFunctionStatus_NotAvailable" 6 "FerryFunctionStatus_Error" 5 "FerryFunctionStatus_Spare_03" 4 "FerryFunctionStatus_Spare_02" 3 "FerryFunctionStatus_Spare_01" 2 "FerryFunctionStatus_FerryFunctionActiveLeveNotlReached" 1 "FerryFunctionStatus_FerryFunctionActiveLevelReached" 0 "FerryFunctionStatus_FerryFunctionNotActive" ;
VAL_ 391 ClutchOverloadStatus 3 "ClutchOverloadStatus_NotAvailable" 2 "ClutchOverloadStatus_Error" 1 "ClutchOverloadStatus_Overloaded" 0 "ClutchOverloadStatus_NotOverloaded" ;
VAL_ 391 AutoBlowerLevel_Selection 7 "AutoBlowerLevel_NotAvailable" 6 "AutoBlowerLevel_Error" 5 "AutoBlowerLevel_Spare_02" 4 "AutoBlowerLevel_Spare_01" 3 "AutoBlowerLevel_Spare" 2 "AutoBlowerLevel_Low" 1 "AutoBlowerLevel_Normal" 0 "AutoBlowerLevel_High" ;
VAL_ 391 RollerBenchModeStatus 3 "InactiveActive_NotAvailable" 2 "InactiveActive_Error" 1 "InactiveActive_Active" 0 "InactiveActive_Inactive" ;
VAL_ 391 LoadDistributionALDChangeACK 7 "LoadDistributionALDChangeACK_NotAvailable" 6 "LoadDistributionALDChangeACK_Error" 5 "LoadDistributionALDChangeACK_SystemDeniedVersatile" 4 "LoadDistributionALDChangeACK_Spare_01" 3 "LoadDistributionALDChangeACK_Spare" 2 "LoadDistributionALDChangeACK_LoadShiftDeniedOverspeed" 1 "LoadDistributionALDChangeACK_ChangeAcknowledged" 0 "LoadDistributionALDChangeACK_NoAction" ;
VAL_ 391 EngineSpeedControlStatus 7 "EngineSpeedControlStatus_NotAvailable" 6 "EngineSpeedControlStatus_Error" 5 "EngineSpeedControlStatus_Spare_01" 4 "EngineSpeedControlStatus_AutoPtoMin_AutoNeutral" 3 "EngineSpeedControlStatus_CrossCountryEngineSpeedControlActive" 2 "EngineSpeedControlStatus_ActiveExternalSource" 1 "EngineSpeedControlStatus_ActiveManual" 0 "EngineSpeedControlStatus_Inactive" ;
VAL_ 391 AutoBlowerLevel_Status 7 "AutoBlowerLevel_NotAvailable" 6 "AutoBlowerLevel_Error" 5 "AutoBlowerLevel_Spare_02" 4 "AutoBlowerLevel_Spare_01" 3 "AutoBlowerLevel_Spare" 2 "AutoBlowerLevel_Low" 1 "AutoBlowerLevel_Normal" 0 "AutoBlowerLevel_High" ;
VAL_ 391 DTCActive 3 "DTCActive_DTCStatusInfoNotAvailableOrNotSupported" 2 "DTCActive_ErrorIndicator" 1 "DTCActive_DTCActive" 0 "DTCActive_DTCStatusInfoAvailableButNotActive" ;
VAL_ 390 PS_SevereEngAndBrkOverspdWarn 3 "InactiveActiveSpare_NotAvailable" 2 "InactiveActiveSpare_Spare" 1 "InactiveActiveSpare_Active" 0 "InactiveActiveSpare_Inactive" ;
VAL_ 390 RearFog_Indication 3 "DeviceIndication_SpareValue" 2 "DeviceIndication_Blink" 1 "DeviceIndication_On" 0 "DeviceIndication_Off" ;
VAL_ 390 SasAdaptationInProgress 3 "OffOn_NotAvailable" 2 "OffOn_Error" 1 "OffOn_On" 0 "OffOn_Off" ;
VAL_ 390 SplitBoxDifflockActvnDrvrRqst 3 "DisengageEngage_NotAvailable" 2 "DisengageEngage_Error" 1 "DisengageEngage_Engage" 0 "DisengageEngage_Disengage" ;
VAL_ 390 EcoRollActiveStatus 3 "InactiveActive_NotAvailable" 2 "InactiveActive_Error" 1 "InactiveActive_Active" 0 "InactiveActive_Inactive" ;
VAL_ 390 PloughLampModeStatus 3 "InactiveActive_NotAvailable" 2 "InactiveActive_Error" 1 "InactiveActive_Active" 0 "InactiveActive_Inactive" ;
VAL_ 390 RrRrItrWhlDiffLckActvnDrvrReq 3 "DisengagedEngaged_NotAvailable" 2 "DisengagedEngaged_Error" 1 "DisengagedEngaged_Engaged" 0 "DisengagedEngaged_Disengaged" ;
VAL_ 390 AQSMode_Selection 3 "AQSMode_NotAvailable" 2 "AQSMode_Error" 1 "AQSMode_Auto" 0 "AQSMode_OFF" ;
VAL_ 390 DrvrRetarderBrakeProgram_rqst 3 "OffOn_NotAvailable" 2 "OffOn_Error" 1 "OffOn_On" 0 "OffOn_Off" ;
VAL_ 390 PS_EngOverSpeedSevereWarning 3 "InactiveActiveSpare_NotAvailable" 2 "InactiveActiveSpare_Spare" 1 "InactiveActiveSpare_Active" 0 "InactiveActiveSpare_Inactive" ;
VAL_ 390 ParkBrakeReleasePossible_stat 3 "ParkBrakeReleasePossible_stat_NotAvailable" 2 "ParkBrakeReleasePossible_stat_Error" 1 "ParkBrakeReleasePossible_stat_Possible_PressureOK" 0 "ParkBrakeReleasePossible_stat_NotPossible_LowerPressure" ;
VAL_ 390 StoreIdleValue 3 "StoreIdleValue_NotAvailable" 2 "StoreIdleValue_Error" 1 "StoreIdleValue_StoreSetValue" 0 "StoreIdleValue_DoNOTStoreValue" ;
VAL_ 390 AutRrAxleDiffLockActvnDrvrReq 3 "DisengageEngage_NotAvailable" 2 "DisengageEngage_Error" 1 "DisengageEngage_Engage" 0 "DisengageEngage_Disengage" ;
VAL_ 390 TransmLowRangeSenseSwitch 3 "OffOn_NotAvailable" 2 "OffOn_Error" 1 "OffOn_On" 0 "OffOn_Off" ;
VAL_ 390 PBStatusDisplay_cmd 3 "DisableEnable_NotAvailable" 2 "DisableEnable_Error" 1 "DisableEnable_Enable" 0 "DisableEnable_Disable" ;
VAL_ 390 AutoRearAxleDiffLockFnc_stat 3 "InactiveActive_NotAvailable" 2 "InactiveActive_Error" 1 "InactiveActive_Active" 0 "InactiveActive_Inactive" ;
VAL_ 390 PoorBrakePerformanceWarning 3 "Warning_NotAvailable" 2 "Warning_Error" 1 "Warning_Warning" 0 "Warning_NoWarning" ;
VAL_ 390 AQSmode_Status 3 "AQSMode_NotAvailable" 2 "AQSMode_Error" 1 "AQSMode_Auto" 0 "AQSMode_OFF" ;
VAL_ 390 CCIOM_ParkBrakeAlert 3 "Alert_NotAvailable" 2 "Alert_Error" 1 "Alert_Alert" 0 "Alert_NoAlert" ;
VAL_ 390 FrontParkBrakeOverrideInd 3 "FrontParkBrakeOverrideInd_NotAvailable" 2 "FrontParkBrakeOverrideInd_Error" 1 "FrontParkBrakeOverrideInd_FailedToOverride" 0 "FrontParkBrakeOverrideInd_OK" ;
VAL_ 390 ProhibitControlStatus 3 "InactiveActive_NotAvailable" 2 "InactiveActive_Error" 1 "InactiveActive_Active" 0 "InactiveActive_Inactive" ;
VAL_ 390 PositionLightRequest_status 3 "OffOn_NotAvailable" 2 "OffOn_Error" 1 "OffOn_On" 0 "OffOn_Off" ;
VAL_ 390 DoubleFrontAxleSteeringWarning 3 "DoubleFrontAxleSteeringWarning_NotAvailiable" 2 "DoubleFrontAxleSteeringWarning_Error" 1 "DoubleFrontAxleSteeringWarning_DoubleFrAxleSteeringBackupMode" 0 "DoubleFrontAxleSteeringWarning_NoRequest" ;
VAL_ 390 TrailerABSStatus 3 "TrailerABSStatus_NotAvailable" 2 "TrailerABSStatus_ErrorIndicator" 1 "TrailerABSStatus_OK" 0 "TrailerABSStatus_Error" ;
VAL_ 390 LoadCutOffIndication_cmd 3 "LoadCutOffIndication_cmd_NotAvailable" 2 "LoadCutOffIndication_cmd_Error" 1 "LoadCutOffIndication_cmd_LoadCutOffIndication" 0 "LoadCutOffIndication_cmd_NoIndication" ;
VAL_ 390 PtosStatus 3 "PtosStatus_NotAvailable" 2 "PtosStatus_Error" 1 "PtosStatus_OneOrMorePTOEngaged" 0 "PtosStatus_NoPTOEngaged" ;
VAL_ 390 REM_PhoneButtonInd_cmd 3 "DeviceIndication_SpareValue" 2 "DeviceIndication_Blink" 1 "DeviceIndication_On" 0 "DeviceIndication_Off" ;
VAL_ 390 TrailerBrake_Stat 3 "InactiveActive_NotAvailable" 2 "InactiveActive_Error" 1 "InactiveActive_Active" 0 "InactiveActive_Inactive" ;
VAL_ 390 SEM2_PhoneButtonInd_cmd 3 "DeviceIndication_SpareValue" 2 "DeviceIndication_Blink" 1 "DeviceIndication_On" 0 "DeviceIndication_Off" ;
VAL_ 390 GearRangeUnengaged 3 "GearInhibation_NotAvailable" 2 "GearInhibation_Error" 1 "GearInhibation_GearChangeInhibited" 0 "GearInhibation_NoInhibation" ;
VAL_ 390 ABSOffRoadStatus 3 "OffOn_NotAvailable" 2 "OffOn_Error" 1 "OffOn_On" 0 "OffOn_Off" ;
VAL_ 390 DrvrRetarderBrakeBlending_rqst 3 "OffOn_NotAvailable" 2 "OffOn_Error" 1 "OffOn_On" 0 "OffOn_Off" ;
VAL_ 389 XPRGSystemCap_Priority 7 "XPRGPriority3bit_NotAvailable" 6 "XPRGPriority3bit_Error" 5 "XPRGPriority3bit_Spare2" 4 "XPRGPriority3bit_Spare1" 3 "XPRGPriority3bit_High" 2 "XPRGPriority3bit_Medium" 1 "XPRGPriority3bit_Normal" 0 "XPRGPriority3bit_NoPriority" ;
VAL_ 389 RearAxleDiffLockActvnDrvrReq 3 "DisengageEngage_NotAvailable" 2 "DisengageEngage_Error" 1 "DisengageEngage_Engage" 0 "DisengageEngage_Disengage" ;
VAL_ 389 FrRrItrWhlDiffLckActvnDrvrReq 3 "DisengagedEngaged_NotAvailable" 2 "DisengagedEngaged_Error" 1 "DisengagedEngaged_Engaged" 0 "DisengagedEngaged_Disengaged" ;
VAL_ 389 RegenInhibDueHeight 3 "Inhibit_NotAvailable" 2 "Inhibit_Error" 1 "Inhibit_InhibitActive" 0 "Inhibit_NoInhibit" ;
VAL_ 389 PoorAirPressureInfo 3 "PoorAirPressureInfo_NotAvailable" 2 "PoorAirPressureInfo_Error" 1 "PoorAirPressureInfo_PoorAirPressure" 0 "PoorAirPressureInfo_NormalPressure" ;
VAL_ 389 XRSLControllerMode 3 "InactiveActive_NotAvailable" 2 "InactiveActive_Error" 1 "InactiveActive_Active" 0 "InactiveActive_Inactive" ;
VAL_ 389 PHTimerRqstAck_DayOfWeekRq 15 "DayOfWeekRq_NotAvailable" 14 "DayOfWeekRq_Error" 13 "DayOfWeekRq_Spare_7" 12 "DayOfWeekRq_Spare_6" 11 "DayOfWeekRq_Spare_5" 10 "DayOfWeekRq_Spare_4" 9 "DayOfWeekRq_Spare_3" 8 "DayOfWeekRq_Spare_2" 7 "DayOfWeekRq_NoDay" 6 "DayOfWeekRq_Sunday" 5 "DayOfWeekRq_Saturday" 4 "DayOfWeekRq_Friday" 3 "DayOfWeekRq_Thursday" 2 "DayOfWeekRq_Wednesday" 1 "DayOfWeekRq_Tuesday" 0 "DayOfWeekRq_Monday" ;
VAL_ 389 PHTimerRqstAck_CurrentOp 3 "CurrentOp_NotAvailable" 2 "CurrentOp_Disabled" 1 "CurrentOp_TemporaryStopped" 0 "CurrentOp_Running" ;
VAL_ 389 PS_EngineBrakeOverSpeedWarning 3 "InactiveActiveSpare_NotAvailable" 2 "InactiveActiveSpare_Spare" 1 "InactiveActiveSpare_Active" 0 "InactiveActiveSpare_Inactive" ;
VAL_ 389 TrcnCtrlSlipperyRoadWarning 3 "InactiveActive_NotAvailable" 2 "InactiveActive_Error" 1 "InactiveActive_Active" 0 "InactiveActive_Inactive" ;
VAL_ 389 TransmissionAirPressureLow 3 "TransmissionAirPressureLow_NotAvailable" 2 "TransmissionAirPressureLow_Error" 1 "TransmissionAirPressureLow_AirPressureLow" 0 "TransmissionAirPressureLow_AirPressureOk" ;
VAL_ 158 SecuredNeutralPosition 3 "SecuredNeutralPosition_NotAvailable" 2 "SecuredNeutralPosition_Error" 1 "SecuredNeutralPosition_SecuredNeutralPosition" 0 "SecuredNeutralPosition_NotInSecuredNeutralPosition" ;
VAL_ 158 MirrorSelectLeftWideBtn_stat 3 "PushButtonStatus_NotAvailable" 2 "PushButtonStatus_Error" 1 "PushButtonStatus_Pushed" 0 "PushButtonStatus_Neutral" ;
VAL_ 158 Recirc_ButtonStatus 3 "PushButtonStatus_NotAvailable" 2 "PushButtonStatus_Error" 1 "PushButtonStatus_Pushed" 0 "PushButtonStatus_Neutral" ;
VAL_ 158 AirFlowSelectionUpBtn_stat 3 "PushButtonStatus_NotAvailable" 2 "PushButtonStatus_Error" 1 "PushButtonStatus_Pushed" 0 "PushButtonStatus_Neutral" ;
VAL_ 158 BunkH1AudioOnOff_ButtonStatus 3 "PushButtonStatus_NotAvailable" 2 "PushButtonStatus_Error" 1 "PushButtonStatus_Pushed" 0 "PushButtonStatus_Neutral" ;
VAL_ 158 AC_ButtonStatus 3 "PushButtonStatus_NotAvailable" 2 "PushButtonStatus_Error" 1 "PushButtonStatus_Pushed" 0 "PushButtonStatus_Neutral" ;
VAL_ 158 OverSteerGuidanceStatus 3 "InactiveActive_NotAvailable" 2 "InactiveActive_Error" 1 "InactiveActive_Active" 0 "InactiveActive_Inactive" ;
VAL_ 158 MirrorSelectLeftMainBtn_stat 3 "PushButtonStatus_NotAvailable" 2 "PushButtonStatus_Error" 1 "PushButtonStatus_Pushed" 0 "PushButtonStatus_Neutral" ;
VAL_ 158 LECM_CabClim_Auto_BtnStat 3 "PushButtonStatus_NotAvailable" 2 "PushButtonStatus_Error" 1 "PushButtonStatus_Pushed" 0 "PushButtonStatus_Neutral" ;
VAL_ 158 ParkBrakeAlert 3 "Alert_NotAvailable" 2 "Alert_Error" 1 "Alert_Alert" 0 "Alert_NoAlert" ;
VAL_ 158 LECM_Display_Navi_OK_BtnStat 3 "PushButtonStatus_NotAvailable" 2 "PushButtonStatus_Error" 1 "PushButtonStatus_Pushed" 0 "PushButtonStatus_Neutral" ;
VAL_ 158 LECM_CabClim_AC_BtnStat 3 "PushButtonStatus_NotAvailable" 2 "PushButtonStatus_Error" 1 "PushButtonStatus_Pushed" 0 "PushButtonStatus_Neutral" ;
VAL_ 158 LECMCabClimSetTempSelectGuiReq 3 "PushButtonStatus_NotAvailable" 2 "PushButtonStatus_Error" 1 "PushButtonStatus_Pushed" 0 "PushButtonStatus_Neutral" ;
VAL_ 158 MirrorSelectRightMainBtn_stat 3 "PushButtonStatus_NotAvailable" 2 "PushButtonStatus_Error" 1 "PushButtonStatus_Pushed" 0 "PushButtonStatus_Neutral" ;
VAL_ 158 DaytimeRunningLight_Indication 3 "DeviceIndication_SpareValue" 2 "DeviceIndication_Blink" 1 "DeviceIndication_On" 0 "DeviceIndication_Off" ;
VAL_ 158 DrivingLight_Indication 3 "DeviceIndication_SpareValue" 2 "DeviceIndication_Blink" 1 "DeviceIndication_On" 0 "DeviceIndication_Off" ;
VAL_ 158 FrontFog_Indication 3 "DeviceIndication_SpareValue" 2 "DeviceIndication_Blink" 1 "DeviceIndication_On" 0 "DeviceIndication_Off" ;
VAL_ 158 Auto_ButtonStatus 3 "PushButtonStatus_NotAvailable" 2 "PushButtonStatus_Error" 1 "PushButtonStatus_Pushed" 0 "PushButtonStatus_Neutral" ;
VAL_ 158 KeyfobPreTripButtonStatus 3 "PushButtonStatus_NotAvailable" 2 "PushButtonStatus_Error" 1 "PushButtonStatus_Pushed" 0 "PushButtonStatus_Neutral" ;
VAL_ 158 MirrorSelectRightWideBtn_stat 3 "PushButtonStatus_NotAvailable" 2 "PushButtonStatus_Error" 1 "PushButtonStatus_Pushed" 0 "PushButtonStatus_Neutral" ;
VAL_ 158 ParkingLight_Indication 3 "DeviceIndication_SpareValue" 2 "DeviceIndication_Blink" 1 "DeviceIndication_On" 0 "DeviceIndication_Off" ;
VAL_ 158 DrivingLightPlus_Indication 3 "DeviceIndication_SpareValue" 2 "DeviceIndication_Blink" 1 "DeviceIndication_On" 0 "DeviceIndication_Off" ;
VAL_ 158 BlackPanelMode_ButtonStatus 3 "PushButtonStatus_NotAvailable" 2 "PushButtonStatus_Error" 1 "PushButtonStatus_Pushed" 0 "PushButtonStatus_Neutral" ;
VAL_ 158 ParkHeaterCooler_ButtonStatus 3 "PushButtonStatus_NotAvailable" 2 "PushButtonStatus_Error" 1 "PushButtonStatus_Pushed" 0 "PushButtonStatus_Neutral" ;
VAL_ 158 LECM_CabClim_FrPwr_BtnStat 3 "PushButtonStatus_NotAvailable" 2 "PushButtonStatus_Error" 1 "PushButtonStatus_Pushed" 0 "PushButtonStatus_Neutral" ;
VAL_ 158 LECM_CabClim_Pwr_BtnStat 3 "PushButtonStatus_NotAvailable" 2 "PushButtonStatus_Error" 1 "PushButtonStatus_Pushed" 0 "PushButtonStatus_Neutral" ;
VAL_ 158 AirFlowSelectionFrontBtn_stat 3 "PushButtonStatus_NotAvailable" 2 "PushButtonStatus_Error" 1 "PushButtonStatus_Pushed" 0 "PushButtonStatus_Neutral" ;
VAL_ 158 BlackPanelMode_ButtonStatus3 3 "PushButtonStatus_NotAvailable" 2 "PushButtonStatus_Error" 1 "PushButtonStatus_Pushed" 0 "PushButtonStatus_Neutral" ;
VAL_ 158 LECM_CabClim_Sync_GuiReq 3 "PushButtonStatus_NotAvailable" 2 "PushButtonStatus_Error" 1 "PushButtonStatus_Pushed" 0 "PushButtonStatus_Neutral" ;
VAL_ 158 LiftAxle1AutoLiftSelected 3 "FalseTrue_NotAvaiable" 2 "FalseTrue_Error" 1 "FalseTrue_True" 0 "FalseTrue_False" ;
VAL_ 158 LECM_Ent_OnOff_BtnStat 3 "PushButtonStatus_NotAvailable" 2 "PushButtonStatus_Error" 1 "PushButtonStatus_Pushed" 0 "PushButtonStatus_Neutral" ;
SIG_GROUP_ 688 APMSafetyWarning_sg 1 : APMSafetyWarning_CRC APMSafetyWarning_RedRqst APMSafetyWarning_SqC APMSafetyWarning_YellowRqst;
SIG_GROUP_ 688 GearShiftingRec_sg 1 : GearShiftingRec_Steps GearShiftingRec_Direction;
SIG_GROUP_ 688 PBStatus_sg 1 : PBStatus_CRC PBStatus_Actuation PBStatus_IntegrityLvl PBStatus_SqC;
SIG_GROUP_ 688 RearPropulsionStat_sg 1 : RearPropulsionStat_Rear2Axle RearPropulsionStat_Rear1Axle RearPropulsionStat_Rear3Axle;
SIG_GROUP_ 389 XPRGSystemCap_sg 1 : XPRGSystemCap_Priority XPRGSystemCap_AllowedRelInhibit XPRGSystemCap_AllowedGradCtrlTc XPRGSystemCap_AllowedGradCtrlTl XPRGSystemCap_AllowedPBApp XPRGSystemCap_CRC XPRGSystemCap_AllowedInflation XPRGSystemCap_SqC XPRGSystemCap_AllowedDeflation XPRGSystemCap_AllowedInfInhibit XPRGSystemCap_AllowedPBRel;
SIG_GROUP_ 389 PHTimerRqstAck_sg 1 : PHTimerRqstAck_Minutes PHTimerRqstAck_Hours PHTimerRqstAck_DayOfWeekRq PHTimerRqstAck_CurrentOp;
